VERSION ""

NS_ :

BS_:

BU_: Pbox IVIBOX ADU Tbox Cooling GW

BO_ 640 GPS_Longitude: 8 Pbox
 SG_ Longitude_Value : 7|32@0+ (1E-07,-180) [-180|180] "deg"  IVIBOX
 SG_ LongitudeSequenceNumber : 35|4@0+ (1,0) [0|15] ""  IVIBOX

BO_ 641 GPS_Latitude: 8 Pbox
 SG_ Latitude_Value : 7|32@0+ (1E-07,-90) [-90|90] "deg"  IVIBOX
 SG_ LatitudeSequenceNumber : 35|4@0+ (1,0) [0|15] ""  IVIBOX

BO_ 642 GPS_Speed: 8 Pbox
 SG_ Speed_Value : 7|16@0+ (0.1,0) [0|6425.5] "m/s"  IVIBOX
 SG_ SpeedSequenceNumber : 35|4@0+ (1,0) [0|15] ""  IVIBOX

BO_ 643 GPS_Heading: 8 Pbox
 SG_ Heading_Value : 7|12@0+ (0.1,0) [0|360] "deg"  IVIBOX
 SG_ BearingSequenceNumber : 35|4@0+ (1,0) [0|15] ""  IVIBOX

BO_ 646 GPS_Location_State: 8 Pbox
 SG_ Location_State_Valid : 1|2@0+ (1,0) [0|3] ""  IVIBOX
 SG_ ValidSequenceNumber : 5|4@0+ (1,0) [0|15] ""  IVIBOX

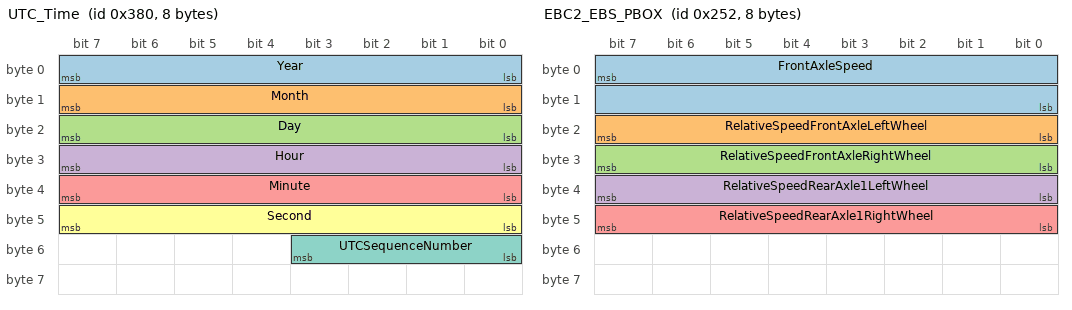
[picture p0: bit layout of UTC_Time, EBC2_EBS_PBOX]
BO_ 896 UTC_Time: 8 Pbox
 SG_ Year : 7|8@0+ (1,2000) [2000|2225] "Year"  IVIBOX,Tbox,Cooling,GW
 SG_ Month : 15|8@0+ (1,0) [1|12] "Month"  IVIBOX,Tbox,Cooling,GW
 SG_ Day : 23|8@0+ (1,0) [1|31] "Day"  IVIBOX,Tbox,Cooling,GW
 SG_ Hour : 31|8@0+ (1,0) [0|23] "Hour"  IVIBOX,Tbox,Cooling,GW
 SG_ Minute : 39|8@0+ (1,0) [0|59] "Minute"  IVIBOX,Tbox,Cooling,GW
 SG_ Second : 47|8@0+ (1,0) [0|59] "Second"  IVIBOX,Tbox,Cooling,GW
 SG_ UTCSequenceNumber : 51|4@0+ (1,0) [0|15] ""  IVIBOX,Tbox,Cooling,GW

BO_ 912 Vehicle_State_PBOX: 8 ADU
 SG_ TachographVehicleSpeed : 7|16@0+ (0.00390625,0) [0|250.996] "Km/h"  Pbox,IVIBOX,Tbox,Cooling

BO_ 592 ETC2_TCU_PBOX: 8 ADU
 SG_ ETC2_TrmCurrGr : 31|8@0+ (1,-125) [-125|125] "gear value"  Pbox,IVIBOX,Tbox

BO_ 593 VDC2_EBS_PBOX: 8 ADU
 SG_ SteeringWheelAngle : 7|16@0+ (0.0009765625,-31.374) [-31.374|31.374] "rad"  Pbox,IVIBOX
 SG_ YawRate : 23|16@0+ (0.0001220703125,-3.92) [-3.92|3.92] "rad/s"  Pbox,IVIBOX

BO_ 594 EBC2_EBS_PBOX: 8 ADU
 SG_ FrontAxleSpeed : 7|16@0+ (0.00390625,0) [0|250.996] "km/h"  Pbox,IVIBOX,Cooling
 SG_ RelativeSpeedFrontAxleLeftWheel : 23|8@0+ (0.0625,-7.8125) [-7.8125|7.8125] "km/h"  Pbox,IVIBOX
 SG_ RelativeSpeedFrontAxleRightWheel : 31|8@0+ (0.0625,-7.8125) [-7.8125|7.8125] "km/h"  Pbox,IVIBOX
 SG_ RelativeSpeedRearAxle1LeftWheel : 39|8@0+ (0.0625,-7.8125) [-7.8125|7.8125] "km/h"  Pbox,IVIBOX
 SG_ RelativeSpeedRearAxle1RightWheel : 47|8@0+ (0.0625,-7.8125) [-7.8125|7.8125] "km/h"  Pbox,IVIBOX

BO_ 913 VDHR_IC_PBOX: 8 ADU
 SG_ IC_HResolutionTotalVehiDist : 7|32@0+ (5,0) [0|21474836475] "m"  Pbox,IVIBOX,Tbox,Cooling

BO_ 981 SystemInfo: 8 Pbox
 SG_ MCUStartStatus : 2|3@0+ (1,0) [0|4] ""  ADU
 SG_ APStartStatus : 5|3@0+ (1,0) [0|4] ""  ADU
 SG_ PowerStatus : 7|2@0+ (1,0) [0|2] ""  ADU
 SG_ CANStatus : 8|1@0+ (1,0) [0|1] ""  ADU
 SG_ AntStatusM : 10|2@0+ (1,0) [0|2] ""  ADU
 SG_ AntPowerM : 11|1@0+ (1,0) [0|1] ""  ADU
 SG_ AntStatusS : 13|2@0+ (1,0) [0|2] ""  ADU
 SG_ AntPowerS : 14|1@0+ (1,0) [0|1] ""  ADU
 SG_ APStatus : 15|1@0+ (1,0) [0|1] ""  ADU
 SG_ EthLinkStatus : 17|2@0+ (1,0) [0|2] ""  ADU
 SG_ EthPhyStatus : 18|1@0+ (1,0) [0|1] ""  ADU
 SG_ ADUStatus : 19|1@0+ (1,0) [0|1] ""  ADU
 SG_ gPTPStatus : 20|1@0+ (1,0) [0|1] ""  ADU
 SG_ APTemperature : 31|8@0+ (1,-128) [-128|127] "℃"  ADU
 SG_ VolStatus : 39|12@0+ (1,0) [0|4095] ""  ADU
 SG_ RipleyMStatus : 52|5@0+ (1,0) [0|31] ""  ADU
 SG_ RipleySStatus : 41|5@0+ (1,0) [0|31] ""  ADU
 SG_ SystemInfo_RollingCounter : 63|4@0+ (1,0) [0|15] ""  ADU

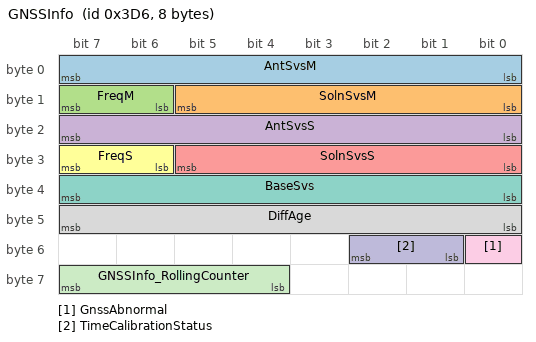
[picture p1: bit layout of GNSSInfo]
BO_ 982 GNSSInfo: 8 Pbox
 SG_ AntSvsM : 7|8@0+ (1,0) [0|255] ""  ADU
 SG_ SolnSvsM : 13|6@0+ (1,0) [0|63] ""  ADU
 SG_ FreqM : 15|2@0+ (1,0) [0|3] ""  ADU
 SG_ AntSvsS : 23|8@0+ (1,0) [0|255] ""  ADU
 SG_ SolnSvsS : 29|6@0+ (1,0) [0|63] ""  ADU
 SG_ FreqS : 31|2@0+ (1,0) [0|3] ""  ADU
 SG_ BaseSvs : 39|8@0+ (1,0) [0|255] ""  ADU
 SG_ DiffAge : 47|8@0+ (1,0) [0|255] "s"  ADU
 SG_ GnssAbnormal : 48|1@0+ (1,0) [0|1] ""  ADU
 SG_ TimeCalibrationStatus : 50|2@0+ (1,0) [0|2] ""  ADU
 SG_ GNSSInfo_RollingCounter : 63|4@0+ (1,0) [0|15] ""  ADU

BO_ 983 INSInfo: 8 Pbox
 SG_ InsResolve : 3|4@0+ (1,0) [0|11] ""  ADU
 SG_ InsAbnormal : 4|1@0+ (1,0) [0|1] ""  ADU
 SG_ ImuCali : 5|1@0+ (1,0) [0|1] ""  ADU
 SG_ ImuDataStatus_GYROX : 8|1@0+ (1,0) [0|1] ""  ADU
 SG_ ImuDataStatus_GYROY : 9|1@0+ (1,0) [0|1] ""  ADU
 SG_ ImuDataStatus_GYROZ : 10|1@0+ (1,0) [0|1] ""  ADU
 SG_ ImuDataStatus_ACCLX : 11|1@0+ (1,0) [0|1] ""  ADU
 SG_ ImuDataStatus_ACCLY : 12|1@0+ (1,0) [0|1] ""  ADU
 SG_ ImuDataStatus_ACCLZ : 13|1@0+ (1,0) [0|1] ""  ADU
 SG_ ImuDataStatus_TEMP : 14|1@0+ (1,0) [0|1] ""  ADU
 SG_ ImuDataStatus_TIME : 15|1@0+ (1,0) [0|1] ""  ADU
 SG_ ImuChipStatus : 23|8@0+ (1,0) [0|255] ""  ADU
 SG_ IMUTemperature : 31|8@0+ (1,-128) [-128|127] "℃"  ADU
 SG_ ImuFreq : 39|8@0+ (1,0) [0|255] ""  ADU
 SG_ ImuLostCnt : 47|8@0+ (1,0) [0|255] ""  ADU
 SG_ ImuErrCnt : 55|8@0+ (1,0) [0|255] ""  ADU
 SG_ INSInfo_RollingCounter : 63|4@0+ (1,0) [0|15] ""  ADU

CM_ "Version:V4.0.3,Date:2023.05.10,Author:xiuxiu.zhang,Review:,Approval:,Description:(Pbox)Pbox增加接收VDC2_EBS::YawRate；
增加接收EBC2_EBS::RelativeSpeedFrontAxleLeftWheel；
增加接收EBC2_EBS::RelativeSpeedFrontAxleRightWheel；
增加接收EBC2_EBS::RelativeSpeedRearAxle1LeftWheel；
增加接收EBC2_EBS::RelativeSpeedRearAxle1RightWheel；;
Version:V4.0.4,Date:2023.06.05,Author:xiuxiu.zhang,Review:,Approval:,Description:(Pbox)更新VDHR_IC的ID值为0x277，ADU发送，Cooling和Pbox接收;
Version:V4.0.4,Date:2023.06.05,Author:xiuxiu.zhang,Review:,Approval:,Description:(Pbox)Pbox增加接收Vehicle_State::TachographVehicleSpeed信号;
Version:V4.0.4,Date:2023.06.05,Author:xiuxiu.zhang,Review:,Approval:,Description:(Pbox)更新Pbox报文名称：GPS_Bearing更新为GPS_Heading，信号名称同步更改;
Version:V4.0.4,Date:2023.06.05,Author:xiuxiu.zhang,Review:,Approval:,Description:(Pbox)更新Pbox报文发送周期：GPS_Longitude、GPS_Latitude、GPS_Speed、GPS_Heading、GPS_Location_State由100ms更新为200ms;
Version:V4.0.4,Date:2023.06.05,Author:xiuxiu.zha";
CM_ SG_ 640 Longitude_Value "经度(东正西负)";
CM_ SG_ 640 LongitudeSequenceNumber "同步计数值";
CM_ SG_ 641 Latitude_Value "纬度（北正南负）";
CM_ SG_ 641 LatitudeSequenceNumber "同步计数值";
CM_ SG_ 642 Speed_Value "GPS车速";
CM_ SG_ 642 SpeedSequenceNumber "同步计数值";
CM_ SG_ 643 Heading_Value "前进方向（以真北为参考基准，顺时针为正）";
CM_ SG_ 643 BearingSequenceNumber "同步计数值";
CM_ SG_ 646 Location_State_Valid "定位有效性（含义取自GPRMC）";
CM_ SG_ 646 ValidSequenceNumber "同步计数值";
CM_ SG_ 896 UTCSequenceNumber "同步计数值";
CM_ SG_ 592 ETC2_TrmCurrGr "变速箱当前档位";
CM_ SG_ 594 RelativeSpeedFrontAxleLeftWheel "前轴左轮相对速度";
CM_ SG_ 594 RelativeSpeedFrontAxleRightWheel "前轴右轮相对速度";
CM_ SG_ 594 RelativeSpeedRearAxle1LeftWheel "后轴1左轮相对速度";
CM_ SG_ 594 RelativeSpeedRearAxle1RightWheel "后轴1右轮相对速度";
CM_ SG_ 913 IC_HResolutionTotalVehiDist "High Resolution Total Vehicle Distance1
高分辨率的总计里程1";
CM_ SG_ 981 MCUStartStatus "MCU启动状态";
CM_ SG_ 981 APStartStatus "AP启动状态";
CM_ SG_ 981 PowerStatus "供电状态";
CM_ SG_ 981 CANStatus "CAN通信状态";
CM_ SG_ 981 AntStatusM "主天线状态";
CM_ SG_ 981 AntPowerM "主天线供电状态";
CM_ SG_ 981 AntStatusS "从天线状态";
CM_ SG_ 981 AntPowerS "从天线供电状态";
CM_ SG_ 981 APStatus "AP工作状态";
CM_ SG_ 981 EthLinkStatus "以太网连接状态";
CM_ SG_ 981 EthPhyStatus "以太网PHY芯片状态";
CM_ SG_ 981 ADUStatus "ADU节点状态";
CM_ SG_ 981 gPTPStatus "gPTP时间同步状态";
CM_ SG_ 981 APTemperature "AP温度";
CM_ SG_ 981 VolStatus "内部电压检测状态";
CM_ SG_ 981 RipleyMStatus "主射频芯片状态";
CM_ SG_ 981 RipleySStatus "从射频芯片状态";
CM_ SG_ 981 SystemInfo_RollingCounter "报文计数";
CM_ SG_ 982 AntSvsM "主天线收星数";
CM_ SG_ 982 SolnSvsM "主天线参与解算卫星数";
CM_ SG_ 982 FreqM "主天线接收频点数";
CM_ SG_ 982 AntSvsS "从天线收星数";
CM_ SG_ 982 SolnSvsS "从天线参与解算卫星数";
CM_ SG_ 982 FreqS "从天线接收频点数";
CM_ SG_ 982 BaseSvs "基站卫星数";
CM_ SG_ 982 DiffAge "差分龄期";
CM_ SG_ 982 GnssAbnormal "Gnss状态";
CM_ SG_ 982 TimeCalibrationStatus "校时状态";
CM_ SG_ 982 GNSSInfo_RollingCounter "报文计数";
CM_ SG_ 983 InsResolve "Ins解算状态";
CM_ SG_ 983 InsAbnormal "Ins故障状态";
CM_ SG_ 983 ImuCali "IMU标定状态";
CM_ SG_ 983 ImuDataStatus_GYROX "IMU数据状态_陀螺仪X轴";
CM_ SG_ 983 ImuDataStatus_GYROY "IMU数据状态_陀螺仪Y轴";
CM_ SG_ 983 ImuDataStatus_GYROZ "IMU数据状态_陀螺仪Z轴";
CM_ SG_ 983 ImuDataStatus_ACCLX "IMU数据状态_加速度计X轴";
CM_ SG_ 983 ImuDataStatus_ACCLY "IMU数据状态_加速度计Y轴";
CM_ SG_ 983 ImuDataStatus_ACCLZ "IMU数据状态_加速度计Z轴";
CM_ SG_ 983 ImuDataStatus_TEMP "IMU数据状态_温度";
CM_ SG_ 983 ImuDataStatus_TIME "IMU数据状态_时间";
CM_ SG_ 983 ImuChipStatus "IMU芯片状态";
CM_ SG_ 983 IMUTemperature "IMU温度";
CM_ SG_ 983 ImuFreq "IMU数据频率";
CM_ SG_ 983 ImuLostCnt "IMU数据丢失计数";
CM_ SG_ 983 ImuErrCnt "IMU数据错误计数";
CM_ SG_ 983 INSInfo_RollingCounter "报文计数";
BA_DEF_ BO_  "GenMsgSendType" ENUM  "Cyclic","Event","IfActive","CE","CA","NoMsgSendType";
BA_DEF_ BO_  "GenMsgCycleTime" INT 0 0;
BA_DEF_ SG_  "GenSigSendType" ENUM  "Cyclic","OnChange","OnWrite","IfActive","OnChangeWithRepetition","OnWriteWithRepetition","IfActiveWithRepetition","NoSigSendType","OnChangeAndIfActive","OnChangeAndIfActiveWithRepetition","CA","CE","Event";
BA_DEF_ SG_  "GenSigStartValue" INT 0 0;
BA_DEF_  "DBName" STRING ;
BA_DEF_ BU_  "NodeLayerModules" STRING ;
BA_DEF_ BU_  "NmNode" ENUM  "Not","Yes";
BA_DEF_  "NmBaseAddress" HEX 0 2047;
BA_DEF_  "NmMessageCount" INT 0 255;
BA_DEF_  "BusType" STRING ;
BA_DEF_DEF_  "GenMsgSendType" "Cyclic";
BA_DEF_DEF_  "GenMsgCycleTime" 0;
BA_DEF_DEF_  "GenSigSendType" "Cyclic";
BA_DEF_DEF_  "GenSigStartValue" 0;
BA_DEF_DEF_  "DBName" "";
BA_DEF_DEF_  "NodeLayerModules" "CANoeILNLVector.dll";
BA_DEF_DEF_  "NmNode" "Not";
BA_DEF_DEF_  "NmBaseAddress" 1024;
BA_DEF_DEF_  "NmMessageCount" 128;
BA_DEF_DEF_  "BusType" "CAN";
BA_ "DBName" "CAN_Pbox";
BA_ "GenMsgCycleTime" BO_ 640 200;
BA_ "GenMsgCycleTime" BO_ 641 200;
BA_ "GenMsgCycleTime" BO_ 642 200;
BA_ "GenMsgCycleTime" BO_ 643 200;
BA_ "GenMsgCycleTime" BO_ 646 200;
BA_ "GenMsgCycleTime" BO_ 896 1000;
BA_ "GenMsgCycleTime" BO_ 912 200;
BA_ "GenMsgCycleTime" BO_ 592 100;
BA_ "GenMsgCycleTime" BO_ 593 20;
BA_ "GenMsgCycleTime" BO_ 594 100;
BA_ "GenMsgCycleTime" BO_ 913 200;
BA_ "GenMsgCycleTime" BO_ 981 1000;
BA_ "GenMsgCycleTime" BO_ 982 1000;
BA_ "GenMsgCycleTime" BO_ 983 1000;
BA_ "GenSigStartValue" SG_ 896 Month 1;
BA_ "GenSigStartValue" SG_ 896 Day 1;
BA_ "GenSigStartValue" SG_ 592 ETC2_TrmCurrGr 125;
BA_ "GenSigStartValue" SG_ 593 SteeringWheelAngle 32127;
BA_ "GenSigStartValue" SG_ 593 YawRate 32113;
BA_ "GenSigStartValue" SG_ 594 RelativeSpeedFrontAxleLeftWheel 125;
BA_ "GenSigStartValue" SG_ 594 RelativeSpeedFrontAxleRightWheel 125;
BA_ "GenSigStartValue" SG_ 594 RelativeSpeedRearAxle1LeftWheel 125;
BA_ "GenSigStartValue" SG_ 594 RelativeSpeedRearAxle1RightWheel 125;
VAL_ 640 Longitude_Value -1 "Invalid" ;
VAL_ 641 Latitude_Value -1 "Invalid" ;
VAL_ 642 Speed_Value 65535 "Invalid" ;
VAL_ 643 Heading_Value 4095 "Invalid" ;
VAL_ 646 Location_State_Valid 1 "Valid" 0 "Invalid" ;
VAL_ 981 MCUStartStatus 4 "MCU APP Init Finish, MCU APP is Working" 3 "MCU Power Up AP Finish" 2 "MCU APP Init Start" 1 "MCU BOOT Start Finish" 0 "Default" ;
VAL_ 981 APStartStatus 4 "AP is Working" 3 "AP App Start Finish" 2 "AP Image Start Finish" 1 "AP boot Start Finish" 0 "Default" ;
VAL_ 981 PowerStatus 2 "ECU Input Voltage too High" 1 "ECU Input Voltage too Low" 0 "Normal" ;
VAL_ 981 CANStatus 1 "DMI Data Lost" 0 "Normal" ;
VAL_ 981 AntStatusM 2 "Short" 1 "Open" 0 "Normal" ;
VAL_ 981 AntPowerM 1 "Abnormal" 0 "Normal" ;
VAL_ 981 AntStatusS 2 "Short" 1 "Open" 0 "Normal" ;
VAL_ 981 AntPowerS 1 "Abnormal" 0 "Normal" ;
VAL_ 981 APStatus 1 "AP Working Abnormally" 0 "Normal" ;
VAL_ 981 EthLinkStatus 2 "Short" 1 "Open" 0 "Normal" ;
VAL_ 981 EthPhyStatus 1 "Link Down" 0 "Normal" ;
VAL_ 981 ADUStatus 1 "ADU Node Lost" 0 "Normal" ;
VAL_ 981 gPTPStatus 1 "Abnormal" 0 "Normal" ;
VAL_ 981 VolStatus 4095 "Inside Voltage Abnormal" 4094 "Inside Voltage Abnormal" 4093 "Inside Voltage Abnormal" 4092 "Inside Voltage Abnormal" 4091 "Inside Voltage Abnormal" 4090 "Inside Voltage Abnormal" 4089 "Inside Voltage Abnormal" 4088 "Inside Voltage Abnormal" 4087 "Inside Voltage Abnormal" 4086 "Inside Voltage Abnormal" 4085 "Inside Voltage Abnormal" 4084 "Inside Voltage Abnormal" 4083 "Inside Voltage Abnormal" 4082 "Inside Voltage Abnormal" 4081 "Inside Voltage Abnormal" 4080 "Inside Voltage Abnormal" 4079 "Inside Voltage Abnormal" 4078 "Inside Voltage Abnormal" 4077 "Inside Voltage Abnormal" 4076 "Inside Voltage Abnormal" 4075 "Inside Voltage Abnormal" 4074 "Inside Voltage Abnormal" 4073 "Inside Voltage Abnormal" 4072 "Inside Voltage Abnormal" 4071 "Inside Voltage Abnormal" 4070 "Inside Voltage Abnormal" 4069 "Inside Voltage Abnormal" 4068 "Inside Voltage Abnormal" 4067 "Inside Voltage Abnormal" 4066 "Inside Voltage Abnormal" 4065 "Inside Voltage Abnormal" 4064 "Inside Voltage Abnormal" 4063 "Inside Voltage Abnormal" 4062 "Inside Voltage Abnormal" 4061 "Inside Voltage Abnormal" 4060 "Inside Voltage Abnormal" 4059 "Inside Voltage Abnormal" 4058 "Inside Voltage Abnormal" 4057 "Inside Voltage Abnormal" 4056 "Inside Voltage Abnormal" 4055 "Inside Voltage Abnormal" 4054 "Inside Voltage Abnormal" 4053 "Inside Voltage Abnormal" 4052 "Inside Voltage Abnormal" 4051 "Inside Voltage Abnormal" 4050 "Inside Voltage Abnormal" 4049 "Inside Voltage Abnormal" 4048 "Inside Voltage Abnormal" 4047 "Inside Voltage Abnormal" 4046 "Inside Voltage Abnormal" 4045 "Inside Voltage Abnormal" 4044 "Inside Voltage Abnormal" 4043 "Inside Voltage Abnormal" 4042 "Inside Voltage Abnormal" 4041 "Inside Voltage Abnormal" 4040 "Inside Voltage Abnormal" 4039 "Inside Voltage Abnormal" 4038 "Inside Voltage Abnormal" 4037 "Inside Voltage Abnormal" 4036 "Inside Voltage Abnormal" 4035 "Inside Voltage Abnormal" 4034 "Inside Voltage Abnormal" 4033 "Inside Voltage Abnormal" 4032 "Inside Voltage Abnormal" 4031 "Inside Voltage Abnormal" 4030 "Inside Voltage Abnormal" 4029 "Inside Voltage Abnormal" 4028 "Inside Voltage Abnormal" 4027 "Inside Voltage Abnormal" 4026 "Inside Voltage Abnormal" 4025 "Inside Voltage Abnormal" 4024 "Inside Voltage Abnormal" 4023 "Inside Voltage Abnormal" 4022 "Inside Voltage Abnormal" 4021 "Inside Voltage Abnormal" 4020 "Inside Voltage Abnormal" 4019 "Inside Voltage Abnormal" 4018 "Inside Voltage Abnormal" 4017 "Inside Voltage Abnormal" 4016 "Inside Voltage Abnormal" 4015 "Inside Voltage Abnormal" 4014 "Inside Voltage Abnormal" 4013 "Inside Voltage Abnormal" 4012 "Inside Voltage Abnormal" 4011 "Inside Voltage Abnormal" 4010 "Inside Voltage Abnormal" 4009 "Inside Voltage Abnormal" 4008 "Inside Voltage Abnormal" 4007 "Inside Voltage Abnormal" 4006 "Inside Voltage Abnormal" 4005 "Inside Voltage Abnormal" 4004 "Inside Voltage Abnormal" 4003 "Inside Voltage Abnormal" 4002 "Inside Voltage Abnormal" 4001 "Inside Voltage Abnormal" 4000 "Inside Voltage Abnormal" 3999 "Inside Voltage Abnormal" 3998 "Inside Voltage Abnormal" 3997 "Inside Voltage Abnormal" 3996 "Inside Voltage Abnormal" 3995 "Inside Voltage Abnormal" 3994 "Inside Voltage Abnormal" 3993 "Inside Voltage Abnormal" 3992 "Inside Voltage Abnormal" 3991 "Inside Voltage Abnormal" 3990 "Inside Voltage Abnormal" 3989 "Inside Voltage Abnormal" 3988 "Inside Voltage Abnormal" 3987 "Inside Voltage Abnormal" 3986 "Inside Voltage Abnormal" 3985 "Inside Voltage Abnormal" 3984 "Inside Voltage Abnormal" 3983 "Inside Voltage Abnormal" 3982 "Inside Voltage Abnormal" 3981 "Inside Voltage Abnormal" 3980 "Inside Voltage Abnormal" 3979 "Inside Voltage Abnormal" 3978 "Inside Voltage Abnormal" 3977 "Inside Voltage Abnormal" 3976 "Inside Voltage Abnormal" 3975 "Inside Voltage Abnormal" 3974 "Inside Voltage Abnormal" 3973 "Inside Voltage Abnormal" 3972 "Inside Voltage Abnormal" 3971 "Inside Voltage Abnormal" 3970 "Inside Voltage Abnormal" 3969 "Inside Voltage Abnormal" 3968 "Inside Voltage Abnormal" 3967 "Inside Voltage Abnormal" 3966 "Inside Voltage Abnormal" 3965 "Inside Voltage Abnormal" 3964 "Inside Voltage Abnormal" 3963 "Inside Voltage Abnormal" 3962 "Inside Voltage Abnormal" 3961 "Inside Voltage Abnormal" 3960 "Inside Voltage Abnormal" 3959 "Inside Voltage Abnormal" 3958 "Inside Voltage Abnormal" 3957 "Inside Voltage Abnormal" 3956 "Inside Voltage Abnormal" 3955 "Inside Voltage Abnormal" 3954 "Inside Voltage Abnormal" 3953 "Inside Voltage Abnormal" 3952 "Inside Voltage Abnormal" 3951 "Inside Voltage Abnormal" 3950 "Inside Voltage Abnormal" 3949 "Inside Voltage Abnormal" 3948 "Inside Voltage Abnormal" 3947 "Inside Voltage Abnormal" 3946 "Inside Voltage Abnormal" 3945 "Inside Voltage Abnormal" 3944 "Inside Voltage Abnormal" 3943 "Inside Voltage Abnormal" 3942 "Inside Voltage Abnormal" 3941 "Inside Voltage Abnormal" 3940 "Inside Voltage Abnormal" 3939 "Inside Voltage Abnormal" 3938 "Inside Voltage Abnormal" 3937 "Inside Voltage Abnormal" 3936 "Inside Voltage Abnormal" 3935 "Inside Voltage Abnormal" 3934 "Inside Voltage Abnormal" 3933 "Inside Voltage Abnormal" 3932 "Inside Voltage Abnormal" 3931 "Inside Voltage Abnormal" 3930 "Inside Voltage Abnormal" 3929 "Inside Voltage Abnormal" 3928 "Inside Voltage Abnormal" 3927 "Inside Voltage Abnormal" 3926 "Inside Voltage Abnormal" 3925 "Inside Voltage Abnormal" 3924 "Inside Voltage Abnormal" 3923 "Inside Voltage Abnormal" 3922 "Inside Voltage Abnormal" 3921 "Inside Voltage Abnormal" 3920 "Inside Voltage Abnormal" 3919 "Inside Voltage Abnormal" 3918 "Inside Voltage Abnormal" 3917 "Inside Voltage Abnormal" 3916 "Inside Voltage Abnormal" 3915 "Inside Voltage Abnormal" 3914 "Inside Voltage Abnormal" 3913 "Inside Voltage Abnormal" 3912 "Inside Voltage Abnormal" 3911 "Inside Voltage Abnormal" 3910 "Inside Voltage Abnormal" 3909 "Inside Voltage Abnormal" 3908 "Inside Voltage Abnormal" 3907 "Inside Voltage Abnormal" 3906 "Inside Voltage Abnormal" 3905 "Inside Voltage Abnormal" 3904 "Inside Voltage Abnormal" 3903 "Inside Voltage Abnormal" 3902 "Inside Voltage Abnormal" 3901 "Inside Voltage Abnormal" 3900 "Inside Voltage Abnormal" 3899 "Inside Voltage Abnormal" 3898 "Inside Voltage Abnormal" 3897 "Inside Voltage Abnormal" 3896 "Inside Voltage Abnormal" 3895 "Inside Voltage Abnormal" 3894 "Inside Voltage Abnormal" 3893 "Inside Voltage Abnormal" 3892 "Inside Voltage Abnormal" 3891 "Inside Voltage Abnormal" 3890 "Inside Voltage Abnormal" 3889 "Inside Voltage Abnormal" 3888 "Inside Voltage Abnormal" 3887 "Inside Voltage Abnormal" 3886 "Inside Voltage Abnormal" 3885 "Inside Voltage Abnormal" 3884 "Inside Voltage Abnormal" 3883 "Inside Voltage Abnormal" 3882 "Inside Voltage Abnormal" 3881 "Inside Voltage Abnormal" 3880 "Inside Voltage Abnormal" 3879 "Inside Voltage Abnormal" 3878 "Inside Voltage Abnormal" 3877 "Inside Voltage Abnormal" 3876 "Inside Voltage Abnormal" 3875 "Inside Voltage Abnormal" 3874 "Inside Voltage Abnormal" 3873 "Inside Voltage Abnormal" 3872 "Inside Voltage Abnormal" 3871 "Inside Voltage Abnormal" 3870 "Inside Voltage Abnormal" 3869 "Inside Voltage Abnormal" 3868 "Inside Voltage Abnormal" 3867 "Inside Voltage Abnormal" 3866 "Inside Voltage Abnormal" 3865 "Inside Voltage Abnormal" 3864 "Inside Voltage Abnormal" 3863 "Inside Voltage Abnormal" 3862 "Inside Voltage Abnormal" 3861 "Inside Voltage Abnormal" 3860 "Inside Voltage Abnormal" 3859 "Inside Voltage Abnormal" 3858 "Inside Voltage Abnormal" 3857 "Inside Voltage Abnormal" 3856 "Inside Voltage Abnormal" 3855 "Inside Voltage Abnormal" 3854 "Inside Voltage Abnormal" 3853 "Inside Voltage Abnormal" 3852 "Inside Voltage Abnormal" 3851 "Inside Voltage Abnormal" 3850 "Inside Voltage Abnormal" 3849 "Inside Voltage Abnormal" 3848 "Inside Voltage Abnormal" 3847 "Inside Voltage Abnormal" 3846 "Inside Voltage Abnormal" 3845 "Inside Voltage Abnormal" 3844 "Inside Voltage Abnormal" 3843 "Inside Voltage Abnormal" 3842 "Inside Voltage Abnormal" 3841 "Inside Voltage Abnormal" 3840 "Inside Voltage Abnormal" 3839 "Inside Voltage Abnormal" 3838 "Inside Voltage Abnormal" 3837 "Inside Voltage Abnormal" 3836 "Inside Voltage Abnormal" 3835 "Inside Voltage Abnormal" 3834 "Inside Voltage Abnormal" 3833 "Inside Voltage Abnormal" 3832 "Inside Voltage Abnormal" 3831 "Inside Voltage Abnormal" 3830 "Inside Voltage Abnormal" 3829 "Inside Voltage Abnormal" 3828 "Inside Voltage Abnormal" 3827 "Inside Voltage Abnormal" 3826 "Inside Voltage Abnormal" 3825 "Inside Voltage Abnormal" 3824 "Inside Voltage Abnormal" 3823 "Inside Voltage Abnormal" 3822 "Inside Voltage Abnormal" 3821 "Inside Voltage Abnormal" 3820 "Inside Voltage Abnormal" 3819 "Inside Voltage Abnormal" 3818 "Inside Voltage Abnormal" 3817 "Inside Voltage Abnormal" 3816 "Inside Voltage Abnormal" 3815 "Inside Voltage Abnormal" 3814 "Inside Voltage Abnormal" 3813 "Inside Voltage Abnormal" 3812 "Inside Voltage Abnormal" 3811 "Inside Voltage Abnormal" 3810 "Inside Voltage Abnormal" 3809 "Inside Voltage Abnormal" 3808 "Inside Voltage Abnormal" 3807 "Inside Voltage Abnormal" 3806 "Inside Voltage Abnormal" 3805 "Inside Voltage Abnormal" 3804 "Inside Voltage Abnormal" 3803 "Inside Voltage Abnormal" 3802 "Inside Voltage Abnormal" 3801 "Inside Voltage Abnormal" 3800 "Inside Voltage Abnormal" 3799 "Inside Voltage Abnormal" 3798 "Inside Voltage Abnormal" 3797 "Inside Voltage Abnormal" 3796 "Inside Voltage Abnormal" 3795 "Inside Voltage Abnormal" 3794 "Inside Voltage Abnormal" 3793 "Inside Voltage Abnormal" 3792 "Inside Voltage Abnormal" 3791 "Inside Voltage Abnormal" 3790 "Inside Voltage Abnormal" 3789 "Inside Voltage Abnormal" 3788 "Inside Voltage Abnormal" 3787 "Inside Voltage Abnormal" 3786 "Inside Voltage Abnormal" 3785 "Inside Voltage Abnormal" 3784 "Inside Voltage Abnormal" 3783 "Inside Voltage Abnormal" 3782 "Inside Voltage Abnormal" 3781 "Inside Voltage Abnormal" 3780 "Inside Voltage Abnormal" 3779 "Inside Voltage Abnormal" 3778 "Inside Voltage Abnormal" 3777 "Inside Voltage Abnormal" 3776 "Inside Voltage Abnormal" 3775 "Inside Voltage Abnormal" 3774 "Inside Voltage Abnormal" 3773 "Inside Voltage Abnormal" 3772 "Inside Voltage Abnormal" 3771 "Inside Voltage Abnormal" 3770 "Inside Voltage Abnormal" 3769 "Inside Voltage Abnormal" 3768 "Inside Voltage Abnormal" 3767 "Inside Voltage Abnormal" 3766 "Inside Voltage Abnormal" 3765 "Inside Voltage Abnormal" 3764 "Inside Voltage Abnormal" 3763 "Inside Voltage Abnormal" 3762 "Inside Voltage Abnormal" 3761 "Inside Voltage Abnormal" 3760 "Inside Voltage Abnormal" 3759 "Inside Voltage Abnormal" 3758 "Inside Voltage Abnormal" 3757 "Inside Voltage Abnormal" 3756 "Inside Voltage Abnormal" 3755 "Inside Voltage Abnormal" 3754 "Inside Voltage Abnormal" 3753 "Inside Voltage Abnormal" 3752 "Inside Voltage Abnormal" 3751 "Inside Voltage Abnormal" 3750 "Inside Voltage Abnormal" 3749 "Inside Voltage Abnormal" 3748 "Inside Voltage Abnormal" 3747 "Inside Voltage Abnormal" 3746 "Inside Voltage Abnormal" 3745 "Inside Voltage Abnormal" 3744 "Inside Voltage Abnormal" 3743 "Inside Voltage Abnormal" 3742 "Inside Voltage Abnormal" 3741 "Inside Voltage Abnormal" 3740 "Inside Voltage Abnormal" 3739 "Inside Voltage Abnormal" 3738 "Inside Voltage Abnormal" 3737 "Inside Voltage Abnormal" 3736 "Inside Voltage Abnormal" 3735 "Inside Voltage Abnormal" 3734 "Inside Voltage Abnormal" 3733 "Inside Voltage Abnormal" 3732 "Inside Voltage Abnormal" 3731 "Inside Voltage Abnormal" 3730 "Inside Voltage Abnormal" 3729 "Inside Voltage Abnormal" 3728 "Inside Voltage Abnormal" 3727 "Inside Voltage Abnormal" 3726 "Inside Voltage Abnormal" 3725 "Inside Voltage Abnormal" 3724 "Inside Voltage Abnormal" 3723 "Inside Voltage Abnormal" 3722 "Inside Voltage Abnormal" 3721 "Inside Voltage Abnormal" 3720 "Inside Voltage Abnormal" 3719 "Inside Voltage Abnormal" 3718 "Inside Voltage Abnormal" 3717 "Inside Voltage Abnormal" 3716 "Inside Voltage Abnormal" 3715 "Inside Voltage Abnormal" 3714 "Inside Voltage Abnormal" 3713 "Inside Voltage Abnormal" 3712 "Inside Voltage Abnormal" 3711 "Inside Voltage Abnormal" 3710 "Inside Voltage Abnormal" 3709 "Inside Voltage Abnormal" 3708 "Inside Voltage Abnormal" 3707 "Inside Voltage Abnormal" 3706 "Inside Voltage Abnormal" 3705 "Inside Voltage Abnormal" 3704 "Inside Voltage Abnormal" 3703 "Inside Voltage Abnormal" 3702 "Inside Voltage Abnormal" 3701 "Inside Voltage Abnormal" 3700 "Inside Voltage Abnormal" 3699 "Inside Voltage Abnormal" 3698 "Inside Voltage Abnormal" 3697 "Inside Voltage Abnormal" 3696 "Inside Voltage Abnormal" 3695 "Inside Voltage Abnormal" 3694 "Inside Voltage Abnormal" 3693 "Inside Voltage Abnormal" 3692 "Inside Voltage Abnormal" 3691 "Inside Voltage Abnormal" 3690 "Inside Voltage Abnormal" 3689 "Inside Voltage Abnormal" 3688 "Inside Voltage Abnormal" 3687 "Inside Voltage Abnormal" 3686 "Inside Voltage Abnormal" 3685 "Inside Voltage Abnormal" 3684 "Inside Voltage Abnormal" 3683 "Inside Voltage Abnormal" 3682 "Inside Voltage Abnormal" 3681 "Inside Voltage Abnormal" 3680 "Inside Voltage Abnormal" 3679 "Inside Voltage Abnormal" 3678 "Inside Voltage Abnormal" 3677 "Inside Voltage Abnormal" 3676 "Inside Voltage Abnormal" 3675 "Inside Voltage Abnormal" 3674 "Inside Voltage Abnormal" 3673 "Inside Voltage Abnormal" 3672 "Inside Voltage Abnormal" 3671 "Inside Voltage Abnormal" 3670 "Inside Voltage Abnormal" 3669 "Inside Voltage Abnormal" 3668 "Inside Voltage Abnormal" 3667 "Inside Voltage Abnormal" 3666 "Inside Voltage Abnormal" 3665 "Inside Voltage Abnormal" 3664 "Inside Voltage Abnormal" 3663 "Inside Voltage Abnormal" 3662 "Inside Voltage Abnormal" 3661 "Inside Voltage Abnormal" 3660 "Inside Voltage Abnormal" 3659 "Inside Voltage Abnormal" 3658 "Inside Voltage Abnormal" 3657 "Inside Voltage Abnormal" 3656 "Inside Voltage Abnormal" 3655 "Inside Voltage Abnormal" 3654 "Inside Voltage Abnormal" 3653 "Inside Voltage Abnormal" 3652 "Inside Voltage Abnormal" 3651 "Inside Voltage Abnormal" 3650 "Inside Voltage Abnormal" 3649 "Inside Voltage Abnormal" 3648 "Inside Voltage Abnormal" 3647 "Inside Voltage Abnormal" 3646 "Inside Voltage Abnormal" 3645 "Inside Voltage Abnormal" 3644 "Inside Voltage Abnormal" 3643 "Inside Voltage Abnormal" 3642 "Inside Voltage Abnormal" 3641 "Inside Voltage Abnormal" 3640 "Inside Voltage Abnormal" 3639 "Inside Voltage Abnormal" 3638 "Inside Voltage Abnormal" 3637 "Inside Voltage Abnormal" 3636 "Inside Voltage Abnormal" 3635 "Inside Voltage Abnormal" 3634 "Inside Voltage Abnormal" 3633 "Inside Voltage Abnormal" 3632 "Inside Voltage Abnormal" 3631 "Inside Voltage Abnormal" 3630 "Inside Voltage Abnormal" 3629 "Inside Voltage Abnormal" 3628 "Inside Voltage Abnormal" 3627 "Inside Voltage Abnormal" 3626 "Inside Voltage Abnormal" 3625 "Inside Voltage Abnormal" 3624 "Inside Voltage Abnormal" 3623 "Inside Voltage Abnormal" 3622 "Inside Voltage Abnormal" 3621 "Inside Voltage Abnormal" 3620 "Inside Voltage Abnormal" 3619 "Inside Voltage Abnormal" 3618 "Inside Voltage Abnormal" 3617 "Inside Voltage Abnormal" 3616 "Inside Voltage Abnormal" 3615 "Inside Voltage Abnormal" 3614 "Inside Voltage Abnormal" 3613 "Inside Voltage Abnormal" 3612 "Inside Voltage Abnormal" 3611 "Inside Voltage Abnormal" 3610 "Inside Voltage Abnormal" 3609 "Inside Voltage Abnormal" 3608 "Inside Voltage Abnormal" 3607 "Inside Voltage Abnormal" 3606 "Inside Voltage Abnormal" 3605 "Inside Voltage Abnormal" 3604 "Inside Voltage Abnormal" 3603 "Inside Voltage Abnormal" 3602 "Inside Voltage Abnormal" 3601 "Inside Voltage Abnormal" 3600 "Inside Voltage Abnormal" 3599 "Inside Voltage Abnormal" 3598 "Inside Voltage Abnormal" 3597 "Inside Voltage Abnormal" 3596 "Inside Voltage Abnormal" 3595 "Inside Voltage Abnormal" 3594 "Inside Voltage Abnormal" 3593 "Inside Voltage Abnormal" 3592 "Inside Voltage Abnormal" 3591 "Inside Voltage Abnormal" 3590 "Inside Voltage Abnormal" 3589 "Inside Voltage Abnormal" 3588 "Inside Voltage Abnormal" 3587 "Inside Voltage Abnormal" 3586 "Inside Voltage Abnormal" 3585 "Inside Voltage Abnormal" 3584 "Inside Voltage Abnormal" 3583 "Inside Voltage Abnormal" 3582 "Inside Voltage Abnormal" 3581 "Inside Voltage Abnormal" 3580 "Inside Voltage Abnormal" 3579 "Inside Voltage Abnormal" 3578 "Inside Voltage Abnormal" 3577 "Inside Voltage Abnormal" 3576 "Inside Voltage Abnormal" 3575 "Inside Voltage Abnormal" 3574 "Inside Voltage Abnormal" 3573 "Inside Voltage Abnormal" 3572 "Inside Voltage Abnormal" 3571 "Inside Voltage Abnormal" 3570 "Inside Voltage Abnormal" 3569 "Inside Voltage Abnormal" 3568 "Inside Voltage Abnormal" 3567 "Inside Voltage Abnormal" 3566 "Inside Voltage Abnormal" 3565 "Inside Voltage Abnormal" 3564 "Inside Voltage Abnormal" 3563 "Inside Voltage Abnormal" 3562 "Inside Voltage Abnormal" 3561 "Inside Voltage Abnormal" 3560 "Inside Voltage Abnormal" 3559 "Inside Voltage Abnormal" 3558 "Inside Voltage Abnormal" 3557 "Inside Voltage Abnormal" 3556 "Inside Voltage Abnormal" 3555 "Inside Voltage Abnormal" 3554 "Inside Voltage Abnormal" 3553 "Inside Voltage Abnormal" 3552 "Inside Voltage Abnormal" 3551 "Inside Voltage Abnormal" 3550 "Inside Voltage Abnormal" 3549 "Inside Voltage Abnormal" 3548 "Inside Voltage Abnormal" 3547 "Inside Voltage Abnormal" 3546 "Inside Voltage Abnormal" 3545 "Inside Voltage Abnormal" 3544 "Inside Voltage Abnormal" 3543 "Inside Voltage Abnormal" 3542 "Inside Voltage Abnormal" 3541 "Inside Voltage Abnormal" 3540 "Inside Voltage Abnormal" 3539 "Inside Voltage Abnormal" 3538 "Inside Voltage Abnormal" 3537 "Inside Voltage Abnormal" 3536 "Inside Voltage Abnormal" 3535 "Inside Voltage Abnormal" 3534 "Inside Voltage Abnormal" 3533 "Inside Voltage Abnormal" 3532 "Inside Voltage Abnormal" 3531 "Inside Voltage Abnormal" 3530 "Inside Voltage Abnormal" 3529 "Inside Voltage Abnormal" 3528 "Inside Voltage Abnormal" 3527 "Inside Voltage Abnormal" 3526 "Inside Voltage Abnormal" 3525 "Inside Voltage Abnormal" 3524 "Inside Voltage Abnormal" 3523 "Inside Voltage Abnormal" 3522 "Inside Voltage Abnormal" 3521 "Inside Voltage Abnormal" 3520 "Inside Voltage Abnormal" 3519 "Inside Voltage Abnormal" 3518 "Inside Voltage Abnormal" 3517 "Inside Voltage Abnormal" 3516 "Inside Voltage Abnormal" 3515 "Inside Voltage Abnormal" 3514 "Inside Voltage Abnormal" 3513 "Inside Voltage Abnormal" 3512 "Inside Voltage Abnormal" 3511 "Inside Voltage Abnormal" 3510 "Inside Voltage Abnormal" 3509 "Inside Voltage Abnormal" 3508 "Inside Voltage Abnormal" 3507 "Inside Voltage Abnormal" 3506 "Inside Voltage Abnormal" 3505 "Inside Voltage Abnormal" 3504 "Inside Voltage Abnormal" 3503 "Inside Voltage Abnormal" 3502 "Inside Voltage Abnormal" 3501 "Inside Voltage Abnormal" 3500 "Inside Voltage Abnormal" 3499 "Inside Voltage Abnormal" 3498 "Inside Voltage Abnormal" 3497 "Inside Voltage Abnormal" 3496 "Inside Voltage Abnormal" 3495 "Inside Voltage Abnormal" 3494 "Inside Voltage Abnormal" 3493 "Inside Voltage Abnormal" 3492 "Inside Voltage Abnormal" 3491 "Inside Voltage Abnormal" 3490 "Inside Voltage Abnormal" 3489 "Inside Voltage Abnormal" 3488 "Inside Voltage Abnormal" 3487 "Inside Voltage Abnormal" 3486 "Inside Voltage Abnormal" 3485 "Inside Voltage Abnormal" 3484 "Inside Voltage Abnormal" 3483 "Inside Voltage Abnormal" 3482 "Inside Voltage Abnormal" 3481 "Inside Voltage Abnormal" 3480 "Inside Voltage Abnormal" 3479 "Inside Voltage Abnormal" 3478 "Inside Voltage Abnormal" 3477 "Inside Voltage Abnormal" 3476 "Inside Voltage Abnormal" 3475 "Inside Voltage Abnormal" 3474 "Inside Voltage Abnormal" 3473 "Inside Voltage Abnormal" 3472 "Inside Voltage Abnormal" 3471 "Inside Voltage Abnormal" 3470 "Inside Voltage Abnormal" 3469 "Inside Voltage Abnormal" 3468 "Inside Voltage Abnormal" 3467 "Inside Voltage Abnormal" 3466 "Inside Voltage Abnormal" 3465 "Inside Voltage Abnormal" 3464 "Inside Voltage Abnormal" 3463 "Inside Voltage Abnormal" 3462 "Inside Voltage Abnormal" 3461 "Inside Voltage Abnormal" 3460 "Inside Voltage Abnormal" 3459 "Inside Voltage Abnormal" 3458 "Inside Voltage Abnormal" 3457 "Inside Voltage Abnormal" 3456 "Inside Voltage Abnormal" 3455 "Inside Voltage Abnormal" 3454 "Inside Voltage Abnormal" 3453 "Inside Voltage Abnormal" 3452 "Inside Voltage Abnormal" 3451 "Inside Voltage Abnormal" 3450 "Inside Voltage Abnormal" 3449 "Inside Voltage Abnormal" 3448 "Inside Voltage Abnormal" 3447 "Inside Voltage Abnormal" 3446 "Inside Voltage Abnormal" 3445 "Inside Voltage Abnormal" 3444 "Inside Voltage Abnormal" 3443 "Inside Voltage Abnormal" 3442 "Inside Voltage Abnormal" 3441 "Inside Voltage Abnormal" 3440 "Inside Voltage Abnormal" 3439 "Inside Voltage Abnormal" 3438 "Inside Voltage Abnormal" 3437 "Inside Voltage Abnormal" 3436 "Inside Voltage Abnormal" 3435 "Inside Voltage Abnormal" 3434 "Inside Voltage Abnormal" 3433 "Inside Voltage Abnormal" 3432 "Inside Voltage Abnormal" 3431 "Inside Voltage Abnormal" 3430 "Inside Voltage Abnormal" 3429 "Inside Voltage Abnormal" 3428 "Inside Voltage Abnormal" 3427 "Inside Voltage Abnormal" 3426 "Inside Voltage Abnormal" 3425 "Inside Voltage Abnormal" 3424 "Inside Voltage Abnormal" 3423 "Inside Voltage Abnormal" 3422 "Inside Voltage Abnormal" 3421 "Inside Voltage Abnormal" 3420 "Inside Voltage Abnormal" 3419 "Inside Voltage Abnormal" 3418 "Inside Voltage Abnormal" 3417 "Inside Voltage Abnormal" 3416 "Inside Voltage Abnormal" 3415 "Inside Voltage Abnormal" 3414 "Inside Voltage Abnormal" 3413 "Inside Voltage Abnormal" 3412 "Inside Voltage Abnormal" 3411 "Inside Voltage Abnormal" 3410 "Inside Voltage Abnormal" 3409 "Inside Voltage Abnormal" 3408 "Inside Voltage Abnormal" 3407 "Inside Voltage Abnormal" 3406 "Inside Voltage Abnormal" 3405 "Inside Voltage Abnormal" 3404 "Inside Voltage Abnormal" 3403 "Inside Voltage Abnormal" 3402 "Inside Voltage Abnormal" 3401 "Inside Voltage Abnormal" 3400 "Inside Voltage Abnormal" 3399 "Inside Voltage Abnormal" 3398 "Inside Voltage Abnormal" 3397 "Inside Voltage Abnormal" 3396 "Inside Voltage Abnormal" 3395 "Inside Voltage Abnormal" 3394 "Inside Voltage Abnormal" 3393 "Inside Voltage Abnormal" 3392 "Inside Voltage Abnormal" 3391 "Inside Voltage Abnormal" 3390 "Inside Voltage Abnormal" 3389 "Inside Voltage Abnormal" 3388 "Inside Voltage Abnormal" 3387 "Inside Voltage Abnormal" 3386 "Inside Voltage Abnormal" 3385 "Inside Voltage Abnormal" 3384 "Inside Voltage Abnormal" 3383 "Inside Voltage Abnormal" 3382 "Inside Voltage Abnormal" 3381 "Inside Voltage Abnormal" 3380 "Inside Voltage Abnormal" 3379 "Inside Voltage Abnormal" 3378 "Inside Voltage Abnormal" 3377 "Inside Voltage Abnormal" 3376 "Inside Voltage Abnormal" 3375 "Inside Voltage Abnormal" 3374 "Inside Voltage Abnormal" 3373 "Inside Voltage Abnormal" 3372 "Inside Voltage Abnormal" 3371 "Inside Voltage Abnormal" 3370 "Inside Voltage Abnormal" 3369 "Inside Voltage Abnormal" 3368 "Inside Voltage Abnormal" 3367 "Inside Voltage Abnormal" 3366 "Inside Voltage Abnormal" 3365 "Inside Voltage Abnormal" 3364 "Inside Voltage Abnormal" 3363 "Inside Voltage Abnormal" 3362 "Inside Voltage Abnormal" 3361 "Inside Voltage Abnormal" 3360 "Inside Voltage Abnormal" 3359 "Inside Voltage Abnormal" 3358 "Inside Voltage Abnormal" 3357 "Inside Voltage Abnormal" 3356 "Inside Voltage Abnormal" 3355 "Inside Voltage Abnormal" 3354 "Inside Voltage Abnormal" 3353 "Inside Voltage Abnormal" 3352 "Inside Voltage Abnormal" 3351 "Inside Voltage Abnormal" 3350 "Inside Voltage Abnormal" 3349 "Inside Voltage Abnormal" 3348 "Inside Voltage Abnormal" 3347 "Inside Voltage Abnormal" 3346 "Inside Voltage Abnormal" 3345 "Inside Voltage Abnormal" 3344 "Inside Voltage Abnormal" 3343 "Inside Voltage Abnormal" 3342 "Inside Voltage Abnormal" 3341 "Inside Voltage Abnormal" 3340 "Inside Voltage Abnormal" 3339 "Inside Voltage Abnormal" 3338 "Inside Voltage Abnormal" 3337 "Inside Voltage Abnormal" 3336 "Inside Voltage Abnormal" 3335 "Inside Voltage Abnormal" 3334 "Inside Voltage Abnormal" 3333 "Inside Voltage Abnormal" 3332 "Inside Voltage Abnormal" 3331 "Inside Voltage Abnormal" 3330 "Inside Voltage Abnormal" 3329 "Inside Voltage Abnormal" 3328 "Inside Voltage Abnormal" 3327 "Inside Voltage Abnormal" 3326 "Inside Voltage Abnormal" 3325 "Inside Voltage Abnormal" 3324 "Inside Voltage Abnormal" 3323 "Inside Voltage Abnormal" 3322 "Inside Voltage Abnormal" 3321 "Inside Voltage Abnormal" 3320 "Inside Voltage Abnormal" 3319 "Inside Voltage Abnormal" 3318 "Inside Voltage Abnormal" 3317 "Inside Voltage Abnormal" 3316 "Inside Voltage Abnormal" 3315 "Inside Voltage Abnormal" 3314 "Inside Voltage Abnormal" 3313 "Inside Voltage Abnormal" 3312 "Inside Voltage Abnormal" 3311 "Inside Voltage Abnormal" 3310 "Inside Voltage Abnormal" 3309 "Inside Voltage Abnormal" 3308 "Inside Voltage Abnormal" 3307 "Inside Voltage Abnormal" 3306 "Inside Voltage Abnormal" 3305 "Inside Voltage Abnormal" 3304 "Inside Voltage Abnormal" 3303 "Inside Voltage Abnormal" 3302 "Inside Voltage Abnormal" 3301 "Inside Voltage Abnormal" 3300 "Inside Voltage Abnormal" 3299 "Inside Voltage Abnormal" 3298 "Inside Voltage Abnormal" 3297 "Inside Voltage Abnormal" 3296 "Inside Voltage Abnormal" 3295 "Inside Voltage Abnormal" 3294 "Inside Voltage Abnormal" 3293 "Inside Voltage Abnormal" 3292 "Inside Voltage Abnormal" 3291 "Inside Voltage Abnormal" 3290 "Inside Voltage Abnormal" 3289 "Inside Voltage Abnormal" 3288 "Inside Voltage Abnormal" 3287 "Inside Voltage Abnormal" 3286 "Inside Voltage Abnormal" 3285 "Inside Voltage Abnormal" 3284 "Inside Voltage Abnormal" 3283 "Inside Voltage Abnormal" 3282 "Inside Voltage Abnormal" 3281 "Inside Voltage Abnormal" 3280 "Inside Voltage Abnormal" 3279 "Inside Voltage Abnormal" 3278 "Inside Voltage Abnormal" 3277 "Inside Voltage Abnormal" 3276 "Inside Voltage Abnormal" 3275 "Inside Voltage Abnormal" 3274 "Inside Voltage Abnormal" 3273 "Inside Voltage Abnormal" 3272 "Inside Voltage Abnormal" 3271 "Inside Voltage Abnormal" 3270 "Inside Voltage Abnormal" 3269 "Inside Voltage Abnormal" 3268 "Inside Voltage Abnormal" 3267 "Inside Voltage Abnormal" 3266 "Inside Voltage Abnormal" 3265 "Inside Voltage Abnormal" 3264 "Inside Voltage Abnormal" 3263 "Inside Voltage Abnormal" 3262 "Inside Voltage Abnormal" 3261 "Inside Voltage Abnormal" 3260 "Inside Voltage Abnormal" 3259 "Inside Voltage Abnormal" 3258 "Inside Voltage Abnormal" 3257 "Inside Voltage Abnormal" 3256 "Inside Voltage Abnormal" 3255 "Inside Voltage Abnormal" 3254 "Inside Voltage Abnormal" 3253 "Inside Voltage Abnormal" 3252 "Inside Voltage Abnormal" 3251 "Inside Voltage Abnormal" 3250 "Inside Voltage Abnormal" 3249 "Inside Voltage Abnormal" 3248 "Inside Voltage Abnormal" 3247 "Inside Voltage Abnormal" 3246 "Inside Voltage Abnormal" 3245 "Inside Voltage Abnormal" 3244 "Inside Voltage Abnormal" 3243 "Inside Voltage Abnormal" 3242 "Inside Voltage Abnormal" 3241 "Inside Voltage Abnormal" 3240 "Inside Voltage Abnormal" 3239 "Inside Voltage Abnormal" 3238 "Inside Voltage Abnormal" 3237 "Inside Voltage Abnormal" 3236 "Inside Voltage Abnormal" 3235 "Inside Voltage Abnormal" 3234 "Inside Voltage Abnormal" 3233 "Inside Voltage Abnormal" 3232 "Inside Voltage Abnormal" 3231 "Inside Voltage Abnormal" 3230 "Inside Voltage Abnormal" 3229 "Inside Voltage Abnormal" 3228 "Inside Voltage Abnormal" 3227 "Inside Voltage Abnormal" 3226 "Inside Voltage Abnormal" 3225 "Inside Voltage Abnormal" 3224 "Inside Voltage Abnormal" 3223 "Inside Voltage Abnormal" 3222 "Inside Voltage Abnormal" 3221 "Inside Voltage Abnormal" 3220 "Inside Voltage Abnormal" 3219 "Inside Voltage Abnormal" 3218 "Inside Voltage Abnormal" 3217 "Inside Voltage Abnormal" 3216 "Inside Voltage Abnormal" 3215 "Inside Voltage Abnormal" 3214 "Inside Voltage Abnormal" 3213 "Inside Voltage Abnormal" 3212 "Inside Voltage Abnormal" 3211 "Inside Voltage Abnormal" 3210 "Inside Voltage Abnormal" 3209 "Inside Voltage Abnormal" 3208 "Inside Voltage Abnormal" 3207 "Inside Voltage Abnormal" 3206 "Inside Voltage Abnormal" 3205 "Inside Voltage Abnormal" 3204 "Inside Voltage Abnormal" 3203 "Inside Voltage Abnormal" 3202 "Inside Voltage Abnormal" 3201 "Inside Voltage Abnormal" 3200 "Inside Voltage Abnormal" 3199 "Inside Voltage Abnormal" 3198 "Inside Voltage Abnormal" 3197 "Inside Voltage Abnormal" 3196 "Inside Voltage Abnormal" 3195 "Inside Voltage Abnormal" 3194 "Inside Voltage Abnormal" 3193 "Inside Voltage Abnormal" 3192 "Inside Voltage Abnormal" 3191 "Inside Voltage Abnormal" 3190 "Inside Voltage Abnormal" 3189 "Inside Voltage Abnormal" 3188 "Inside Voltage Abnormal" 3187 "Inside Voltage Abnormal" 3186 "Inside Voltage Abnormal" 3185 "Inside Voltage Abnormal" 3184 "Inside Voltage Abnormal" 3183 "Inside Voltage Abnormal" 3182 "Inside Voltage Abnormal" 3181 "Inside Voltage Abnormal" 3180 "Inside Voltage Abnormal" 3179 "Inside Voltage Abnormal" 3178 "Inside Voltage Abnormal" 3177 "Inside Voltage Abnormal" 3176 "Inside Voltage Abnormal" 3175 "Inside Voltage Abnormal" 3174 "Inside Voltage Abnormal" 3173 "Inside Voltage Abnormal" 3172 "Inside Voltage Abnormal" 3171 "Inside Voltage Abnormal" 3170 "Inside Voltage Abnormal" 3169 "Inside Voltage Abnormal" 3168 "Inside Voltage Abnormal" 3167 "Inside Voltage Abnormal" 3166 "Inside Voltage Abnormal" 3165 "Inside Voltage Abnormal" 3164 "Inside Voltage Abnormal" 3163 "Inside Voltage Abnormal" 3162 "Inside Voltage Abnormal" 3161 "Inside Voltage Abnormal" 3160 "Inside Voltage Abnormal" 3159 "Inside Voltage Abnormal" 3158 "Inside Voltage Abnormal" 3157 "Inside Voltage Abnormal" 3156 "Inside Voltage Abnormal" 3155 "Inside Voltage Abnormal" 3154 "Inside Voltage Abnormal" 3153 "Inside Voltage Abnormal" 3152 "Inside Voltage Abnormal" 3151 "Inside Voltage Abnormal" 3150 "Inside Voltage Abnormal" 3149 "Inside Voltage Abnormal" 3148 "Inside Voltage Abnormal" 3147 "Inside Voltage Abnormal" 3146 "Inside Voltage Abnormal" 3145 "Inside Voltage Abnormal" 3144 "Inside Voltage Abnormal" 3143 "Inside Voltage Abnormal" 3142 "Inside Voltage Abnormal" 3141 "Inside Voltage Abnormal" 3140 "Inside Voltage Abnormal" 3139 "Inside Voltage Abnormal" 3138 "Inside Voltage Abnormal" 3137 "Inside Voltage Abnormal" 3136 "Inside Voltage Abnormal" 3135 "Inside Voltage Abnormal" 3134 "Inside Voltage Abnormal" 3133 "Inside Voltage Abnormal" 3132 "Inside Voltage Abnormal" 3131 "Inside Voltage Abnormal" 3130 "Inside Voltage Abnormal" 3129 "Inside Voltage Abnormal" 3128 "Inside Voltage Abnormal" 3127 "Inside Voltage Abnormal" 3126 "Inside Voltage Abnormal" 3125 "Inside Voltage Abnormal" 3124 "Inside Voltage Abnormal" 3123 "Inside Voltage Abnormal" 3122 "Inside Voltage Abnormal" 3121 "Inside Voltage Abnormal" 3120 "Inside Voltage Abnormal" 3119 "Inside Voltage Abnormal" 3118 "Inside Voltage Abnormal" 3117 "Inside Voltage Abnormal" 3116 "Inside Voltage Abnormal" 3115 "Inside Voltage Abnormal" 3114 "Inside Voltage Abnormal" 3113 "Inside Voltage Abnormal" 3112 "Inside Voltage Abnormal" 3111 "Inside Voltage Abnormal" 3110 "Inside Voltage Abnormal" 3109 "Inside Voltage Abnormal" 3108 "Inside Voltage Abnormal" 3107 "Inside Voltage Abnormal" 3106 "Inside Voltage Abnormal" 3105 "Inside Voltage Abnormal" 3104 "Inside Voltage Abnormal" 3103 "Inside Voltage Abnormal" 3102 "Inside Voltage Abnormal" 3101 "Inside Voltage Abnormal" 3100 "Inside Voltage Abnormal" 3099 "Inside Voltage Abnormal" 3098 "Inside Voltage Abnormal" 3097 "Inside Voltage Abnormal" 3096 "Inside Voltage Abnormal" 3095 "Inside Voltage Abnormal" 3094 "Inside Voltage Abnormal" 3093 "Inside Voltage Abnormal" 3092 "Inside Voltage Abnormal" 3091 "Inside Voltage Abnormal" 3090 "Inside Voltage Abnormal" 3089 "Inside Voltage Abnormal" 3088 "Inside Voltage Abnormal" 3087 "Inside Voltage Abnormal" 3086 "Inside Voltage Abnormal" 3085 "Inside Voltage Abnormal" 3084 "Inside Voltage Abnormal" 3083 "Inside Voltage Abnormal" 3082 "Inside Voltage Abnormal" 3081 "Inside Voltage Abnormal" 3080 "Inside Voltage Abnormal" 3079 "Inside Voltage Abnormal" 3078 "Inside Voltage Abnormal" 3077 "Inside Voltage Abnormal" 3076 "Inside Voltage Abnormal" 3075 "Inside Voltage Abnormal" 3074 "Inside Voltage Abnormal" 3073 "Inside Voltage Abnormal" 3072 "Inside Voltage Abnormal" 3071 "Inside Voltage Abnormal" 3070 "Inside Voltage Abnormal" 3069 "Inside Voltage Abnormal" 3068 "Inside Voltage Abnormal" 3067 "Inside Voltage Abnormal" 3066 "Inside Voltage Abnormal" 3065 "Inside Voltage Abnormal" 3064 "Inside Voltage Abnormal" 3063 "Inside Voltage Abnormal" 3062 "Inside Voltage Abnormal" 3061 "Inside Voltage Abnormal" 3060 "Inside Voltage Abnormal" 3059 "Inside Voltage Abnormal" 3058 "Inside Voltage Abnormal" 3057 "Inside Voltage Abnormal" 3056 "Inside Voltage Abnormal" 3055 "Inside Voltage Abnormal" 3054 "Inside Voltage Abnormal" 3053 "Inside Voltage Abnormal" 3052 "Inside Voltage Abnormal" 3051 "Inside Voltage Abnormal" 3050 "Inside Voltage Abnormal" 3049 "Inside Voltage Abnormal" 3048 "Inside Voltage Abnormal" 3047 "Inside Voltage Abnormal" 3046 "Inside Voltage Abnormal" 3045 "Inside Voltage Abnormal" 3044 "Inside Voltage Abnormal" 3043 "Inside Voltage Abnormal" 3042 "Inside Voltage Abnormal" 3041 "Inside Voltage Abnormal" 3040 "Inside Voltage Abnormal" 3039 "Inside Voltage Abnormal" 3038 "Inside Voltage Abnormal" 3037 "Inside Voltage Abnormal" 3036 "Inside Voltage Abnormal" 3035 "Inside Voltage Abnormal" 3034 "Inside Voltage Abnormal" 3033 "Inside Voltage Abnormal" 3032 "Inside Voltage Abnormal" 3031 "Inside Voltage Abnormal" 3030 "Inside Voltage Abnormal" 3029 "Inside Voltage Abnormal" 3028 "Inside Voltage Abnormal" 3027 "Inside Voltage Abnormal" 3026 "Inside Voltage Abnormal" 3025 "Inside Voltage Abnormal" 3024 "Inside Voltage Abnormal" 3023 "Inside Voltage Abnormal" 3022 "Inside Voltage Abnormal" 3021 "Inside Voltage Abnormal" 3020 "Inside Voltage Abnormal" 3019 "Inside Voltage Abnormal" 3018 "Inside Voltage Abnormal" 3017 "Inside Voltage Abnormal" 3016 "Inside Voltage Abnormal" 3015 "Inside Voltage Abnormal" 3014 "Inside Voltage Abnormal" 3013 "Inside Voltage Abnormal" 3012 "Inside Voltage Abnormal" 3011 "Inside Voltage Abnormal" 3010 "Inside Voltage Abnormal" 3009 "Inside Voltage Abnormal" 3008 "Inside Voltage Abnormal" 3007 "Inside Voltage Abnormal" 3006 "Inside Voltage Abnormal" 3005 "Inside Voltage Abnormal" 3004 "Inside Voltage Abnormal" 3003 "Inside Voltage Abnormal" 3002 "Inside Voltage Abnormal" 3001 "Inside Voltage Abnormal" 3000 "Inside Voltage Abnormal" 2999 "Inside Voltage Abnormal" 2998 "Inside Voltage Abnormal" 2997 "Inside Voltage Abnormal" 2996 "Inside Voltage Abnormal" 2995 "Inside Voltage Abnormal" 2994 "Inside Voltage Abnormal" 2993 "Inside Voltage Abnormal" 2992 "Inside Voltage Abnormal" 2991 "Inside Voltage Abnormal" 2990 "Inside Voltage Abnormal" 2989 "Inside Voltage Abnormal" 2988 "Inside Voltage Abnormal" 2987 "Inside Voltage Abnormal" 2986 "Inside Voltage Abnormal" 2985 "Inside Voltage Abnormal" 2984 "Inside Voltage Abnormal" 2983 "Inside Voltage Abnormal" 2982 "Inside Voltage Abnormal" 2981 "Inside Voltage Abnormal" 2980 "Inside Voltage Abnormal" 2979 "Inside Voltage Abnormal" 2978 "Inside Voltage Abnormal" 2977 "Inside Voltage Abnormal" 2976 "Inside Voltage Abnormal" 2975 "Inside Voltage Abnormal" 2974 "Inside Voltage Abnormal" 2973 "Inside Voltage Abnormal" 2972 "Inside Voltage Abnormal" 2971 "Inside Voltage Abnormal" 2970 "Inside Voltage Abnormal" 2969 "Inside Voltage Abnormal" 2968 "Inside Voltage Abnormal" 2967 "Inside Voltage Abnormal" 2966 "Inside Voltage Abnormal" 2965 "Inside Voltage Abnormal" 2964 "Inside Voltage Abnormal" 2963 "Inside Voltage Abnormal" 2962 "Inside Voltage Abnormal" 2961 "Inside Voltage Abnormal" 2960 "Inside Voltage Abnormal" 2959 "Inside Voltage Abnormal" 2958 "Inside Voltage Abnormal" 2957 "Inside Voltage Abnormal" 2956 "Inside Voltage Abnormal" 2955 "Inside Voltage Abnormal" 2954 "Inside Voltage Abnormal" 2953 "Inside Voltage Abnormal" 2952 "Inside Voltage Abnormal" 2951 "Inside Voltage Abnormal" 2950 "Inside Voltage Abnormal" 2949 "Inside Voltage Abnormal" 2948 "Inside Voltage Abnormal" 2947 "Inside Voltage Abnormal" 2946 "Inside Voltage Abnormal" 2945 "Inside Voltage Abnormal" 2944 "Inside Voltage Abnormal" 2943 "Inside Voltage Abnormal" 2942 "Inside Voltage Abnormal" 2941 "Inside Voltage Abnormal" 2940 "Inside Voltage Abnormal" 2939 "Inside Voltage Abnormal" 2938 "Inside Voltage Abnormal" 2937 "Inside Voltage Abnormal" 2936 "Inside Voltage Abnormal" 2935 "Inside Voltage Abnormal" 2934 "Inside Voltage Abnormal" 2933 "Inside Voltage Abnormal" 2932 "Inside Voltage Abnormal" 2931 "Inside Voltage Abnormal" 2930 "Inside Voltage Abnormal" 2929 "Inside Voltage Abnormal" 2928 "Inside Voltage Abnormal" 2927 "Inside Voltage Abnormal" 2926 "Inside Voltage Abnormal" 2925 "Inside Voltage Abnormal" 2924 "Inside Voltage Abnormal" 2923 "Inside Voltage Abnormal" 2922 "Inside Voltage Abnormal" 2921 "Inside Voltage Abnormal" 2920 "Inside Voltage Abnormal" 2919 "Inside Voltage Abnormal" 2918 "Inside Voltage Abnormal" 2917 "Inside Voltage Abnormal" 2916 "Inside Voltage Abnormal" 2915 "Inside Voltage Abnormal" 2914 "Inside Voltage Abnormal" 2913 "Inside Voltage Abnormal" 2912 "Inside Voltage Abnormal" 2911 "Inside Voltage Abnormal" 2910 "Inside Voltage Abnormal" 2909 "Inside Voltage Abnormal" 2908 "Inside Voltage Abnormal" 2907 "Inside Voltage Abnormal" 2906 "Inside Voltage Abnormal" 2905 "Inside Voltage Abnormal" 2904 "Inside Voltage Abnormal" 2903 "Inside Voltage Abnormal" 2902 "Inside Voltage Abnormal" 2901 "Inside Voltage Abnormal" 2900 "Inside Voltage Abnormal" 2899 "Inside Voltage Abnormal" 2898 "Inside Voltage Abnormal" 2897 "Inside Voltage Abnormal" 2896 "Inside Voltage Abnormal" 2895 "Inside Voltage Abnormal" 2894 "Inside Voltage Abnormal" 2893 "Inside Voltage Abnormal" 2892 "Inside Voltage Abnormal" 2891 "Inside Voltage Abnormal" 2890 "Inside Voltage Abnormal" 2889 "Inside Voltage Abnormal" 2888 "Inside Voltage Abnormal" 2887 "Inside Voltage Abnormal" 2886 "Inside Voltage Abnormal" 2885 "Inside Voltage Abnormal" 2884 "Inside Voltage Abnormal" 2883 "Inside Voltage Abnormal" 2882 "Inside Voltage Abnormal" 2881 "Inside Voltage Abnormal" 2880 "Inside Voltage Abnormal" 2879 "Inside Voltage Abnormal" 2878 "Inside Voltage Abnormal" 2877 "Inside Voltage Abnormal" 2876 "Inside Voltage Abnormal" 2875 "Inside Voltage Abnormal" 2874 "Inside Voltage Abnormal" 2873 "Inside Voltage Abnormal" 2872 "Inside Voltage Abnormal" 2871 "Inside Voltage Abnormal" 2870 "Inside Voltage Abnormal" 2869 "Inside Voltage Abnormal" 2868 "Inside Voltage Abnormal" 2867 "Inside Voltage Abnormal" 2866 "Inside Voltage Abnormal" 2865 "Inside Voltage Abnormal" 2864 "Inside Voltage Abnormal" 2863 "Inside Voltage Abnormal" 2862 "Inside Voltage Abnormal" 2861 "Inside Voltage Abnormal" 2860 "Inside Voltage Abnormal" 2859 "Inside Voltage Abnormal" 2858 "Inside Voltage Abnormal" 2857 "Inside Voltage Abnormal" 2856 "Inside Voltage Abnormal" 2855 "Inside Voltage Abnormal" 2854 "Inside Voltage Abnormal" 2853 "Inside Voltage Abnormal" 2852 "Inside Voltage Abnormal" 2851 "Inside Voltage Abnormal" 2850 "Inside Voltage Abnormal" 2849 "Inside Voltage Abnormal" 2848 "Inside Voltage Abnormal" 2847 "Inside Voltage Abnormal" 2846 "Inside Voltage Abnormal" 2845 "Inside Voltage Abnormal" 2844 "Inside Voltage Abnormal" 2843 "Inside Voltage Abnormal" 2842 "Inside Voltage Abnormal" 2841 "Inside Voltage Abnormal" 2840 "Inside Voltage Abnormal" 2839 "Inside Voltage Abnormal" 2838 "Inside Voltage Abnormal" 2837 "Inside Voltage Abnormal" 2836 "Inside Voltage Abnormal" 2835 "Inside Voltage Abnormal" 2834 "Inside Voltage Abnormal" 2833 "Inside Voltage Abnormal" 2832 "Inside Voltage Abnormal" 2831 "Inside Voltage Abnormal" 2830 "Inside Voltage Abnormal" 2829 "Inside Voltage Abnormal" 2828 "Inside Voltage Abnormal" 2827 "Inside Voltage Abnormal" 2826 "Inside Voltage Abnormal" 2825 "Inside Voltage Abnormal" 2824 "Inside Voltage Abnormal" 2823 "Inside Voltage Abnormal" 2822 "Inside Voltage Abnormal" 2821 "Inside Voltage Abnormal" 2820 "Inside Voltage Abnormal" 2819 "Inside Voltage Abnormal" 2818 "Inside Voltage Abnormal" 2817 "Inside Voltage Abnormal" 2816 "Inside Voltage Abnormal" 2815 "Inside Voltage Abnormal" 2814 "Inside Voltage Abnormal" 2813 "Inside Voltage Abnormal" 2812 "Inside Voltage Abnormal" 2811 "Inside Voltage Abnormal" 2810 "Inside Voltage Abnormal" 2809 "Inside Voltage Abnormal" 2808 "Inside Voltage Abnormal" 2807 "Inside Voltage Abnormal" 2806 "Inside Voltage Abnormal" 2805 "Inside Voltage Abnormal" 2804 "Inside Voltage Abnormal" 2803 "Inside Voltage Abnormal" 2802 "Inside Voltage Abnormal" 2801 "Inside Voltage Abnormal" 2800 "Inside Voltage Abnormal" 2799 "Inside Voltage Abnormal" 2798 "Inside Voltage Abnormal" 2797 "Inside Voltage Abnormal" 2796 "Inside Voltage Abnormal" 2795 "Inside Voltage Abnormal" 2794 "Inside Voltage Abnormal" 2793 "Inside Voltage Abnormal" 2792 "Inside Voltage Abnormal" 2791 "Inside Voltage Abnormal" 2790 "Inside Voltage Abnormal" 2789 "Inside Voltage Abnormal" 2788 "Inside Voltage Abnormal" 2787 "Inside Voltage Abnormal" 2786 "Inside Voltage Abnormal" 2785 "Inside Voltage Abnormal" 2784 "Inside Voltage Abnormal" 2783 "Inside Voltage Abnormal" 2782 "Inside Voltage Abnormal" 2781 "Inside Voltage Abnormal" 2780 "Inside Voltage Abnormal" 2779 "Inside Voltage Abnormal" 2778 "Inside Voltage Abnormal" 2777 "Inside Voltage Abnormal" 2776 "Inside Voltage Abnormal" 2775 "Inside Voltage Abnormal" 2774 "Inside Voltage Abnormal" 2773 "Inside Voltage Abnormal" 2772 "Inside Voltage Abnormal" 2771 "Inside Voltage Abnormal" 2770 "Inside Voltage Abnormal" 2769 "Inside Voltage Abnormal" 2768 "Inside Voltage Abnormal" 2767 "Inside Voltage Abnormal" 2766 "Inside Voltage Abnormal" 2765 "Inside Voltage Abnormal" 2764 "Inside Voltage Abnormal" 2763 "Inside Voltage Abnormal" 2762 "Inside Voltage Abnormal" 2761 "Inside Voltage Abnormal" 2760 "Inside Voltage Abnormal" 2759 "Inside Voltage Abnormal" 2758 "Inside Voltage Abnormal" 2757 "Inside Voltage Abnormal" 2756 "Inside Voltage Abnormal" 2755 "Inside Voltage Abnormal" 2754 "Inside Voltage Abnormal" 2753 "Inside Voltage Abnormal" 2752 "Inside Voltage Abnormal" 2751 "Inside Voltage Abnormal" 2750 "Inside Voltage Abnormal" 2749 "Inside Voltage Abnormal" 2748 "Inside Voltage Abnormal" 2747 "Inside Voltage Abnormal" 2746 "Inside Voltage Abnormal" 2745 "Inside Voltage Abnormal" 2744 "Inside Voltage Abnormal" 2743 "Inside Voltage Abnormal" 2742 "Inside Voltage Abnormal" 2741 "Inside Voltage Abnormal" 2740 "Inside Voltage Abnormal" 2739 "Inside Voltage Abnormal" 2738 "Inside Voltage Abnormal" 2737 "Inside Voltage Abnormal" 2736 "Inside Voltage Abnormal" 2735 "Inside Voltage Abnormal" 2734 "Inside Voltage Abnormal" 2733 "Inside Voltage Abnormal" 2732 "Inside Voltage Abnormal" 2731 "Inside Voltage Abnormal" 2730 "Inside Voltage Abnormal" 2729 "Inside Voltage Abnormal" 2728 "Inside Voltage Abnormal" 2727 "Inside Voltage Abnormal" 2726 "Inside Voltage Abnormal" 2725 "Inside Voltage Abnormal" 2724 "Inside Voltage Abnormal" 2723 "Inside Voltage Abnormal" 2722 "Inside Voltage Abnormal" 2721 "Inside Voltage Abnormal" 2720 "Inside Voltage Abnormal" 2719 "Inside Voltage Abnormal" 2718 "Inside Voltage Abnormal" 2717 "Inside Voltage Abnormal" 2716 "Inside Voltage Abnormal" 2715 "Inside Voltage Abnormal" 2714 "Inside Voltage Abnormal" 2713 "Inside Voltage Abnormal" 2712 "Inside Voltage Abnormal" 2711 "Inside Voltage Abnormal" 2710 "Inside Voltage Abnormal" 2709 "Inside Voltage Abnormal" 2708 "Inside Voltage Abnormal" 2707 "Inside Voltage Abnormal" 2706 "Inside Voltage Abnormal" 2705 "Inside Voltage Abnormal" 2704 "Inside Voltage Abnormal" 2703 "Inside Voltage Abnormal" 2702 "Inside Voltage Abnormal" 2701 "Inside Voltage Abnormal" 2700 "Inside Voltage Abnormal" 2699 "Inside Voltage Abnormal" 2698 "Inside Voltage Abnormal" 2697 "Inside Voltage Abnormal" 2696 "Inside Voltage Abnormal" 2695 "Inside Voltage Abnormal" 2694 "Inside Voltage Abnormal" 2693 "Inside Voltage Abnormal" 2692 "Inside Voltage Abnormal" 2691 "Inside Voltage Abnormal" 2690 "Inside Voltage Abnormal" 2689 "Inside Voltage Abnormal" 2688 "Inside Voltage Abnormal" 2687 "Inside Voltage Abnormal" 2686 "Inside Voltage Abnormal" 2685 "Inside Voltage Abnormal" 2684 "Inside Voltage Abnormal" 2683 "Inside Voltage Abnormal" 2682 "Inside Voltage Abnormal" 2681 "Inside Voltage Abnormal" 2680 "Inside Voltage Abnormal" 2679 "Inside Voltage Abnormal" 2678 "Inside Voltage Abnormal" 2677 "Inside Voltage Abnormal" 2676 "Inside Voltage Abnormal" 2675 "Inside Voltage Abnormal" 2674 "Inside Voltage Abnormal" 2673 "Inside Voltage Abnormal" 2672 "Inside Voltage Abnormal" 2671 "Inside Voltage Abnormal" 2670 "Inside Voltage Abnormal" 2669 "Inside Voltage Abnormal" 2668 "Inside Voltage Abnormal" 2667 "Inside Voltage Abnormal" 2666 "Inside Voltage Abnormal" 2665 "Inside Voltage Abnormal" 2664 "Inside Voltage Abnormal" 2663 "Inside Voltage Abnormal" 2662 "Inside Voltage Abnormal" 2661 "Inside Voltage Abnormal" 2660 "Inside Voltage Abnormal" 2659 "Inside Voltage Abnormal" 2658 "Inside Voltage Abnormal" 2657 "Inside Voltage Abnormal" 2656 "Inside Voltage Abnormal" 2655 "Inside Voltage Abnormal" 2654 "Inside Voltage Abnormal" 2653 "Inside Voltage Abnormal" 2652 "Inside Voltage Abnormal" 2651 "Inside Voltage Abnormal" 2650 "Inside Voltage Abnormal" 2649 "Inside Voltage Abnormal" 2648 "Inside Voltage Abnormal" 2647 "Inside Voltage Abnormal" 2646 "Inside Voltage Abnormal" 2645 "Inside Voltage Abnormal" 2644 "Inside Voltage Abnormal" 2643 "Inside Voltage Abnormal" 2642 "Inside Voltage Abnormal" 2641 "Inside Voltage Abnormal" 2640 "Inside Voltage Abnormal" 2639 "Inside Voltage Abnormal" 2638 "Inside Voltage Abnormal" 2637 "Inside Voltage Abnormal" 2636 "Inside Voltage Abnormal" 2635 "Inside Voltage Abnormal" 2634 "Inside Voltage Abnormal" 2633 "Inside Voltage Abnormal" 2632 "Inside Voltage Abnormal" 2631 "Inside Voltage Abnormal" 2630 "Inside Voltage Abnormal" 2629 "Inside Voltage Abnormal" 2628 "Inside Voltage Abnormal" 2627 "Inside Voltage Abnormal" 2626 "Inside Voltage Abnormal" 2625 "Inside Voltage Abnormal" 2624 "Inside Voltage Abnormal" 2623 "Inside Voltage Abnormal" 2622 "Inside Voltage Abnormal" 2621 "Inside Voltage Abnormal" 2620 "Inside Voltage Abnormal" 2619 "Inside Voltage Abnormal" 2618 "Inside Voltage Abnormal" 2617 "Inside Voltage Abnormal" 2616 "Inside Voltage Abnormal" 2615 "Inside Voltage Abnormal" 2614 "Inside Voltage Abnormal" 2613 "Inside Voltage Abnormal" 2612 "Inside Voltage Abnormal" 2611 "Inside Voltage Abnormal" 2610 "Inside Voltage Abnormal" 2609 "Inside Voltage Abnormal" 2608 "Inside Voltage Abnormal" 2607 "Inside Voltage Abnormal" 2606 "Inside Voltage Abnormal" 2605 "Inside Voltage Abnormal" 2604 "Inside Voltage Abnormal" 2603 "Inside Voltage Abnormal" 2602 "Inside Voltage Abnormal" 2601 "Inside Voltage Abnormal" 2600 "Inside Voltage Abnormal" 2599 "Inside Voltage Abnormal" 2598 "Inside Voltage Abnormal" 2597 "Inside Voltage Abnormal" 2596 "Inside Voltage Abnormal" 2595 "Inside Voltage Abnormal" 2594 "Inside Voltage Abnormal" 2593 "Inside Voltage Abnormal" 2592 "Inside Voltage Abnormal" 2591 "Inside Voltage Abnormal" 2590 "Inside Voltage Abnormal" 2589 "Inside Voltage Abnormal" 2588 "Inside Voltage Abnormal" 2587 "Inside Voltage Abnormal" 2586 "Inside Voltage Abnormal" 2585 "Inside Voltage Abnormal" 2584 "Inside Voltage Abnormal" 2583 "Inside Voltage Abnormal" 2582 "Inside Voltage Abnormal" 2581 "Inside Voltage Abnormal" 2580 "Inside Voltage Abnormal" 2579 "Inside Voltage Abnormal" 2578 "Inside Voltage Abnormal" 2577 "Inside Voltage Abnormal" 2576 "Inside Voltage Abnormal" 2575 "Inside Voltage Abnormal" 2574 "Inside Voltage Abnormal" 2573 "Inside Voltage Abnormal" 2572 "Inside Voltage Abnormal" 2571 "Inside Voltage Abnormal" 2570 "Inside Voltage Abnormal" 2569 "Inside Voltage Abnormal" 2568 "Inside Voltage Abnormal" 2567 "Inside Voltage Abnormal" 2566 "Inside Voltage Abnormal" 2565 "Inside Voltage Abnormal" 2564 "Inside Voltage Abnormal" 2563 "Inside Voltage Abnormal" 2562 "Inside Voltage Abnormal" 2561 "Inside Voltage Abnormal" 2560 "Inside Voltage Abnormal" 2559 "Inside Voltage Abnormal" 2558 "Inside Voltage Abnormal" 2557 "Inside Voltage Abnormal" 2556 "Inside Voltage Abnormal" 2555 "Inside Voltage Abnormal" 2554 "Inside Voltage Abnormal" 2553 "Inside Voltage Abnormal" 2552 "Inside Voltage Abnormal" 2551 "Inside Voltage Abnormal" 2550 "Inside Voltage Abnormal" 2549 "Inside Voltage Abnormal" 2548 "Inside Voltage Abnormal" 2547 "Inside Voltage Abnormal" 2546 "Inside Voltage Abnormal" 2545 "Inside Voltage Abnormal" 2544 "Inside Voltage Abnormal" 2543 "Inside Voltage Abnormal" 2542 "Inside Voltage Abnormal" 2541 "Inside Voltage Abnormal" 2540 "Inside Voltage Abnormal" 2539 "Inside Voltage Abnormal" 2538 "Inside Voltage Abnormal" 2537 "Inside Voltage Abnormal" 2536 "Inside Voltage Abnormal" 2535 "Inside Voltage Abnormal" 2534 "Inside Voltage Abnormal" 2533 "Inside Voltage Abnormal" 2532 "Inside Voltage Abnormal" 2531 "Inside Voltage Abnormal" 2530 "Inside Voltage Abnormal" 2529 "Inside Voltage Abnormal" 2528 "Inside Voltage Abnormal" 2527 "Inside Voltage Abnormal" 2526 "Inside Voltage Abnormal" 2525 "Inside Voltage Abnormal" 2524 "Inside Voltage Abnormal" 2523 "Inside Voltage Abnormal" 2522 "Inside Voltage Abnormal" 2521 "Inside Voltage Abnormal" 2520 "Inside Voltage Abnormal" 2519 "Inside Voltage Abnormal" 2518 "Inside Voltage Abnormal" 2517 "Inside Voltage Abnormal" 2516 "Inside Voltage Abnormal" 2515 "Inside Voltage Abnormal" 2514 "Inside Voltage Abnormal" 2513 "Inside Voltage Abnormal" 2512 "Inside Voltage Abnormal" 2511 "Inside Voltage Abnormal" 2510 "Inside Voltage Abnormal" 2509 "Inside Voltage Abnormal" 2508 "Inside Voltage Abnormal" 2507 "Inside Voltage Abnormal" 2506 "Inside Voltage Abnormal" 2505 "Inside Voltage Abnormal" 2504 "Inside Voltage Abnormal" 2503 "Inside Voltage Abnormal" 2502 "Inside Voltage Abnormal" 2501 "Inside Voltage Abnormal" 2500 "Inside Voltage Abnormal" 2499 "Inside Voltage Abnormal" 2498 "Inside Voltage Abnormal" 2497 "Inside Voltage Abnormal" 2496 "Inside Voltage Abnormal" 2495 "Inside Voltage Abnormal" 2494 "Inside Voltage Abnormal" 2493 "Inside Voltage Abnormal" 2492 "Inside Voltage Abnormal" 2491 "Inside Voltage Abnormal" 2490 "Inside Voltage Abnormal" 2489 "Inside Voltage Abnormal" 2488 "Inside Voltage Abnormal" 2487 "Inside Voltage Abnormal" 2486 "Inside Voltage Abnormal" 2485 "Inside Voltage Abnormal" 2484 "Inside Voltage Abnormal" 2483 "Inside Voltage Abnormal" 2482 "Inside Voltage Abnormal" 2481 "Inside Voltage Abnormal" 2480 "Inside Voltage Abnormal" 2479 "Inside Voltage Abnormal" 2478 "Inside Voltage Abnormal" 2477 "Inside Voltage Abnormal" 2476 "Inside Voltage Abnormal" 2475 "Inside Voltage Abnormal" 2474 "Inside Voltage Abnormal" 2473 "Inside Voltage Abnormal" 2472 "Inside Voltage Abnormal" 2471 "Inside Voltage Abnormal" 2470 "Inside Voltage Abnormal" 2469 "Inside Voltage Abnormal" 2468 "Inside Voltage Abnormal" 2467 "Inside Voltage Abnormal" 2466 "Inside Voltage Abnormal" 2465 "Inside Voltage Abnormal" 2464 "Inside Voltage Abnormal" 2463 "Inside Voltage Abnormal" 2462 "Inside Voltage Abnormal" 2461 "Inside Voltage Abnormal" 2460 "Inside Voltage Abnormal" 2459 "Inside Voltage Abnormal" 2458 "Inside Voltage Abnormal" 2457 "Inside Voltage Abnormal" 2456 "Inside Voltage Abnormal" 2455 "Inside Voltage Abnormal" 2454 "Inside Voltage Abnormal" 2453 "Inside Voltage Abnormal" 2452 "Inside Voltage Abnormal" 2451 "Inside Voltage Abnormal" 2450 "Inside Voltage Abnormal" 2449 "Inside Voltage Abnormal" 2448 "Inside Voltage Abnormal" 2447 "Inside Voltage Abnormal" 2446 "Inside Voltage Abnormal" 2445 "Inside Voltage Abnormal" 2444 "Inside Voltage Abnormal" 2443 "Inside Voltage Abnormal" 2442 "Inside Voltage Abnormal" 2441 "Inside Voltage Abnormal" 2440 "Inside Voltage Abnormal" 2439 "Inside Voltage Abnormal" 2438 "Inside Voltage Abnormal" 2437 "Inside Voltage Abnormal" 2436 "Inside Voltage Abnormal" 2435 "Inside Voltage Abnormal" 2434 "Inside Voltage Abnormal" 2433 "Inside Voltage Abnormal" 2432 "Inside Voltage Abnormal" 2431 "Inside Voltage Abnormal" 2430 "Inside Voltage Abnormal" 2429 "Inside Voltage Abnormal" 2428 "Inside Voltage Abnormal" 2427 "Inside Voltage Abnormal" 2426 "Inside Voltage Abnormal" 2425 "Inside Voltage Abnormal" 2424 "Inside Voltage Abnormal" 2423 "Inside Voltage Abnormal" 2422 "Inside Voltage Abnormal" 2421 "Inside Voltage Abnormal" 2420 "Inside Voltage Abnormal" 2419 "Inside Voltage Abnormal" 2418 "Inside Voltage Abnormal" 2417 "Inside Voltage Abnormal" 2416 "Inside Voltage Abnormal" 2415 "Inside Voltage Abnormal" 2414 "Inside Voltage Abnormal" 2413 "Inside Voltage Abnormal" 2412 "Inside Voltage Abnormal" 2411 "Inside Voltage Abnormal" 2410 "Inside Voltage Abnormal" 2409 "Inside Voltage Abnormal" 2408 "Inside Voltage Abnormal" 2407 "Inside Voltage Abnormal" 2406 "Inside Voltage Abnormal" 2405 "Inside Voltage Abnormal" 2404 "Inside Voltage Abnormal" 2403 "Inside Voltage Abnormal" 2402 "Inside Voltage Abnormal" 2401 "Inside Voltage Abnormal" 2400 "Inside Voltage Abnormal" 2399 "Inside Voltage Abnormal" 2398 "Inside Voltage Abnormal" 2397 "Inside Voltage Abnormal" 2396 "Inside Voltage Abnormal" 2395 "Inside Voltage Abnormal" 2394 "Inside Voltage Abnormal" 2393 "Inside Voltage Abnormal" 2392 "Inside Voltage Abnormal" 2391 "Inside Voltage Abnormal" 2390 "Inside Voltage Abnormal" 2389 "Inside Voltage Abnormal" 2388 "Inside Voltage Abnormal" 2387 "Inside Voltage Abnormal" 2386 "Inside Voltage Abnormal" 2385 "Inside Voltage Abnormal" 2384 "Inside Voltage Abnormal" 2383 "Inside Voltage Abnormal" 2382 "Inside Voltage Abnormal" 2381 "Inside Voltage Abnormal" 2380 "Inside Voltage Abnormal" 2379 "Inside Voltage Abnormal" 2378 "Inside Voltage Abnormal" 2377 "Inside Voltage Abnormal" 2376 "Inside Voltage Abnormal" 2375 "Inside Voltage Abnormal" 2374 "Inside Voltage Abnormal" 2373 "Inside Voltage Abnormal" 2372 "Inside Voltage Abnormal" 2371 "Inside Voltage Abnormal" 2370 "Inside Voltage Abnormal" 2369 "Inside Voltage Abnormal" 2368 "Inside Voltage Abnormal" 2367 "Inside Voltage Abnormal" 2366 "Inside Voltage Abnormal" 2365 "Inside Voltage Abnormal" 2364 "Inside Voltage Abnormal" 2363 "Inside Voltage Abnormal" 2362 "Inside Voltage Abnormal" 2361 "Inside Voltage Abnormal" 2360 "Inside Voltage Abnormal" 2359 "Inside Voltage Abnormal" 2358 "Inside Voltage Abnormal" 2357 "Inside Voltage Abnormal" 2356 "Inside Voltage Abnormal" 2355 "Inside Voltage Abnormal" 2354 "Inside Voltage Abnormal" 2353 "Inside Voltage Abnormal" 2352 "Inside Voltage Abnormal" 2351 "Inside Voltage Abnormal" 2350 "Inside Voltage Abnormal" 2349 "Inside Voltage Abnormal" 2348 "Inside Voltage Abnormal" 2347 "Inside Voltage Abnormal" 2346 "Inside Voltage Abnormal" 2345 "Inside Voltage Abnormal" 2344 "Inside Voltage Abnormal" 2343 "Inside Voltage Abnormal" 2342 "Inside Voltage Abnormal" 2341 "Inside Voltage Abnormal" 2340 "Inside Voltage Abnormal" 2339 "Inside Voltage Abnormal" 2338 "Inside Voltage Abnormal" 2337 "Inside Voltage Abnormal" 2336 "Inside Voltage Abnormal" 2335 "Inside Voltage Abnormal" 2334 "Inside Voltage Abnormal" 2333 "Inside Voltage Abnormal" 2332 "Inside Voltage Abnormal" 2331 "Inside Voltage Abnormal" 2330 "Inside Voltage Abnormal" 2329 "Inside Voltage Abnormal" 2328 "Inside Voltage Abnormal" 2327 "Inside Voltage Abnormal" 2326 "Inside Voltage Abnormal" 2325 "Inside Voltage Abnormal" 2324 "Inside Voltage Abnormal" 2323 "Inside Voltage Abnormal" 2322 "Inside Voltage Abnormal" 2321 "Inside Voltage Abnormal" 2320 "Inside Voltage Abnormal" 2319 "Inside Voltage Abnormal" 2318 "Inside Voltage Abnormal" 2317 "Inside Voltage Abnormal" 2316 "Inside Voltage Abnormal" 2315 "Inside Voltage Abnormal" 2314 "Inside Voltage Abnormal" 2313 "Inside Voltage Abnormal" 2312 "Inside Voltage Abnormal" 2311 "Inside Voltage Abnormal" 2310 "Inside Voltage Abnormal" 2309 "Inside Voltage Abnormal" 2308 "Inside Voltage Abnormal" 2307 "Inside Voltage Abnormal" 2306 "Inside Voltage Abnormal" 2305 "Inside Voltage Abnormal" 2304 "Inside Voltage Abnormal" 2303 "Inside Voltage Abnormal" 2302 "Inside Voltage Abnormal" 2301 "Inside Voltage Abnormal" 2300 "Inside Voltage Abnormal" 2299 "Inside Voltage Abnormal" 2298 "Inside Voltage Abnormal" 2297 "Inside Voltage Abnormal" 2296 "Inside Voltage Abnormal" 2295 "Inside Voltage Abnormal" 2294 "Inside Voltage Abnormal" 2293 "Inside Voltage Abnormal" 2292 "Inside Voltage Abnormal" 2291 "Inside Voltage Abnormal" 2290 "Inside Voltage Abnormal" 2289 "Inside Voltage Abnormal" 2288 "Inside Voltage Abnormal" 2287 "Inside Voltage Abnormal" 2286 "Inside Voltage Abnormal" 2285 "Inside Voltage Abnormal" 2284 "Inside Voltage Abnormal" 2283 "Inside Voltage Abnormal" 2282 "Inside Voltage Abnormal" 2281 "Inside Voltage Abnormal" 2280 "Inside Voltage Abnormal" 2279 "Inside Voltage Abnormal" 2278 "Inside Voltage Abnormal" 2277 "Inside Voltage Abnormal" 2276 "Inside Voltage Abnormal" 2275 "Inside Voltage Abnormal" 2274 "Inside Voltage Abnormal" 2273 "Inside Voltage Abnormal" 2272 "Inside Voltage Abnormal" 2271 "Inside Voltage Abnormal" 2270 "Inside Voltage Abnormal" 2269 "Inside Voltage Abnormal" 2268 "Inside Voltage Abnormal" 2267 "Inside Voltage Abnormal" 2266 "Inside Voltage Abnormal" 2265 "Inside Voltage Abnormal" 2264 "Inside Voltage Abnormal" 2263 "Inside Voltage Abnormal" 2262 "Inside Voltage Abnormal" 2261 "Inside Voltage Abnormal" 2260 "Inside Voltage Abnormal" 2259 "Inside Voltage Abnormal" 2258 "Inside Voltage Abnormal" 2257 "Inside Voltage Abnormal" 2256 "Inside Voltage Abnormal" 2255 "Inside Voltage Abnormal" 2254 "Inside Voltage Abnormal" 2253 "Inside Voltage Abnormal" 2252 "Inside Voltage Abnormal" 2251 "Inside Voltage Abnormal" 2250 "Inside Voltage Abnormal" 2249 "Inside Voltage Abnormal" 2248 "Inside Voltage Abnormal" 2247 "Inside Voltage Abnormal" 2246 "Inside Voltage Abnormal" 2245 "Inside Voltage Abnormal" 2244 "Inside Voltage Abnormal" 2243 "Inside Voltage Abnormal" 2242 "Inside Voltage Abnormal" 2241 "Inside Voltage Abnormal" 2240 "Inside Voltage Abnormal" 2239 "Inside Voltage Abnormal" 2238 "Inside Voltage Abnormal" 2237 "Inside Voltage Abnormal" 2236 "Inside Voltage Abnormal" 2235 "Inside Voltage Abnormal" 2234 "Inside Voltage Abnormal" 2233 "Inside Voltage Abnormal" 2232 "Inside Voltage Abnormal" 2231 "Inside Voltage Abnormal" 2230 "Inside Voltage Abnormal" 2229 "Inside Voltage Abnormal" 2228 "Inside Voltage Abnormal" 2227 "Inside Voltage Abnormal" 2226 "Inside Voltage Abnormal" 2225 "Inside Voltage Abnormal" 2224 "Inside Voltage Abnormal" 2223 "Inside Voltage Abnormal" 2222 "Inside Voltage Abnormal" 2221 "Inside Voltage Abnormal" 2220 "Inside Voltage Abnormal" 2219 "Inside Voltage Abnormal" 2218 "Inside Voltage Abnormal" 2217 "Inside Voltage Abnormal" 2216 "Inside Voltage Abnormal" 2215 "Inside Voltage Abnormal" 2214 "Inside Voltage Abnormal" 2213 "Inside Voltage Abnormal" 2212 "Inside Voltage Abnormal" 2211 "Inside Voltage Abnormal" 2210 "Inside Voltage Abnormal" 2209 "Inside Voltage Abnormal" 2208 "Inside Voltage Abnormal" 2207 "Inside Voltage Abnormal" 2206 "Inside Voltage Abnormal" 2205 "Inside Voltage Abnormal" 2204 "Inside Voltage Abnormal" 2203 "Inside Voltage Abnormal" 2202 "Inside Voltage Abnormal" 2201 "Inside Voltage Abnormal" 2200 "Inside Voltage Abnormal" 2199 "Inside Voltage Abnormal" 2198 "Inside Voltage Abnormal" 2197 "Inside Voltage Abnormal" 2196 "Inside Voltage Abnormal" 2195 "Inside Voltage Abnormal" 2194 "Inside Voltage Abnormal" 2193 "Inside Voltage Abnormal" 2192 "Inside Voltage Abnormal" 2191 "Inside Voltage Abnormal" 2190 "Inside Voltage Abnormal" 2189 "Inside Voltage Abnormal" 2188 "Inside Voltage Abnormal" 2187 "Inside Voltage Abnormal" 2186 "Inside Voltage Abnormal" 2185 "Inside Voltage Abnormal" 2184 "Inside Voltage Abnormal" 2183 "Inside Voltage Abnormal" 2182 "Inside Voltage Abnormal" 2181 "Inside Voltage Abnormal" 2180 "Inside Voltage Abnormal" 2179 "Inside Voltage Abnormal" 2178 "Inside Voltage Abnormal" 2177 "Inside Voltage Abnormal" 2176 "Inside Voltage Abnormal" 2175 "Inside Voltage Abnormal" 2174 "Inside Voltage Abnormal" 2173 "Inside Voltage Abnormal" 2172 "Inside Voltage Abnormal" 2171 "Inside Voltage Abnormal" 2170 "Inside Voltage Abnormal" 2169 "Inside Voltage Abnormal" 2168 "Inside Voltage Abnormal" 2167 "Inside Voltage Abnormal" 2166 "Inside Voltage Abnormal" 2165 "Inside Voltage Abnormal" 2164 "Inside Voltage Abnormal" 2163 "Inside Voltage Abnormal" 2162 "Inside Voltage Abnormal" 2161 "Inside Voltage Abnormal" 2160 "Inside Voltage Abnormal" 2159 "Inside Voltage Abnormal" 2158 "Inside Voltage Abnormal" 2157 "Inside Voltage Abnormal" 2156 "Inside Voltage Abnormal" 2155 "Inside Voltage Abnormal" 2154 "Inside Voltage Abnormal" 2153 "Inside Voltage Abnormal" 2152 "Inside Voltage Abnormal" 2151 "Inside Voltage Abnormal" 2150 "Inside Voltage Abnormal" 2149 "Inside Voltage Abnormal" 2148 "Inside Voltage Abnormal" 2147 "Inside Voltage Abnormal" 2146 "Inside Voltage Abnormal" 2145 "Inside Voltage Abnormal" 2144 "Inside Voltage Abnormal" 2143 "Inside Voltage Abnormal" 2142 "Inside Voltage Abnormal" 2141 "Inside Voltage Abnormal" 2140 "Inside Voltage Abnormal" 2139 "Inside Voltage Abnormal" 2138 "Inside Voltage Abnormal" 2137 "Inside Voltage Abnormal" 2136 "Inside Voltage Abnormal" 2135 "Inside Voltage Abnormal" 2134 "Inside Voltage Abnormal" 2133 "Inside Voltage Abnormal" 2132 "Inside Voltage Abnormal" 2131 "Inside Voltage Abnormal" 2130 "Inside Voltage Abnormal" 2129 "Inside Voltage Abnormal" 2128 "Inside Voltage Abnormal" 2127 "Inside Voltage Abnormal" 2126 "Inside Voltage Abnormal" 2125 "Inside Voltage Abnormal" 2124 "Inside Voltage Abnormal" 2123 "Inside Voltage Abnormal" 2122 "Inside Voltage Abnormal" 2121 "Inside Voltage Abnormal" 2120 "Inside Voltage Abnormal" 2119 "Inside Voltage Abnormal" 2118 "Inside Voltage Abnormal" 2117 "Inside Voltage Abnormal" 2116 "Inside Voltage Abnormal" 2115 "Inside Voltage Abnormal" 2114 "Inside Voltage Abnormal" 2113 "Inside Voltage Abnormal" 2112 "Inside Voltage Abnormal" 2111 "Inside Voltage Abnormal" 2110 "Inside Voltage Abnormal" 2109 "Inside Voltage Abnormal" 2108 "Inside Voltage Abnormal" 2107 "Inside Voltage Abnormal" 2106 "Inside Voltage Abnormal" 2105 "Inside Voltage Abnormal" 2104 "Inside Voltage Abnormal" 2103 "Inside Voltage Abnormal" 2102 "Inside Voltage Abnormal" 2101 "Inside Voltage Abnormal" 2100 "Inside Voltage Abnormal" 2099 "Inside Voltage Abnormal" 2098 "Inside Voltage Abnormal" 2097 "Inside Voltage Abnormal" 2096 "Inside Voltage Abnormal" 2095 "Inside Voltage Abnormal" 2094 "Inside Voltage Abnormal" 2093 "Inside Voltage Abnormal" 2092 "Inside Voltage Abnormal" 2091 "Inside Voltage Abnormal" 2090 "Inside Voltage Abnormal" 2089 "Inside Voltage Abnormal" 2088 "Inside Voltage Abnormal" 2087 "Inside Voltage Abnormal" 2086 "Inside Voltage Abnormal" 2085 "Inside Voltage Abnormal" 2084 "Inside Voltage Abnormal" 2083 "Inside Voltage Abnormal" 2082 "Inside Voltage Abnormal" 2081 "Inside Voltage Abnormal" 2080 "Inside Voltage Abnormal" 2079 "Inside Voltage Abnormal" 2078 "Inside Voltage Abnormal" 2077 "Inside Voltage Abnormal" 2076 "Inside Voltage Abnormal" 2075 "Inside Voltage Abnormal" 2074 "Inside Voltage Abnormal" 2073 "Inside Voltage Abnormal" 2072 "Inside Voltage Abnormal" 2071 "Inside Voltage Abnormal" 2070 "Inside Voltage Abnormal" 2069 "Inside Voltage Abnormal" 2068 "Inside Voltage Abnormal" 2067 "Inside Voltage Abnormal" 2066 "Inside Voltage Abnormal" 2065 "Inside Voltage Abnormal" 2064 "Inside Voltage Abnormal" 2063 "Inside Voltage Abnormal" 2062 "Inside Voltage Abnormal" 2061 "Inside Voltage Abnormal" 2060 "Inside Voltage Abnormal" 2059 "Inside Voltage Abnormal" 2058 "Inside Voltage Abnormal" 2057 "Inside Voltage Abnormal" 2056 "Inside Voltage Abnormal" 2055 "Inside Voltage Abnormal" 2054 "Inside Voltage Abnormal" 2053 "Inside Voltage Abnormal" 2052 "Inside Voltage Abnormal" 2051 "Inside Voltage Abnormal" 2050 "Inside Voltage Abnormal" 2049 "Inside Voltage Abnormal" 2048 "Inside Voltage Abnormal" 2047 "Inside Voltage Abnormal" 2046 "Inside Voltage Abnormal" 2045 "Inside Voltage Abnormal" 2044 "Inside Voltage Abnormal" 2043 "Inside Voltage Abnormal" 2042 "Inside Voltage Abnormal" 2041 "Inside Voltage Abnormal" 2040 "Inside Voltage Abnormal" 2039 "Inside Voltage Abnormal" 2038 "Inside Voltage Abnormal" 2037 "Inside Voltage Abnormal" 2036 "Inside Voltage Abnormal" 2035 "Inside Voltage Abnormal" 2034 "Inside Voltage Abnormal" 2033 "Inside Voltage Abnormal" 2032 "Inside Voltage Abnormal" 2031 "Inside Voltage Abnormal" 2030 "Inside Voltage Abnormal" 2029 "Inside Voltage Abnormal" 2028 "Inside Voltage Abnormal" 2027 "Inside Voltage Abnormal" 2026 "Inside Voltage Abnormal" 2025 "Inside Voltage Abnormal" 2024 "Inside Voltage Abnormal" 2023 "Inside Voltage Abnormal" 2022 "Inside Voltage Abnormal" 2021 "Inside Voltage Abnormal" 2020 "Inside Voltage Abnormal" 2019 "Inside Voltage Abnormal" 2018 "Inside Voltage Abnormal" 2017 "Inside Voltage Abnormal" 2016 "Inside Voltage Abnormal" 2015 "Inside Voltage Abnormal" 2014 "Inside Voltage Abnormal" 2013 "Inside Voltage Abnormal" 2012 "Inside Voltage Abnormal" 2011 "Inside Voltage Abnormal" 2010 "Inside Voltage Abnormal" 2009 "Inside Voltage Abnormal" 2008 "Inside Voltage Abnormal" 2007 "Inside Voltage Abnormal" 2006 "Inside Voltage Abnormal" 2005 "Inside Voltage Abnormal" 2004 "Inside Voltage Abnormal" 2003 "Inside Voltage Abnormal" 2002 "Inside Voltage Abnormal" 2001 "Inside Voltage Abnormal" 2000 "Inside Voltage Abnormal" 1999 "Inside Voltage Abnormal" 1998 "Inside Voltage Abnormal" 1997 "Inside Voltage Abnormal" 1996 "Inside Voltage Abnormal" 1995 "Inside Voltage Abnormal" 1994 "Inside Voltage Abnormal" 1993 "Inside Voltage Abnormal" 1992 "Inside Voltage Abnormal" 1991 "Inside Voltage Abnormal" 1990 "Inside Voltage Abnormal" 1989 "Inside Voltage Abnormal" 1988 "Inside Voltage Abnormal" 1987 "Inside Voltage Abnormal" 1986 "Inside Voltage Abnormal" 1985 "Inside Voltage Abnormal" 1984 "Inside Voltage Abnormal" 1983 "Inside Voltage Abnormal" 1982 "Inside Voltage Abnormal" 1981 "Inside Voltage Abnormal" 1980 "Inside Voltage Abnormal" 1979 "Inside Voltage Abnormal" 1978 "Inside Voltage Abnormal" 1977 "Inside Voltage Abnormal" 1976 "Inside Voltage Abnormal" 1975 "Inside Voltage Abnormal" 1974 "Inside Voltage Abnormal" 1973 "Inside Voltage Abnormal" 1972 "Inside Voltage Abnormal" 1971 "Inside Voltage Abnormal" 1970 "Inside Voltage Abnormal" 1969 "Inside Voltage Abnormal" 1968 "Inside Voltage Abnormal" 1967 "Inside Voltage Abnormal" 1966 "Inside Voltage Abnormal" 1965 "Inside Voltage Abnormal" 1964 "Inside Voltage Abnormal" 1963 "Inside Voltage Abnormal" 1962 "Inside Voltage Abnormal" 1961 "Inside Voltage Abnormal" 1960 "Inside Voltage Abnormal" 1959 "Inside Voltage Abnormal" 1958 "Inside Voltage Abnormal" 1957 "Inside Voltage Abnormal" 1956 "Inside Voltage Abnormal" 1955 "Inside Voltage Abnormal" 1954 "Inside Voltage Abnormal" 1953 "Inside Voltage Abnormal" 1952 "Inside Voltage Abnormal" 1951 "Inside Voltage Abnormal" 1950 "Inside Voltage Abnormal" 1949 "Inside Voltage Abnormal" 1948 "Inside Voltage Abnormal" 1947 "Inside Voltage Abnormal" 1946 "Inside Voltage Abnormal" 1945 "Inside Voltage Abnormal" 1944 "Inside Voltage Abnormal" 1943 "Inside Voltage Abnormal" 1942 "Inside Voltage Abnormal" 1941 "Inside Voltage Abnormal" 1940 "Inside Voltage Abnormal" 1939 "Inside Voltage Abnormal" 1938 "Inside Voltage Abnormal" 1937 "Inside Voltage Abnormal" 1936 "Inside Voltage Abnormal" 1935 "Inside Voltage Abnormal" 1934 "Inside Voltage Abnormal" 1933 "Inside Voltage Abnormal" 1932 "Inside Voltage Abnormal" 1931 "Inside Voltage Abnormal" 1930 "Inside Voltage Abnormal" 1929 "Inside Voltage Abnormal" 1928 "Inside Voltage Abnormal" 1927 "Inside Voltage Abnormal" 1926 "Inside Voltage Abnormal" 1925 "Inside Voltage Abnormal" 1924 "Inside Voltage Abnormal" 1923 "Inside Voltage Abnormal" 1922 "Inside Voltage Abnormal" 1921 "Inside Voltage Abnormal" 1920 "Inside Voltage Abnormal" 1919 "Inside Voltage Abnormal" 1918 "Inside Voltage Abnormal" 1917 "Inside Voltage Abnormal" 1916 "Inside Voltage Abnormal" 1915 "Inside Voltage Abnormal" 1914 "Inside Voltage Abnormal" 1913 "Inside Voltage Abnormal" 1912 "Inside Voltage Abnormal" 1911 "Inside Voltage Abnormal" 1910 "Inside Voltage Abnormal" 1909 "Inside Voltage Abnormal" 1908 "Inside Voltage Abnormal" 1907 "Inside Voltage Abnormal" 1906 "Inside Voltage Abnormal" 1905 "Inside Voltage Abnormal" 1904 "Inside Voltage Abnormal" 1903 "Inside Voltage Abnormal" 1902 "Inside Voltage Abnormal" 1901 "Inside Voltage Abnormal" 1900 "Inside Voltage Abnormal" 1899 "Inside Voltage Abnormal" 1898 "Inside Voltage Abnormal" 1897 "Inside Voltage Abnormal" 1896 "Inside Voltage Abnormal" 1895 "Inside Voltage Abnormal" 1894 "Inside Voltage Abnormal" 1893 "Inside Voltage Abnormal" 1892 "Inside Voltage Abnormal" 1891 "Inside Voltage Abnormal" 1890 "Inside Voltage Abnormal" 1889 "Inside Voltage Abnormal" 1888 "Inside Voltage Abnormal" 1887 "Inside Voltage Abnormal" 1886 "Inside Voltage Abnormal" 1885 "Inside Voltage Abnormal" 1884 "Inside Voltage Abnormal" 1883 "Inside Voltage Abnormal" 1882 "Inside Voltage Abnormal" 1881 "Inside Voltage Abnormal" 1880 "Inside Voltage Abnormal" 1879 "Inside Voltage Abnormal" 1878 "Inside Voltage Abnormal" 1877 "Inside Voltage Abnormal" 1876 "Inside Voltage Abnormal" 1875 "Inside Voltage Abnormal" 1874 "Inside Voltage Abnormal" 1873 "Inside Voltage Abnormal" 1872 "Inside Voltage Abnormal" 1871 "Inside Voltage Abnormal" 1870 "Inside Voltage Abnormal" 1869 "Inside Voltage Abnormal" 1868 "Inside Voltage Abnormal" 1867 "Inside Voltage Abnormal" 1866 "Inside Voltage Abnormal" 1865 "Inside Voltage Abnormal" 1864 "Inside Voltage Abnormal" 1863 "Inside Voltage Abnormal" 1862 "Inside Voltage Abnormal" 1861 "Inside Voltage Abnormal" 1860 "Inside Voltage Abnormal" 1859 "Inside Voltage Abnormal" 1858 "Inside Voltage Abnormal" 1857 "Inside Voltage Abnormal" 1856 "Inside Voltage Abnormal" 1855 "Inside Voltage Abnormal" 1854 "Inside Voltage Abnormal" 1853 "Inside Voltage Abnormal" 1852 "Inside Voltage Abnormal" 1851 "Inside Voltage Abnormal" 1850 "Inside Voltage Abnormal" 1849 "Inside Voltage Abnormal" 1848 "Inside Voltage Abnormal" 1847 "Inside Voltage Abnormal" 1846 "Inside Voltage Abnormal" 1845 "Inside Voltage Abnormal" 1844 "Inside Voltage Abnormal" 1843 "Inside Voltage Abnormal" 1842 "Inside Voltage Abnormal" 1841 "Inside Voltage Abnormal" 1840 "Inside Voltage Abnormal" 1839 "Inside Voltage Abnormal" 1838 "Inside Voltage Abnormal" 1837 "Inside Voltage Abnormal" 1836 "Inside Voltage Abnormal" 1835 "Inside Voltage Abnormal" 1834 "Inside Voltage Abnormal" 1833 "Inside Voltage Abnormal" 1832 "Inside Voltage Abnormal" 1831 "Inside Voltage Abnormal" 1830 "Inside Voltage Abnormal" 1829 "Inside Voltage Abnormal" 1828 "Inside Voltage Abnormal" 1827 "Inside Voltage Abnormal" 1826 "Inside Voltage Abnormal" 1825 "Inside Voltage Abnormal" 1824 "Inside Voltage Abnormal" 1823 "Inside Voltage Abnormal" 1822 "Inside Voltage Abnormal" 1821 "Inside Voltage Abnormal" 1820 "Inside Voltage Abnormal" 1819 "Inside Voltage Abnormal" 1818 "Inside Voltage Abnormal" 1817 "Inside Voltage Abnormal" 1816 "Inside Voltage Abnormal" 1815 "Inside Voltage Abnormal" 1814 "Inside Voltage Abnormal" 1813 "Inside Voltage Abnormal" 1812 "Inside Voltage Abnormal" 1811 "Inside Voltage Abnormal" 1810 "Inside Voltage Abnormal" 1809 "Inside Voltage Abnormal" 1808 "Inside Voltage Abnormal" 1807 "Inside Voltage Abnormal" 1806 "Inside Voltage Abnormal" 1805 "Inside Voltage Abnormal" 1804 "Inside Voltage Abnormal" 1803 "Inside Voltage Abnormal" 1802 "Inside Voltage Abnormal" 1801 "Inside Voltage Abnormal" 1800 "Inside Voltage Abnormal" 1799 "Inside Voltage Abnormal" 1798 "Inside Voltage Abnormal" 1797 "Inside Voltage Abnormal" 1796 "Inside Voltage Abnormal" 1795 "Inside Voltage Abnormal" 1794 "Inside Voltage Abnormal" 1793 "Inside Voltage Abnormal" 1792 "Inside Voltage Abnormal" 1791 "Inside Voltage Abnormal" 1790 "Inside Voltage Abnormal" 1789 "Inside Voltage Abnormal" 1788 "Inside Voltage Abnormal" 1787 "Inside Voltage Abnormal" 1786 "Inside Voltage Abnormal" 1785 "Inside Voltage Abnormal" 1784 "Inside Voltage Abnormal" 1783 "Inside Voltage Abnormal" 1782 "Inside Voltage Abnormal" 1781 "Inside Voltage Abnormal" 1780 "Inside Voltage Abnormal" 1779 "Inside Voltage Abnormal" 1778 "Inside Voltage Abnormal" 1777 "Inside Voltage Abnormal" 1776 "Inside Voltage Abnormal" 1775 "Inside Voltage Abnormal" 1774 "Inside Voltage Abnormal" 1773 "Inside Voltage Abnormal" 1772 "Inside Voltage Abnormal" 1771 "Inside Voltage Abnormal" 1770 "Inside Voltage Abnormal" 1769 "Inside Voltage Abnormal" 1768 "Inside Voltage Abnormal" 1767 "Inside Voltage Abnormal" 1766 "Inside Voltage Abnormal" 1765 "Inside Voltage Abnormal" 1764 "Inside Voltage Abnormal" 1763 "Inside Voltage Abnormal" 1762 "Inside Voltage Abnormal" 1761 "Inside Voltage Abnormal" 1760 "Inside Voltage Abnormal" 1759 "Inside Voltage Abnormal" 1758 "Inside Voltage Abnormal" 1757 "Inside Voltage Abnormal" 1756 "Inside Voltage Abnormal" 1755 "Inside Voltage Abnormal" 1754 "Inside Voltage Abnormal" 1753 "Inside Voltage Abnormal" 1752 "Inside Voltage Abnormal" 1751 "Inside Voltage Abnormal" 1750 "Inside Voltage Abnormal" 1749 "Inside Voltage Abnormal" 1748 "Inside Voltage Abnormal" 1747 "Inside Voltage Abnormal" 1746 "Inside Voltage Abnormal" 1745 "Inside Voltage Abnormal" 1744 "Inside Voltage Abnormal" 1743 "Inside Voltage Abnormal" 1742 "Inside Voltage Abnormal" 1741 "Inside Voltage Abnormal" 1740 "Inside Voltage Abnormal" 1739 "Inside Voltage Abnormal" 1738 "Inside Voltage Abnormal" 1737 "Inside Voltage Abnormal" 1736 "Inside Voltage Abnormal" 1735 "Inside Voltage Abnormal" 1734 "Inside Voltage Abnormal" 1733 "Inside Voltage Abnormal" 1732 "Inside Voltage Abnormal" 1731 "Inside Voltage Abnormal" 1730 "Inside Voltage Abnormal" 1729 "Inside Voltage Abnormal" 1728 "Inside Voltage Abnormal" 1727 "Inside Voltage Abnormal" 1726 "Inside Voltage Abnormal" 1725 "Inside Voltage Abnormal" 1724 "Inside Voltage Abnormal" 1723 "Inside Voltage Abnormal" 1722 "Inside Voltage Abnormal" 1721 "Inside Voltage Abnormal" 1720 "Inside Voltage Abnormal" 1719 "Inside Voltage Abnormal" 1718 "Inside Voltage Abnormal" 1717 "Inside Voltage Abnormal" 1716 "Inside Voltage Abnormal" 1715 "Inside Voltage Abnormal" 1714 "Inside Voltage Abnormal" 1713 "Inside Voltage Abnormal" 1712 "Inside Voltage Abnormal" 1711 "Inside Voltage Abnormal" 1710 "Inside Voltage Abnormal" 1709 "Inside Voltage Abnormal" 1708 "Inside Voltage Abnormal" 1707 "Inside Voltage Abnormal" 1706 "Inside Voltage Abnormal" 1705 "Inside Voltage Abnormal" 1704 "Inside Voltage Abnormal" 1703 "Inside Voltage Abnormal" 1702 "Inside Voltage Abnormal" 1701 "Inside Voltage Abnormal" 1700 "Inside Voltage Abnormal" 1699 "Inside Voltage Abnormal" 1698 "Inside Voltage Abnormal" 1697 "Inside Voltage Abnormal" 1696 "Inside Voltage Abnormal" 1695 "Inside Voltage Abnormal" 1694 "Inside Voltage Abnormal" 1693 "Inside Voltage Abnormal" 1692 "Inside Voltage Abnormal" 1691 "Inside Voltage Abnormal" 1690 "Inside Voltage Abnormal" 1689 "Inside Voltage Abnormal" 1688 "Inside Voltage Abnormal" 1687 "Inside Voltage Abnormal" 1686 "Inside Voltage Abnormal" 1685 "Inside Voltage Abnormal" 1684 "Inside Voltage Abnormal" 1683 "Inside Voltage Abnormal" 1682 "Inside Voltage Abnormal" 1681 "Inside Voltage Abnormal" 1680 "Inside Voltage Abnormal" 1679 "Inside Voltage Abnormal" 1678 "Inside Voltage Abnormal" 1677 "Inside Voltage Abnormal" 1676 "Inside Voltage Abnormal" 1675 "Inside Voltage Abnormal" 1674 "Inside Voltage Abnormal" 1673 "Inside Voltage Abnormal" 1672 "Inside Voltage Abnormal" 1671 "Inside Voltage Abnormal" 1670 "Inside Voltage Abnormal" 1669 "Inside Voltage Abnormal" 1668 "Inside Voltage Abnormal" 1667 "Inside Voltage Abnormal" 1666 "Inside Voltage Abnormal" 1665 "Inside Voltage Abnormal" 1664 "Inside Voltage Abnormal" 1663 "Inside Voltage Abnormal" 1662 "Inside Voltage Abnormal" 1661 "Inside Voltage Abnormal" 1660 "Inside Voltage Abnormal" 1659 "Inside Voltage Abnormal" 1658 "Inside Voltage Abnormal" 1657 "Inside Voltage Abnormal" 1656 "Inside Voltage Abnormal" 1655 "Inside Voltage Abnormal" 1654 "Inside Voltage Abnormal" 1653 "Inside Voltage Abnormal" 1652 "Inside Voltage Abnormal" 1651 "Inside Voltage Abnormal" 1650 "Inside Voltage Abnormal" 1649 "Inside Voltage Abnormal" 1648 "Inside Voltage Abnormal" 1647 "Inside Voltage Abnormal" 1646 "Inside Voltage Abnormal" 1645 "Inside Voltage Abnormal" 1644 "Inside Voltage Abnormal" 1643 "Inside Voltage Abnormal" 1642 "Inside Voltage Abnormal" 1641 "Inside Voltage Abnormal" 1640 "Inside Voltage Abnormal" 1639 "Inside Voltage Abnormal" 1638 "Inside Voltage Abnormal" 1637 "Inside Voltage Abnormal" 1636 "Inside Voltage Abnormal" 1635 "Inside Voltage Abnormal" 1634 "Inside Voltage Abnormal" 1633 "Inside Voltage Abnormal" 1632 "Inside Voltage Abnormal" 1631 "Inside Voltage Abnormal" 1630 "Inside Voltage Abnormal" 1629 "Inside Voltage Abnormal" 1628 "Inside Voltage Abnormal" 1627 "Inside Voltage Abnormal" 1626 "Inside Voltage Abnormal" 1625 "Inside Voltage Abnormal" 1624 "Inside Voltage Abnormal" 1623 "Inside Voltage Abnormal" 1622 "Inside Voltage Abnormal" 1621 "Inside Voltage Abnormal" 1620 "Inside Voltage Abnormal" 1619 "Inside Voltage Abnormal" 1618 "Inside Voltage Abnormal" 1617 "Inside Voltage Abnormal" 1616 "Inside Voltage Abnormal" 1615 "Inside Voltage Abnormal" 1614 "Inside Voltage Abnormal" 1613 "Inside Voltage Abnormal" 1612 "Inside Voltage Abnormal" 1611 "Inside Voltage Abnormal" 1610 "Inside Voltage Abnormal" 1609 "Inside Voltage Abnormal" 1608 "Inside Voltage Abnormal" 1607 "Inside Voltage Abnormal" 1606 "Inside Voltage Abnormal" 1605 "Inside Voltage Abnormal" 1604 "Inside Voltage Abnormal" 1603 "Inside Voltage Abnormal" 1602 "Inside Voltage Abnormal" 1601 "Inside Voltage Abnormal" 1600 "Inside Voltage Abnormal" 1599 "Inside Voltage Abnormal" 1598 "Inside Voltage Abnormal" 1597 "Inside Voltage Abnormal" 1596 "Inside Voltage Abnormal" 1595 "Inside Voltage Abnormal" 1594 "Inside Voltage Abnormal" 1593 "Inside Voltage Abnormal" 1592 "Inside Voltage Abnormal" 1591 "Inside Voltage Abnormal" 1590 "Inside Voltage Abnormal" 1589 "Inside Voltage Abnormal" 1588 "Inside Voltage Abnormal" 1587 "Inside Voltage Abnormal" 1586 "Inside Voltage Abnormal" 1585 "Inside Voltage Abnormal" 1584 "Inside Voltage Abnormal" 1583 "Inside Voltage Abnormal" 1582 "Inside Voltage Abnormal" 1581 "Inside Voltage Abnormal" 1580 "Inside Voltage Abnormal" 1579 "Inside Voltage Abnormal" 1578 "Inside Voltage Abnormal" 1577 "Inside Voltage Abnormal" 1576 "Inside Voltage Abnormal" 1575 "Inside Voltage Abnormal" 1574 "Inside Voltage Abnormal" 1573 "Inside Voltage Abnormal" 1572 "Inside Voltage Abnormal" 1571 "Inside Voltage Abnormal" 1570 "Inside Voltage Abnormal" 1569 "Inside Voltage Abnormal" 1568 "Inside Voltage Abnormal" 1567 "Inside Voltage Abnormal" 1566 "Inside Voltage Abnormal" 1565 "Inside Voltage Abnormal" 1564 "Inside Voltage Abnormal" 1563 "Inside Voltage Abnormal" 1562 "Inside Voltage Abnormal" 1561 "Inside Voltage Abnormal" 1560 "Inside Voltage Abnormal" 1559 "Inside Voltage Abnormal" 1558 "Inside Voltage Abnormal" 1557 "Inside Voltage Abnormal" 1556 "Inside Voltage Abnormal" 1555 "Inside Voltage Abnormal" 1554 "Inside Voltage Abnormal" 1553 "Inside Voltage Abnormal" 1552 "Inside Voltage Abnormal" 1551 "Inside Voltage Abnormal" 1550 "Inside Voltage Abnormal" 1549 "Inside Voltage Abnormal" 1548 "Inside Voltage Abnormal" 1547 "Inside Voltage Abnormal" 1546 "Inside Voltage Abnormal" 1545 "Inside Voltage Abnormal" 1544 "Inside Voltage Abnormal" 1543 "Inside Voltage Abnormal" 1542 "Inside Voltage Abnormal" 1541 "Inside Voltage Abnormal" 1540 "Inside Voltage Abnormal" 1539 "Inside Voltage Abnormal" 1538 "Inside Voltage Abnormal" 1537 "Inside Voltage Abnormal" 1536 "Inside Voltage Abnormal" 1535 "Inside Voltage Abnormal" 1534 "Inside Voltage Abnormal" 1533 "Inside Voltage Abnormal" 1532 "Inside Voltage Abnormal" 1531 "Inside Voltage Abnormal" 1530 "Inside Voltage Abnormal" 1529 "Inside Voltage Abnormal" 1528 "Inside Voltage Abnormal" 1527 "Inside Voltage Abnormal" 1526 "Inside Voltage Abnormal" 1525 "Inside Voltage Abnormal" 1524 "Inside Voltage Abnormal" 1523 "Inside Voltage Abnormal" 1522 "Inside Voltage Abnormal" 1521 "Inside Voltage Abnormal" 1520 "Inside Voltage Abnormal" 1519 "Inside Voltage Abnormal" 1518 "Inside Voltage Abnormal" 1517 "Inside Voltage Abnormal" 1516 "Inside Voltage Abnormal" 1515 "Inside Voltage Abnormal" 1514 "Inside Voltage Abnormal" 1513 "Inside Voltage Abnormal" 1512 "Inside Voltage Abnormal" 1511 "Inside Voltage Abnormal" 1510 "Inside Voltage Abnormal" 1509 "Inside Voltage Abnormal" 1508 "Inside Voltage Abnormal" 1507 "Inside Voltage Abnormal" 1506 "Inside Voltage Abnormal" 1505 "Inside Voltage Abnormal" 1504 "Inside Voltage Abnormal" 1503 "Inside Voltage Abnormal" 1502 "Inside Voltage Abnormal" 1501 "Inside Voltage Abnormal" 1500 "Inside Voltage Abnormal" 1499 "Inside Voltage Abnormal" 1498 "Inside Voltage Abnormal" 1497 "Inside Voltage Abnormal" 1496 "Inside Voltage Abnormal" 1495 "Inside Voltage Abnormal" 1494 "Inside Voltage Abnormal" 1493 "Inside Voltage Abnormal" 1492 "Inside Voltage Abnormal" 1491 "Inside Voltage Abnormal" 1490 "Inside Voltage Abnormal" 1489 "Inside Voltage Abnormal" 1488 "Inside Voltage Abnormal" 1487 "Inside Voltage Abnormal" 1486 "Inside Voltage Abnormal" 1485 "Inside Voltage Abnormal" 1484 "Inside Voltage Abnormal" 1483 "Inside Voltage Abnormal" 1482 "Inside Voltage Abnormal" 1481 "Inside Voltage Abnormal" 1480 "Inside Voltage Abnormal" 1479 "Inside Voltage Abnormal" 1478 "Inside Voltage Abnormal" 1477 "Inside Voltage Abnormal" 1476 "Inside Voltage Abnormal" 1475 "Inside Voltage Abnormal" 1474 "Inside Voltage Abnormal" 1473 "Inside Voltage Abnormal" 1472 "Inside Voltage Abnormal" 1471 "Inside Voltage Abnormal" 1470 "Inside Voltage Abnormal" 1469 "Inside Voltage Abnormal" 1468 "Inside Voltage Abnormal" 1467 "Inside Voltage Abnormal" 1466 "Inside Voltage Abnormal" 1465 "Inside Voltage Abnormal" 1464 "Inside Voltage Abnormal" 1463 "Inside Voltage Abnormal" 1462 "Inside Voltage Abnormal" 1461 "Inside Voltage Abnormal" 1460 "Inside Voltage Abnormal" 1459 "Inside Voltage Abnormal" 1458 "Inside Voltage Abnormal" 1457 "Inside Voltage Abnormal" 1456 "Inside Voltage Abnormal" 1455 "Inside Voltage Abnormal" 1454 "Inside Voltage Abnormal" 1453 "Inside Voltage Abnormal" 1452 "Inside Voltage Abnormal" 1451 "Inside Voltage Abnormal" 1450 "Inside Voltage Abnormal" 1449 "Inside Voltage Abnormal" 1448 "Inside Voltage Abnormal" 1447 "Inside Voltage Abnormal" 1446 "Inside Voltage Abnormal" 1445 "Inside Voltage Abnormal" 1444 "Inside Voltage Abnormal" 1443 "Inside Voltage Abnormal" 1442 "Inside Voltage Abnormal" 1441 "Inside Voltage Abnormal" 1440 "Inside Voltage Abnormal" 1439 "Inside Voltage Abnormal" 1438 "Inside Voltage Abnormal" 1437 "Inside Voltage Abnormal" 1436 "Inside Voltage Abnormal" 1435 "Inside Voltage Abnormal" 1434 "Inside Voltage Abnormal" 1433 "Inside Voltage Abnormal" 1432 "Inside Voltage Abnormal" 1431 "Inside Voltage Abnormal" 1430 "Inside Voltage Abnormal" 1429 "Inside Voltage Abnormal" 1428 "Inside Voltage Abnormal" 1427 "Inside Voltage Abnormal" 1426 "Inside Voltage Abnormal" 1425 "Inside Voltage Abnormal" 1424 "Inside Voltage Abnormal" 1423 "Inside Voltage Abnormal" 1422 "Inside Voltage Abnormal" 1421 "Inside Voltage Abnormal" 1420 "Inside Voltage Abnormal" 1419 "Inside Voltage Abnormal" 1418 "Inside Voltage Abnormal" 1417 "Inside Voltage Abnormal" 1416 "Inside Voltage Abnormal" 1415 "Inside Voltage Abnormal" 1414 "Inside Voltage Abnormal" 1413 "Inside Voltage Abnormal" 1412 "Inside Voltage Abnormal" 1411 "Inside Voltage Abnormal" 1410 "Inside Voltage Abnormal" 1409 "Inside Voltage Abnormal" 1408 "Inside Voltage Abnormal" 1407 "Inside Voltage Abnormal" 1406 "Inside Voltage Abnormal" 1405 "Inside Voltage Abnormal" 1404 "Inside Voltage Abnormal" 1403 "Inside Voltage Abnormal" 1402 "Inside Voltage Abnormal" 1401 "Inside Voltage Abnormal" 1400 "Inside Voltage Abnormal" 1399 "Inside Voltage Abnormal" 1398 "Inside Voltage Abnormal" 1397 "Inside Voltage Abnormal" 1396 "Inside Voltage Abnormal" 1395 "Inside Voltage Abnormal" 1394 "Inside Voltage Abnormal" 1393 "Inside Voltage Abnormal" 1392 "Inside Voltage Abnormal" 1391 "Inside Voltage Abnormal" 1390 "Inside Voltage Abnormal" 1389 "Inside Voltage Abnormal" 1388 "Inside Voltage Abnormal" 1387 "Inside Voltage Abnormal" 1386 "Inside Voltage Abnormal" 1385 "Inside Voltage Abnormal" 1384 "Inside Voltage Abnormal" 1383 "Inside Voltage Abnormal" 1382 "Inside Voltage Abnormal" 1381 "Inside Voltage Abnormal" 1380 "Inside Voltage Abnormal" 1379 "Inside Voltage Abnormal" 1378 "Inside Voltage Abnormal" 1377 "Inside Voltage Abnormal" 1376 "Inside Voltage Abnormal" 1375 "Inside Voltage Abnormal" 1374 "Inside Voltage Abnormal" 1373 "Inside Voltage Abnormal" 1372 "Inside Voltage Abnormal" 1371 "Inside Voltage Abnormal" 1370 "Inside Voltage Abnormal" 1369 "Inside Voltage Abnormal" 1368 "Inside Voltage Abnormal" 1367 "Inside Voltage Abnormal" 1366 "Inside Voltage Abnormal" 1365 "Inside Voltage Abnormal" 1364 "Inside Voltage Abnormal" 1363 "Inside Voltage Abnormal" 1362 "Inside Voltage Abnormal" 1361 "Inside Voltage Abnormal" 1360 "Inside Voltage Abnormal" 1359 "Inside Voltage Abnormal" 1358 "Inside Voltage Abnormal" 1357 "Inside Voltage Abnormal" 1356 "Inside Voltage Abnormal" 1355 "Inside Voltage Abnormal" 1354 "Inside Voltage Abnormal" 1353 "Inside Voltage Abnormal" 1352 "Inside Voltage Abnormal" 1351 "Inside Voltage Abnormal" 1350 "Inside Voltage Abnormal" 1349 "Inside Voltage Abnormal" 1348 "Inside Voltage Abnormal" 1347 "Inside Voltage Abnormal" 1346 "Inside Voltage Abnormal" 1345 "Inside Voltage Abnormal" 1344 "Inside Voltage Abnormal" 1343 "Inside Voltage Abnormal" 1342 "Inside Voltage Abnormal" 1341 "Inside Voltage Abnormal" 1340 "Inside Voltage Abnormal" 1339 "Inside Voltage Abnormal" 1338 "Inside Voltage Abnormal" 1337 "Inside Voltage Abnormal" 1336 "Inside Voltage Abnormal" 1335 "Inside Voltage Abnormal" 1334 "Inside Voltage Abnormal" 1333 "Inside Voltage Abnormal" 1332 "Inside Voltage Abnormal" 1331 "Inside Voltage Abnormal" 1330 "Inside Voltage Abnormal" 1329 "Inside Voltage Abnormal" 1328 "Inside Voltage Abnormal" 1327 "Inside Voltage Abnormal" 1326 "Inside Voltage Abnormal" 1325 "Inside Voltage Abnormal" 1324 "Inside Voltage Abnormal" 1323 "Inside Voltage Abnormal" 1322 "Inside Voltage Abnormal" 1321 "Inside Voltage Abnormal" 1320 "Inside Voltage Abnormal" 1319 "Inside Voltage Abnormal" 1318 "Inside Voltage Abnormal" 1317 "Inside Voltage Abnormal" 1316 "Inside Voltage Abnormal" 1315 "Inside Voltage Abnormal" 1314 "Inside Voltage Abnormal" 1313 "Inside Voltage Abnormal" 1312 "Inside Voltage Abnormal" 1311 "Inside Voltage Abnormal" 1310 "Inside Voltage Abnormal" 1309 "Inside Voltage Abnormal" 1308 "Inside Voltage Abnormal" 1307 "Inside Voltage Abnormal" 1306 "Inside Voltage Abnormal" 1305 "Inside Voltage Abnormal" 1304 "Inside Voltage Abnormal" 1303 "Inside Voltage Abnormal" 1302 "Inside Voltage Abnormal" 1301 "Inside Voltage Abnormal" 1300 "Inside Voltage Abnormal" 1299 "Inside Voltage Abnormal" 1298 "Inside Voltage Abnormal" 1297 "Inside Voltage Abnormal" 1296 "Inside Voltage Abnormal" 1295 "Inside Voltage Abnormal" 1294 "Inside Voltage Abnormal" 1293 "Inside Voltage Abnormal" 1292 "Inside Voltage Abnormal" 1291 "Inside Voltage Abnormal" 1290 "Inside Voltage Abnormal" 1289 "Inside Voltage Abnormal" 1288 "Inside Voltage Abnormal" 1287 "Inside Voltage Abnormal" 1286 "Inside Voltage Abnormal" 1285 "Inside Voltage Abnormal" 1284 "Inside Voltage Abnormal" 1283 "Inside Voltage Abnormal" 1282 "Inside Voltage Abnormal" 1281 "Inside Voltage Abnormal" 1280 "Inside Voltage Abnormal" 1279 "Inside Voltage Abnormal" 1278 "Inside Voltage Abnormal" 1277 "Inside Voltage Abnormal" 1276 "Inside Voltage Abnormal" 1275 "Inside Voltage Abnormal" 1274 "Inside Voltage Abnormal" 1273 "Inside Voltage Abnormal" 1272 "Inside Voltage Abnormal" 1271 "Inside Voltage Abnormal" 1270 "Inside Voltage Abnormal" 1269 "Inside Voltage Abnormal" 1268 "Inside Voltage Abnormal" 1267 "Inside Voltage Abnormal" 1266 "Inside Voltage Abnormal" 1265 "Inside Voltage Abnormal" 1264 "Inside Voltage Abnormal" 1263 "Inside Voltage Abnormal" 1262 "Inside Voltage Abnormal" 1261 "Inside Voltage Abnormal" 1260 "Inside Voltage Abnormal" 1259 "Inside Voltage Abnormal" 1258 "Inside Voltage Abnormal" 1257 "Inside Voltage Abnormal" 1256 "Inside Voltage Abnormal" 1255 "Inside Voltage Abnormal" 1254 "Inside Voltage Abnormal" 1253 "Inside Voltage Abnormal" 1252 "Inside Voltage Abnormal" 1251 "Inside Voltage Abnormal" 1250 "Inside Voltage Abnormal" 1249 "Inside Voltage Abnormal" 1248 "Inside Voltage Abnormal" 1247 "Inside Voltage Abnormal" 1246 "Inside Voltage Abnormal" 1245 "Inside Voltage Abnormal" 1244 "Inside Voltage Abnormal" 1243 "Inside Voltage Abnormal" 1242 "Inside Voltage Abnormal" 1241 "Inside Voltage Abnormal" 1240 "Inside Voltage Abnormal" 1239 "Inside Voltage Abnormal" 1238 "Inside Voltage Abnormal" 1237 "Inside Voltage Abnormal" 1236 "Inside Voltage Abnormal" 1235 "Inside Voltage Abnormal" 1234 "Inside Voltage Abnormal" 1233 "Inside Voltage Abnormal" 1232 "Inside Voltage Abnormal" 1231 "Inside Voltage Abnormal" 1230 "Inside Voltage Abnormal" 1229 "Inside Voltage Abnormal" 1228 "Inside Voltage Abnormal" 1227 "Inside Voltage Abnormal" 1226 "Inside Voltage Abnormal" 1225 "Inside Voltage Abnormal" 1224 "Inside Voltage Abnormal" 1223 "Inside Voltage Abnormal" 1222 "Inside Voltage Abnormal" 1221 "Inside Voltage Abnormal" 1220 "Inside Voltage Abnormal" 1219 "Inside Voltage Abnormal" 1218 "Inside Voltage Abnormal" 1217 "Inside Voltage Abnormal" 1216 "Inside Voltage Abnormal" 1215 "Inside Voltage Abnormal" 1214 "Inside Voltage Abnormal" 1213 "Inside Voltage Abnormal" 1212 "Inside Voltage Abnormal" 1211 "Inside Voltage Abnormal" 1210 "Inside Voltage Abnormal" 1209 "Inside Voltage Abnormal" 1208 "Inside Voltage Abnormal" 1207 "Inside Voltage Abnormal" 1206 "Inside Voltage Abnormal" 1205 "Inside Voltage Abnormal" 1204 "Inside Voltage Abnormal" 1203 "Inside Voltage Abnormal" 1202 "Inside Voltage Abnormal" 1201 "Inside Voltage Abnormal" 1200 "Inside Voltage Abnormal" 1199 "Inside Voltage Abnormal" 1198 "Inside Voltage Abnormal" 1197 "Inside Voltage Abnormal" 1196 "Inside Voltage Abnormal" 1195 "Inside Voltage Abnormal" 1194 "Inside Voltage Abnormal" 1193 "Inside Voltage Abnormal" 1192 "Inside Voltage Abnormal" 1191 "Inside Voltage Abnormal" 1190 "Inside Voltage Abnormal" 1189 "Inside Voltage Abnormal" 1188 "Inside Voltage Abnormal" 1187 "Inside Voltage Abnormal" 1186 "Inside Voltage Abnormal" 1185 "Inside Voltage Abnormal" 1184 "Inside Voltage Abnormal" 1183 "Inside Voltage Abnormal" 1182 "Inside Voltage Abnormal" 1181 "Inside Voltage Abnormal" 1180 "Inside Voltage Abnormal" 1179 "Inside Voltage Abnormal" 1178 "Inside Voltage Abnormal" 1177 "Inside Voltage Abnormal" 1176 "Inside Voltage Abnormal" 1175 "Inside Voltage Abnormal" 1174 "Inside Voltage Abnormal" 1173 "Inside Voltage Abnormal" 1172 "Inside Voltage Abnormal" 1171 "Inside Voltage Abnormal" 1170 "Inside Voltage Abnormal" 1169 "Inside Voltage Abnormal" 1168 "Inside Voltage Abnormal" 1167 "Inside Voltage Abnormal" 1166 "Inside Voltage Abnormal" 1165 "Inside Voltage Abnormal" 1164 "Inside Voltage Abnormal" 1163 "Inside Voltage Abnormal" 1162 "Inside Voltage Abnormal" 1161 "Inside Voltage Abnormal" 1160 "Inside Voltage Abnormal" 1159 "Inside Voltage Abnormal" 1158 "Inside Voltage Abnormal" 1157 "Inside Voltage Abnormal" 1156 "Inside Voltage Abnormal" 1155 "Inside Voltage Abnormal" 1154 "Inside Voltage Abnormal" 1153 "Inside Voltage Abnormal" 1152 "Inside Voltage Abnormal" 1151 "Inside Voltage Abnormal" 1150 "Inside Voltage Abnormal" 1149 "Inside Voltage Abnormal" 1148 "Inside Voltage Abnormal" 1147 "Inside Voltage Abnormal" 1146 "Inside Voltage Abnormal" 1145 "Inside Voltage Abnormal" 1144 "Inside Voltage Abnormal" 1143 "Inside Voltage Abnormal" 1142 "Inside Voltage Abnormal" 1141 "Inside Voltage Abnormal" 1140 "Inside Voltage Abnormal" 1139 "Inside Voltage Abnormal" 1138 "Inside Voltage Abnormal" 1137 "Inside Voltage Abnormal" 1136 "Inside Voltage Abnormal" 1135 "Inside Voltage Abnormal" 1134 "Inside Voltage Abnormal" 1133 "Inside Voltage Abnormal" 1132 "Inside Voltage Abnormal" 1131 "Inside Voltage Abnormal" 1130 "Inside Voltage Abnormal" 1129 "Inside Voltage Abnormal" 1128 "Inside Voltage Abnormal" 1127 "Inside Voltage Abnormal" 1126 "Inside Voltage Abnormal" 1125 "Inside Voltage Abnormal" 1124 "Inside Voltage Abnormal" 1123 "Inside Voltage Abnormal" 1122 "Inside Voltage Abnormal" 1121 "Inside Voltage Abnormal" 1120 "Inside Voltage Abnormal" 1119 "Inside Voltage Abnormal" 1118 "Inside Voltage Abnormal" 1117 "Inside Voltage Abnormal" 1116 "Inside Voltage Abnormal" 1115 "Inside Voltage Abnormal" 1114 "Inside Voltage Abnormal" 1113 "Inside Voltage Abnormal" 1112 "Inside Voltage Abnormal" 1111 "Inside Voltage Abnormal" 1110 "Inside Voltage Abnormal" 1109 "Inside Voltage Abnormal" 1108 "Inside Voltage Abnormal" 1107 "Inside Voltage Abnormal" 1106 "Inside Voltage Abnormal" 1105 "Inside Voltage Abnormal" 1104 "Inside Voltage Abnormal" 1103 "Inside Voltage Abnormal" 1102 "Inside Voltage Abnormal" 1101 "Inside Voltage Abnormal" 1100 "Inside Voltage Abnormal" 1099 "Inside Voltage Abnormal" 1098 "Inside Voltage Abnormal" 1097 "Inside Voltage Abnormal" 1096 "Inside Voltage Abnormal" 1095 "Inside Voltage Abnormal" 1094 "Inside Voltage Abnormal" 1093 "Inside Voltage Abnormal" 1092 "Inside Voltage Abnormal" 1091 "Inside Voltage Abnormal" 1090 "Inside Voltage Abnormal" 1089 "Inside Voltage Abnormal" 1088 "Inside Voltage Abnormal" 1087 "Inside Voltage Abnormal" 1086 "Inside Voltage Abnormal" 1085 "Inside Voltage Abnormal" 1084 "Inside Voltage Abnormal" 1083 "Inside Voltage Abnormal" 1082 "Inside Voltage Abnormal" 1081 "Inside Voltage Abnormal" 1080 "Inside Voltage Abnormal" 1079 "Inside Voltage Abnormal" 1078 "Inside Voltage Abnormal" 1077 "Inside Voltage Abnormal" 1076 "Inside Voltage Abnormal" 1075 "Inside Voltage Abnormal" 1074 "Inside Voltage Abnormal" 1073 "Inside Voltage Abnormal" 1072 "Inside Voltage Abnormal" 1071 "Inside Voltage Abnormal" 1070 "Inside Voltage Abnormal" 1069 "Inside Voltage Abnormal" 1068 "Inside Voltage Abnormal" 1067 "Inside Voltage Abnormal" 1066 "Inside Voltage Abnormal" 1065 "Inside Voltage Abnormal" 1064 "Inside Voltage Abnormal" 1063 "Inside Voltage Abnormal" 1062 "Inside Voltage Abnormal" 1061 "Inside Voltage Abnormal" 1060 "Inside Voltage Abnormal" 1059 "Inside Voltage Abnormal" 1058 "Inside Voltage Abnormal" 1057 "Inside Voltage Abnormal" 1056 "Inside Voltage Abnormal" 1055 "Inside Voltage Abnormal" 1054 "Inside Voltage Abnormal" 1053 "Inside Voltage Abnormal" 1052 "Inside Voltage Abnormal" 1051 "Inside Voltage Abnormal" 1050 "Inside Voltage Abnormal" 1049 "Inside Voltage Abnormal" 1048 "Inside Voltage Abnormal" 1047 "Inside Voltage Abnormal" 1046 "Inside Voltage Abnormal" 1045 "Inside Voltage Abnormal" 1044 "Inside Voltage Abnormal" 1043 "Inside Voltage Abnormal" 1042 "Inside Voltage Abnormal" 1041 "Inside Voltage Abnormal" 1040 "Inside Voltage Abnormal" 1039 "Inside Voltage Abnormal" 1038 "Inside Voltage Abnormal" 1037 "Inside Voltage Abnormal" 1036 "Inside Voltage Abnormal" 1035 "Inside Voltage Abnormal" 1034 "Inside Voltage Abnormal" 1033 "Inside Voltage Abnormal" 1032 "Inside Voltage Abnormal" 1031 "Inside Voltage Abnormal" 1030 "Inside Voltage Abnormal" 1029 "Inside Voltage Abnormal" 1028 "Inside Voltage Abnormal" 1027 "Inside Voltage Abnormal" 1026 "Inside Voltage Abnormal" 1025 "Inside Voltage Abnormal" 1024 "Inside Voltage Abnormal" 1023 "Inside Voltage Abnormal" 1022 "Inside Voltage Abnormal" 1021 "Inside Voltage Abnormal" 1020 "Inside Voltage Abnormal" 1019 "Inside Voltage Abnormal" 1018 "Inside Voltage Abnormal" 1017 "Inside Voltage Abnormal" 1016 "Inside Voltage Abnormal" 1015 "Inside Voltage Abnormal" 1014 "Inside Voltage Abnormal" 1013 "Inside Voltage Abnormal" 1012 "Inside Voltage Abnormal" 1011 "Inside Voltage Abnormal" 1010 "Inside Voltage Abnormal" 1009 "Inside Voltage Abnormal" 1008 "Inside Voltage Abnormal" 1007 "Inside Voltage Abnormal" 1006 "Inside Voltage Abnormal" 1005 "Inside Voltage Abnormal" 1004 "Inside Voltage Abnormal" 1003 "Inside Voltage Abnormal" 1002 "Inside Voltage Abnormal" 1001 "Inside Voltage Abnormal" 1000 "Inside Voltage Abnormal" 999 "Inside Voltage Abnormal" 998 "Inside Voltage Abnormal" 997 "Inside Voltage Abnormal" 996 "Inside Voltage Abnormal" 995 "Inside Voltage Abnormal" 994 "Inside Voltage Abnormal" 993 "Inside Voltage Abnormal" 992 "Inside Voltage Abnormal" 991 "Inside Voltage Abnormal" 990 "Inside Voltage Abnormal" 989 "Inside Voltage Abnormal" 988 "Inside Voltage Abnormal" 987 "Inside Voltage Abnormal" 986 "Inside Voltage Abnormal" 985 "Inside Voltage Abnormal" 984 "Inside Voltage Abnormal" 983 "Inside Voltage Abnormal" 982 "Inside Voltage Abnormal" 981 "Inside Voltage Abnormal" 980 "Inside Voltage Abnormal" 979 "Inside Voltage Abnormal" 978 "Inside Voltage Abnormal" 977 "Inside Voltage Abnormal" 976 "Inside Voltage Abnormal" 975 "Inside Voltage Abnormal" 974 "Inside Voltage Abnormal" 973 "Inside Voltage Abnormal" 972 "Inside Voltage Abnormal" 971 "Inside Voltage Abnormal" 970 "Inside Voltage Abnormal" 969 "Inside Voltage Abnormal" 968 "Inside Voltage Abnormal" 967 "Inside Voltage Abnormal" 966 "Inside Voltage Abnormal" 965 "Inside Voltage Abnormal" 964 "Inside Voltage Abnormal" 963 "Inside Voltage Abnormal" 962 "Inside Voltage Abnormal" 961 "Inside Voltage Abnormal" 960 "Inside Voltage Abnormal" 959 "Inside Voltage Abnormal" 958 "Inside Voltage Abnormal" 957 "Inside Voltage Abnormal" 956 "Inside Voltage Abnormal" 955 "Inside Voltage Abnormal" 954 "Inside Voltage Abnormal" 953 "Inside Voltage Abnormal" 952 "Inside Voltage Abnormal" 951 "Inside Voltage Abnormal" 950 "Inside Voltage Abnormal" 949 "Inside Voltage Abnormal" 948 "Inside Voltage Abnormal" 947 "Inside Voltage Abnormal" 946 "Inside Voltage Abnormal" 945 "Inside Voltage Abnormal" 944 "Inside Voltage Abnormal" 943 "Inside Voltage Abnormal" 942 "Inside Voltage Abnormal" 941 "Inside Voltage Abnormal" 940 "Inside Voltage Abnormal" 939 "Inside Voltage Abnormal" 938 "Inside Voltage Abnormal" 937 "Inside Voltage Abnormal" 936 "Inside Voltage Abnormal" 935 "Inside Voltage Abnormal" 934 "Inside Voltage Abnormal" 933 "Inside Voltage Abnormal" 932 "Inside Voltage Abnormal" 931 "Inside Voltage Abnormal" 930 "Inside Voltage Abnormal" 929 "Inside Voltage Abnormal" 928 "Inside Voltage Abnormal" 927 "Inside Voltage Abnormal" 926 "Inside Voltage Abnormal" 925 "Inside Voltage Abnormal" 924 "Inside Voltage Abnormal" 923 "Inside Voltage Abnormal" 922 "Inside Voltage Abnormal" 921 "Inside Voltage Abnormal" 920 "Inside Voltage Abnormal" 919 "Inside Voltage Abnormal" 918 "Inside Voltage Abnormal" 917 "Inside Voltage Abnormal" 916 "Inside Voltage Abnormal" 915 "Inside Voltage Abnormal" 914 "Inside Voltage Abnormal" 913 "Inside Voltage Abnormal" 912 "Inside Voltage Abnormal" 911 "Inside Voltage Abnormal" 910 "Inside Voltage Abnormal" 909 "Inside Voltage Abnormal" 908 "Inside Voltage Abnormal" 907 "Inside Voltage Abnormal" 906 "Inside Voltage Abnormal" 905 "Inside Voltage Abnormal" 904 "Inside Voltage Abnormal" 903 "Inside Voltage Abnormal" 902 "Inside Voltage Abnormal" 901 "Inside Voltage Abnormal" 900 "Inside Voltage Abnormal" 899 "Inside Voltage Abnormal" 898 "Inside Voltage Abnormal" 897 "Inside Voltage Abnormal" 896 "Inside Voltage Abnormal" 895 "Inside Voltage Abnormal" 894 "Inside Voltage Abnormal" 893 "Inside Voltage Abnormal" 892 "Inside Voltage Abnormal" 891 "Inside Voltage Abnormal" 890 "Inside Voltage Abnormal" 889 "Inside Voltage Abnormal" 888 "Inside Voltage Abnormal" 887 "Inside Voltage Abnormal" 886 "Inside Voltage Abnormal" 885 "Inside Voltage Abnormal" 884 "Inside Voltage Abnormal" 883 "Inside Voltage Abnormal" 882 "Inside Voltage Abnormal" 881 "Inside Voltage Abnormal" 880 "Inside Voltage Abnormal" 879 "Inside Voltage Abnormal" 878 "Inside Voltage Abnormal" 877 "Inside Voltage Abnormal" 876 "Inside Voltage Abnormal" 875 "Inside Voltage Abnormal" 874 "Inside Voltage Abnormal" 873 "Inside Voltage Abnormal" 872 "Inside Voltage Abnormal" 871 "Inside Voltage Abnormal" 870 "Inside Voltage Abnormal" 869 "Inside Voltage Abnormal" 868 "Inside Voltage Abnormal" 867 "Inside Voltage Abnormal" 866 "Inside Voltage Abnormal" 865 "Inside Voltage Abnormal" 864 "Inside Voltage Abnormal" 863 "Inside Voltage Abnormal" 862 "Inside Voltage Abnormal" 861 "Inside Voltage Abnormal" 860 "Inside Voltage Abnormal" 859 "Inside Voltage Abnormal" 858 "Inside Voltage Abnormal" 857 "Inside Voltage Abnormal" 856 "Inside Voltage Abnormal" 855 "Inside Voltage Abnormal" 854 "Inside Voltage Abnormal" 853 "Inside Voltage Abnormal" 852 "Inside Voltage Abnormal" 851 "Inside Voltage Abnormal" 850 "Inside Voltage Abnormal" 849 "Inside Voltage Abnormal" 848 "Inside Voltage Abnormal" 847 "Inside Voltage Abnormal" 846 "Inside Voltage Abnormal" 845 "Inside Voltage Abnormal" 844 "Inside Voltage Abnormal" 843 "Inside Voltage Abnormal" 842 "Inside Voltage Abnormal" 841 "Inside Voltage Abnormal" 840 "Inside Voltage Abnormal" 839 "Inside Voltage Abnormal" 838 "Inside Voltage Abnormal" 837 "Inside Voltage Abnormal" 836 "Inside Voltage Abnormal" 835 "Inside Voltage Abnormal" 834 "Inside Voltage Abnormal" 833 "Inside Voltage Abnormal" 832 "Inside Voltage Abnormal" 831 "Inside Voltage Abnormal" 830 "Inside Voltage Abnormal" 829 "Inside Voltage Abnormal" 828 "Inside Voltage Abnormal" 827 "Inside Voltage Abnormal" 826 "Inside Voltage Abnormal" 825 "Inside Voltage Abnormal" 824 "Inside Voltage Abnormal" 823 "Inside Voltage Abnormal" 822 "Inside Voltage Abnormal" 821 "Inside Voltage Abnormal" 820 "Inside Voltage Abnormal" 819 "Inside Voltage Abnormal" 818 "Inside Voltage Abnormal" 817 "Inside Voltage Abnormal" 816 "Inside Voltage Abnormal" 815 "Inside Voltage Abnormal" 814 "Inside Voltage Abnormal" 813 "Inside Voltage Abnormal" 812 "Inside Voltage Abnormal" 811 "Inside Voltage Abnormal" 810 "Inside Voltage Abnormal" 809 "Inside Voltage Abnormal" 808 "Inside Voltage Abnormal" 807 "Inside Voltage Abnormal" 806 "Inside Voltage Abnormal" 805 "Inside Voltage Abnormal" 804 "Inside Voltage Abnormal" 803 "Inside Voltage Abnormal" 802 "Inside Voltage Abnormal" 801 "Inside Voltage Abnormal" 800 "Inside Voltage Abnormal" 799 "Inside Voltage Abnormal" 798 "Inside Voltage Abnormal" 797 "Inside Voltage Abnormal" 796 "Inside Voltage Abnormal" 795 "Inside Voltage Abnormal" 794 "Inside Voltage Abnormal" 793 "Inside Voltage Abnormal" 792 "Inside Voltage Abnormal" 791 "Inside Voltage Abnormal" 790 "Inside Voltage Abnormal" 789 "Inside Voltage Abnormal" 788 "Inside Voltage Abnormal" 787 "Inside Voltage Abnormal" 786 "Inside Voltage Abnormal" 785 "Inside Voltage Abnormal" 784 "Inside Voltage Abnormal" 783 "Inside Voltage Abnormal" 782 "Inside Voltage Abnormal" 781 "Inside Voltage Abnormal" 780 "Inside Voltage Abnormal" 779 "Inside Voltage Abnormal" 778 "Inside Voltage Abnormal" 777 "Inside Voltage Abnormal" 776 "Inside Voltage Abnormal" 775 "Inside Voltage Abnormal" 774 "Inside Voltage Abnormal" 773 "Inside Voltage Abnormal" 772 "Inside Voltage Abnormal" 771 "Inside Voltage Abnormal" 770 "Inside Voltage Abnormal" 769 "Inside Voltage Abnormal" 768 "Inside Voltage Abnormal" 767 "Inside Voltage Abnormal" 766 "Inside Voltage Abnormal" 765 "Inside Voltage Abnormal" 764 "Inside Voltage Abnormal" 763 "Inside Voltage Abnormal" 762 "Inside Voltage Abnormal" 761 "Inside Voltage Abnormal" 760 "Inside Voltage Abnormal" 759 "Inside Voltage Abnormal" 758 "Inside Voltage Abnormal" 757 "Inside Voltage Abnormal" 756 "Inside Voltage Abnormal" 755 "Inside Voltage Abnormal" 754 "Inside Voltage Abnormal" 753 "Inside Voltage Abnormal" 752 "Inside Voltage Abnormal" 751 "Inside Voltage Abnormal" 750 "Inside Voltage Abnormal" 749 "Inside Voltage Abnormal" 748 "Inside Voltage Abnormal" 747 "Inside Voltage Abnormal" 746 "Inside Voltage Abnormal" 745 "Inside Voltage Abnormal" 744 "Inside Voltage Abnormal" 743 "Inside Voltage Abnormal" 742 "Inside Voltage Abnormal" 741 "Inside Voltage Abnormal" 740 "Inside Voltage Abnormal" 739 "Inside Voltage Abnormal" 738 "Inside Voltage Abnormal" 737 "Inside Voltage Abnormal" 736 "Inside Voltage Abnormal" 735 "Inside Voltage Abnormal" 734 "Inside Voltage Abnormal" 733 "Inside Voltage Abnormal" 732 "Inside Voltage Abnormal" 731 "Inside Voltage Abnormal" 730 "Inside Voltage Abnormal" 729 "Inside Voltage Abnormal" 728 "Inside Voltage Abnormal" 727 "Inside Voltage Abnormal" 726 "Inside Voltage Abnormal" 725 "Inside Voltage Abnormal" 724 "Inside Voltage Abnormal" 723 "Inside Voltage Abnormal" 722 "Inside Voltage Abnormal" 721 "Inside Voltage Abnormal" 720 "Inside Voltage Abnormal" 719 "Inside Voltage Abnormal" 718 "Inside Voltage Abnormal" 717 "Inside Voltage Abnormal" 716 "Inside Voltage Abnormal" 715 "Inside Voltage Abnormal" 714 "Inside Voltage Abnormal" 713 "Inside Voltage Abnormal" 712 "Inside Voltage Abnormal" 711 "Inside Voltage Abnormal" 710 "Inside Voltage Abnormal" 709 "Inside Voltage Abnormal" 708 "Inside Voltage Abnormal" 707 "Inside Voltage Abnormal" 706 "Inside Voltage Abnormal" 705 "Inside Voltage Abnormal" 704 "Inside Voltage Abnormal" 703 "Inside Voltage Abnormal" 702 "Inside Voltage Abnormal" 701 "Inside Voltage Abnormal" 700 "Inside Voltage Abnormal" 699 "Inside Voltage Abnormal" 698 "Inside Voltage Abnormal" 697 "Inside Voltage Abnormal" 696 "Inside Voltage Abnormal" 695 "Inside Voltage Abnormal" 694 "Inside Voltage Abnormal" 693 "Inside Voltage Abnormal" 692 "Inside Voltage Abnormal" 691 "Inside Voltage Abnormal" 690 "Inside Voltage Abnormal" 689 "Inside Voltage Abnormal" 688 "Inside Voltage Abnormal" 687 "Inside Voltage Abnormal" 686 "Inside Voltage Abnormal" 685 "Inside Voltage Abnormal" 684 "Inside Voltage Abnormal" 683 "Inside Voltage Abnormal" 682 "Inside Voltage Abnormal" 681 "Inside Voltage Abnormal" 680 "Inside Voltage Abnormal" 679 "Inside Voltage Abnormal" 678 "Inside Voltage Abnormal" 677 "Inside Voltage Abnormal" 676 "Inside Voltage Abnormal" 675 "Inside Voltage Abnormal" 674 "Inside Voltage Abnormal" 673 "Inside Voltage Abnormal" 672 "Inside Voltage Abnormal" 671 "Inside Voltage Abnormal" 670 "Inside Voltage Abnormal" 669 "Inside Voltage Abnormal" 668 "Inside Voltage Abnormal" 667 "Inside Voltage Abnormal" 666 "Inside Voltage Abnormal" 665 "Inside Voltage Abnormal" 664 "Inside Voltage Abnormal" 663 "Inside Voltage Abnormal" 662 "Inside Voltage Abnormal" 661 "Inside Voltage Abnormal" 660 "Inside Voltage Abnormal" 659 "Inside Voltage Abnormal" 658 "Inside Voltage Abnormal" 657 "Inside Voltage Abnormal" 656 "Inside Voltage Abnormal" 655 "Inside Voltage Abnormal" 654 "Inside Voltage Abnormal" 653 "Inside Voltage Abnormal" 652 "Inside Voltage Abnormal" 651 "Inside Voltage Abnormal" 650 "Inside Voltage Abnormal" 649 "Inside Voltage Abnormal" 648 "Inside Voltage Abnormal" 647 "Inside Voltage Abnormal" 646 "Inside Voltage Abnormal" 645 "Inside Voltage Abnormal" 644 "Inside Voltage Abnormal" 643 "Inside Voltage Abnormal" 642 "Inside Voltage Abnormal" 641 "Inside Voltage Abnormal" 640 "Inside Voltage Abnormal" 639 "Inside Voltage Abnormal" 638 "Inside Voltage Abnormal" 637 "Inside Voltage Abnormal" 636 "Inside Voltage Abnormal" 635 "Inside Voltage Abnormal" 634 "Inside Voltage Abnormal" 633 "Inside Voltage Abnormal" 632 "Inside Voltage Abnormal" 631 "Inside Voltage Abnormal" 630 "Inside Voltage Abnormal" 629 "Inside Voltage Abnormal" 628 "Inside Voltage Abnormal" 627 "Inside Voltage Abnormal" 626 "Inside Voltage Abnormal" 625 "Inside Voltage Abnormal" 624 "Inside Voltage Abnormal" 623 "Inside Voltage Abnormal" 622 "Inside Voltage Abnormal" 621 "Inside Voltage Abnormal" 620 "Inside Voltage Abnormal" 619 "Inside Voltage Abnormal" 618 "Inside Voltage Abnormal" 617 "Inside Voltage Abnormal" 616 "Inside Voltage Abnormal" 615 "Inside Voltage Abnormal" 614 "Inside Voltage Abnormal" 613 "Inside Voltage Abnormal" 612 "Inside Voltage Abnormal" 611 "Inside Voltage Abnormal" 610 "Inside Voltage Abnormal" 609 "Inside Voltage Abnormal" 608 "Inside Voltage Abnormal" 607 "Inside Voltage Abnormal" 606 "Inside Voltage Abnormal" 605 "Inside Voltage Abnormal" 604 "Inside Voltage Abnormal" 603 "Inside Voltage Abnormal" 602 "Inside Voltage Abnormal" 601 "Inside Voltage Abnormal" 600 "Inside Voltage Abnormal" 599 "Inside Voltage Abnormal" 598 "Inside Voltage Abnormal" 597 "Inside Voltage Abnormal" 596 "Inside Voltage Abnormal" 595 "Inside Voltage Abnormal" 594 "Inside Voltage Abnormal" 593 "Inside Voltage Abnormal" 592 "Inside Voltage Abnormal" 591 "Inside Voltage Abnormal" 590 "Inside Voltage Abnormal" 589 "Inside Voltage Abnormal" 588 "Inside Voltage Abnormal" 587 "Inside Voltage Abnormal" 586 "Inside Voltage Abnormal" 585 "Inside Voltage Abnormal" 584 "Inside Voltage Abnormal" 583 "Inside Voltage Abnormal" 582 "Inside Voltage Abnormal" 581 "Inside Voltage Abnormal" 580 "Inside Voltage Abnormal" 579 "Inside Voltage Abnormal" 578 "Inside Voltage Abnormal" 577 "Inside Voltage Abnormal" 576 "Inside Voltage Abnormal" 575 "Inside Voltage Abnormal" 574 "Inside Voltage Abnormal" 573 "Inside Voltage Abnormal" 572 "Inside Voltage Abnormal" 571 "Inside Voltage Abnormal" 570 "Inside Voltage Abnormal" 569 "Inside Voltage Abnormal" 568 "Inside Voltage Abnormal" 567 "Inside Voltage Abnormal" 566 "Inside Voltage Abnormal" 565 "Inside Voltage Abnormal" 564 "Inside Voltage Abnormal" 563 "Inside Voltage Abnormal" 562 "Inside Voltage Abnormal" 561 "Inside Voltage Abnormal" 560 "Inside Voltage Abnormal" 559 "Inside Voltage Abnormal" 558 "Inside Voltage Abnormal" 557 "Inside Voltage Abnormal" 556 "Inside Voltage Abnormal" 555 "Inside Voltage Abnormal" 554 "Inside Voltage Abnormal" 553 "Inside Voltage Abnormal" 552 "Inside Voltage Abnormal" 551 "Inside Voltage Abnormal" 550 "Inside Voltage Abnormal" 549 "Inside Voltage Abnormal" 548 "Inside Voltage Abnormal" 547 "Inside Voltage Abnormal" 546 "Inside Voltage Abnormal" 545 "Inside Voltage Abnormal" 544 "Inside Voltage Abnormal" 543 "Inside Voltage Abnormal" 542 "Inside Voltage Abnormal" 541 "Inside Voltage Abnormal" 540 "Inside Voltage Abnormal" 539 "Inside Voltage Abnormal" 538 "Inside Voltage Abnormal" 537 "Inside Voltage Abnormal" 536 "Inside Voltage Abnormal" 535 "Inside Voltage Abnormal" 534 "Inside Voltage Abnormal" 533 "Inside Voltage Abnormal" 532 "Inside Voltage Abnormal" 531 "Inside Voltage Abnormal" 530 "Inside Voltage Abnormal" 529 "Inside Voltage Abnormal" 528 "Inside Voltage Abnormal" 527 "Inside Voltage Abnormal" 526 "Inside Voltage Abnormal" 525 "Inside Voltage Abnormal" 524 "Inside Voltage Abnormal" 523 "Inside Voltage Abnormal" 522 "Inside Voltage Abnormal" 521 "Inside Voltage Abnormal" 520 "Inside Voltage Abnormal" 519 "Inside Voltage Abnormal" 518 "Inside Voltage Abnormal" 517 "Inside Voltage Abnormal" 516 "Inside Voltage Abnormal" 515 "Inside Voltage Abnormal" 514 "Inside Voltage Abnormal" 513 "Inside Voltage Abnormal" 512 "Inside Voltage Abnormal" 511 "Inside Voltage Abnormal" 510 "Inside Voltage Abnormal" 509 "Inside Voltage Abnormal" 508 "Inside Voltage Abnormal" 507 "Inside Voltage Abnormal" 506 "Inside Voltage Abnormal" 505 "Inside Voltage Abnormal" 504 "Inside Voltage Abnormal" 503 "Inside Voltage Abnormal" 502 "Inside Voltage Abnormal" 501 "Inside Voltage Abnormal" 500 "Inside Voltage Abnormal" 499 "Inside Voltage Abnormal" 498 "Inside Voltage Abnormal" 497 "Inside Voltage Abnormal" 496 "Inside Voltage Abnormal" 495 "Inside Voltage Abnormal" 494 "Inside Voltage Abnormal" 493 "Inside Voltage Abnormal" 492 "Inside Voltage Abnormal" 491 "Inside Voltage Abnormal" 490 "Inside Voltage Abnormal" 489 "Inside Voltage Abnormal" 488 "Inside Voltage Abnormal" 487 "Inside Voltage Abnormal" 486 "Inside Voltage Abnormal" 485 "Inside Voltage Abnormal" 484 "Inside Voltage Abnormal" 483 "Inside Voltage Abnormal" 482 "Inside Voltage Abnormal" 481 "Inside Voltage Abnormal" 480 "Inside Voltage Abnormal" 479 "Inside Voltage Abnormal" 478 "Inside Voltage Abnormal" 477 "Inside Voltage Abnormal" 476 "Inside Voltage Abnormal" 475 "Inside Voltage Abnormal" 474 "Inside Voltage Abnormal" 473 "Inside Voltage Abnormal" 472 "Inside Voltage Abnormal" 471 "Inside Voltage Abnormal" 470 "Inside Voltage Abnormal" 469 "Inside Voltage Abnormal" 468 "Inside Voltage Abnormal" 467 "Inside Voltage Abnormal" 466 "Inside Voltage Abnormal" 465 "Inside Voltage Abnormal" 464 "Inside Voltage Abnormal" 463 "Inside Voltage Abnormal" 462 "Inside Voltage Abnormal" 461 "Inside Voltage Abnormal" 460 "Inside Voltage Abnormal" 459 "Inside Voltage Abnormal" 458 "Inside Voltage Abnormal" 457 "Inside Voltage Abnormal" 456 "Inside Voltage Abnormal" 455 "Inside Voltage Abnormal" 454 "Inside Voltage Abnormal" 453 "Inside Voltage Abnormal" 452 "Inside Voltage Abnormal" 451 "Inside Voltage Abnormal" 450 "Inside Voltage Abnormal" 449 "Inside Voltage Abnormal" 448 "Inside Voltage Abnormal" 447 "Inside Voltage Abnormal" 446 "Inside Voltage Abnormal" 445 "Inside Voltage Abnormal" 444 "Inside Voltage Abnormal" 443 "Inside Voltage Abnormal" 442 "Inside Voltage Abnormal" 441 "Inside Voltage Abnormal" 440 "Inside Voltage Abnormal" 439 "Inside Voltage Abnormal" 438 "Inside Voltage Abnormal" 437 "Inside Voltage Abnormal" 436 "Inside Voltage Abnormal" 435 "Inside Voltage Abnormal" 434 "Inside Voltage Abnormal" 433 "Inside Voltage Abnormal" 432 "Inside Voltage Abnormal" 431 "Inside Voltage Abnormal" 430 "Inside Voltage Abnormal" 429 "Inside Voltage Abnormal" 428 "Inside Voltage Abnormal" 427 "Inside Voltage Abnormal" 426 "Inside Voltage Abnormal" 425 "Inside Voltage Abnormal" 424 "Inside Voltage Abnormal" 423 "Inside Voltage Abnormal" 422 "Inside Voltage Abnormal" 421 "Inside Voltage Abnormal" 420 "Inside Voltage Abnormal" 419 "Inside Voltage Abnormal" 418 "Inside Voltage Abnormal" 417 "Inside Voltage Abnormal" 416 "Inside Voltage Abnormal" 415 "Inside Voltage Abnormal" 414 "Inside Voltage Abnormal" 413 "Inside Voltage Abnormal" 412 "Inside Voltage Abnormal" 411 "Inside Voltage Abnormal" 410 "Inside Voltage Abnormal" 409 "Inside Voltage Abnormal" 408 "Inside Voltage Abnormal" 407 "Inside Voltage Abnormal" 406 "Inside Voltage Abnormal" 405 "Inside Voltage Abnormal" 404 "Inside Voltage Abnormal" 403 "Inside Voltage Abnormal" 402 "Inside Voltage Abnormal" 401 "Inside Voltage Abnormal" 400 "Inside Voltage Abnormal" 399 "Inside Voltage Abnormal" 398 "Inside Voltage Abnormal" 397 "Inside Voltage Abnormal" 396 "Inside Voltage Abnormal" 395 "Inside Voltage Abnormal" 394 "Inside Voltage Abnormal" 393 "Inside Voltage Abnormal" 392 "Inside Voltage Abnormal" 391 "Inside Voltage Abnormal" 390 "Inside Voltage Abnormal" 389 "Inside Voltage Abnormal" 388 "Inside Voltage Abnormal" 387 "Inside Voltage Abnormal" 386 "Inside Voltage Abnormal" 385 "Inside Voltage Abnormal" 384 "Inside Voltage Abnormal" 383 "Inside Voltage Abnormal" 382 "Inside Voltage Abnormal" 381 "Inside Voltage Abnormal" 380 "Inside Voltage Abnormal" 379 "Inside Voltage Abnormal" 378 "Inside Voltage Abnormal" 377 "Inside Voltage Abnormal" 376 "Inside Voltage Abnormal" 375 "Inside Voltage Abnormal" 374 "Inside Voltage Abnormal" 373 "Inside Voltage Abnormal" 372 "Inside Voltage Abnormal" 371 "Inside Voltage Abnormal" 370 "Inside Voltage Abnormal" 369 "Inside Voltage Abnormal" 368 "Inside Voltage Abnormal" 367 "Inside Voltage Abnormal" 366 "Inside Voltage Abnormal" 365 "Inside Voltage Abnormal" 364 "Inside Voltage Abnormal" 363 "Inside Voltage Abnormal" 362 "Inside Voltage Abnormal" 361 "Inside Voltage Abnormal" 360 "Inside Voltage Abnormal" 359 "Inside Voltage Abnormal" 358 "Inside Voltage Abnormal" 357 "Inside Voltage Abnormal" 356 "Inside Voltage Abnormal" 355 "Inside Voltage Abnormal" 354 "Inside Voltage Abnormal" 353 "Inside Voltage Abnormal" 352 "Inside Voltage Abnormal" 351 "Inside Voltage Abnormal" 350 "Inside Voltage Abnormal" 349 "Inside Voltage Abnormal" 348 "Inside Voltage Abnormal" 347 "Inside Voltage Abnormal" 346 "Inside Voltage Abnormal" 345 "Inside Voltage Abnormal" 344 "Inside Voltage Abnormal" 343 "Inside Voltage Abnormal" 342 "Inside Voltage Abnormal" 341 "Inside Voltage Abnormal" 340 "Inside Voltage Abnormal" 339 "Inside Voltage Abnormal" 338 "Inside Voltage Abnormal" 337 "Inside Voltage Abnormal" 336 "Inside Voltage Abnormal" 335 "Inside Voltage Abnormal" 334 "Inside Voltage Abnormal" 333 "Inside Voltage Abnormal" 332 "Inside Voltage Abnormal" 331 "Inside Voltage Abnormal" 330 "Inside Voltage Abnormal" 329 "Inside Voltage Abnormal" 328 "Inside Voltage Abnormal" 327 "Inside Voltage Abnormal" 326 "Inside Voltage Abnormal" 325 "Inside Voltage Abnormal" 324 "Inside Voltage Abnormal" 323 "Inside Voltage Abnormal" 322 "Inside Voltage Abnormal" 321 "Inside Voltage Abnormal" 320 "Inside Voltage Abnormal" 319 "Inside Voltage Abnormal" 318 "Inside Voltage Abnormal" 317 "Inside Voltage Abnormal" 316 "Inside Voltage Abnormal" 315 "Inside Voltage Abnormal" 314 "Inside Voltage Abnormal" 313 "Inside Voltage Abnormal" 312 "Inside Voltage Abnormal" 311 "Inside Voltage Abnormal" 310 "Inside Voltage Abnormal" 309 "Inside Voltage Abnormal" 308 "Inside Voltage Abnormal" 307 "Inside Voltage Abnormal" 306 "Inside Voltage Abnormal" 305 "Inside Voltage Abnormal" 304 "Inside Voltage Abnormal" 303 "Inside Voltage Abnormal" 302 "Inside Voltage Abnormal" 301 "Inside Voltage Abnormal" 300 "Inside Voltage Abnormal" 299 "Inside Voltage Abnormal" 298 "Inside Voltage Abnormal" 297 "Inside Voltage Abnormal" 296 "Inside Voltage Abnormal" 295 "Inside Voltage Abnormal" 294 "Inside Voltage Abnormal" 293 "Inside Voltage Abnormal" 292 "Inside Voltage Abnormal" 291 "Inside Voltage Abnormal" 290 "Inside Voltage Abnormal" 289 "Inside Voltage Abnormal" 288 "Inside Voltage Abnormal" 287 "Inside Voltage Abnormal" 286 "Inside Voltage Abnormal" 285 "Inside Voltage Abnormal" 284 "Inside Voltage Abnormal" 283 "Inside Voltage Abnormal" 282 "Inside Voltage Abnormal" 281 "Inside Voltage Abnormal" 280 "Inside Voltage Abnormal" 279 "Inside Voltage Abnormal" 278 "Inside Voltage Abnormal" 277 "Inside Voltage Abnormal" 276 "Inside Voltage Abnormal" 275 "Inside Voltage Abnormal" 274 "Inside Voltage Abnormal" 273 "Inside Voltage Abnormal" 272 "Inside Voltage Abnormal" 271 "Inside Voltage Abnormal" 270 "Inside Voltage Abnormal" 269 "Inside Voltage Abnormal" 268 "Inside Voltage Abnormal" 267 "Inside Voltage Abnormal" 266 "Inside Voltage Abnormal" 265 "Inside Voltage Abnormal" 264 "Inside Voltage Abnormal" 263 "Inside Voltage Abnormal" 262 "Inside Voltage Abnormal" 261 "Inside Voltage Abnormal" 260 "Inside Voltage Abnormal" 259 "Inside Voltage Abnormal" 258 "Inside Voltage Abnormal" 257 "Inside Voltage Abnormal" 256 "Inside Voltage Abnormal" 255 "Inside Voltage Abnormal" 254 "Inside Voltage Abnormal" 253 "Inside Voltage Abnormal" 252 "Inside Voltage Abnormal" 251 "Inside Voltage Abnormal" 250 "Inside Voltage Abnormal" 249 "Inside Voltage Abnormal" 248 "Inside Voltage Abnormal" 247 "Inside Voltage Abnormal" 246 "Inside Voltage Abnormal" 245 "Inside Voltage Abnormal" 244 "Inside Voltage Abnormal" 243 "Inside Voltage Abnormal" 242 "Inside Voltage Abnormal" 241 "Inside Voltage Abnormal" 240 "Inside Voltage Abnormal" 239 "Inside Voltage Abnormal" 238 "Inside Voltage Abnormal" 237 "Inside Voltage Abnormal" 236 "Inside Voltage Abnormal" 235 "Inside Voltage Abnormal" 234 "Inside Voltage Abnormal" 233 "Inside Voltage Abnormal" 232 "Inside Voltage Abnormal" 231 "Inside Voltage Abnormal" 230 "Inside Voltage Abnormal" 229 "Inside Voltage Abnormal" 228 "Inside Voltage Abnormal" 227 "Inside Voltage Abnormal" 226 "Inside Voltage Abnormal" 225 "Inside Voltage Abnormal" 224 "Inside Voltage Abnormal" 223 "Inside Voltage Abnormal" 222 "Inside Voltage Abnormal" 221 "Inside Voltage Abnormal" 220 "Inside Voltage Abnormal" 219 "Inside Voltage Abnormal" 218 "Inside Voltage Abnormal" 217 "Inside Voltage Abnormal" 216 "Inside Voltage Abnormal" 215 "Inside Voltage Abnormal" 214 "Inside Voltage Abnormal" 213 "Inside Voltage Abnormal" 212 "Inside Voltage Abnormal" 211 "Inside Voltage Abnormal" 210 "Inside Voltage Abnormal" 209 "Inside Voltage Abnormal" 208 "Inside Voltage Abnormal" 207 "Inside Voltage Abnormal" 206 "Inside Voltage Abnormal" 205 "Inside Voltage Abnormal" 204 "Inside Voltage Abnormal" 203 "Inside Voltage Abnormal" 202 "Inside Voltage Abnormal" 201 "Inside Voltage Abnormal" 200 "Inside Voltage Abnormal" 199 "Inside Voltage Abnormal" 198 "Inside Voltage Abnormal" 197 "Inside Voltage Abnormal" 196 "Inside Voltage Abnormal" 195 "Inside Voltage Abnormal" 194 "Inside Voltage Abnormal" 193 "Inside Voltage Abnormal" 192 "Inside Voltage Abnormal" 191 "Inside Voltage Abnormal" 190 "Inside Voltage Abnormal" 189 "Inside Voltage Abnormal" 188 "Inside Voltage Abnormal" 187 "Inside Voltage Abnormal" 186 "Inside Voltage Abnormal" 185 "Inside Voltage Abnormal" 184 "Inside Voltage Abnormal" 183 "Inside Voltage Abnormal" 182 "Inside Voltage Abnormal" 181 "Inside Voltage Abnormal" 180 "Inside Voltage Abnormal" 179 "Inside Voltage Abnormal" 178 "Inside Voltage Abnormal" 177 "Inside Voltage Abnormal" 176 "Inside Voltage Abnormal" 175 "Inside Voltage Abnormal" 174 "Inside Voltage Abnormal" 173 "Inside Voltage Abnormal" 172 "Inside Voltage Abnormal" 171 "Inside Voltage Abnormal" 170 "Inside Voltage Abnormal" 169 "Inside Voltage Abnormal" 168 "Inside Voltage Abnormal" 167 "Inside Voltage Abnormal" 166 "Inside Voltage Abnormal" 165 "Inside Voltage Abnormal" 164 "Inside Voltage Abnormal" 163 "Inside Voltage Abnormal" 162 "Inside Voltage Abnormal" 161 "Inside Voltage Abnormal" 160 "Inside Voltage Abnormal" 159 "Inside Voltage Abnormal" 158 "Inside Voltage Abnormal" 157 "Inside Voltage Abnormal" 156 "Inside Voltage Abnormal" 155 "Inside Voltage Abnormal" 154 "Inside Voltage Abnormal" 153 "Inside Voltage Abnormal" 152 "Inside Voltage Abnormal" 151 "Inside Voltage Abnormal" 150 "Inside Voltage Abnormal" 149 "Inside Voltage Abnormal" 148 "Inside Voltage Abnormal" 147 "Inside Voltage Abnormal" 146 "Inside Voltage Abnormal" 145 "Inside Voltage Abnormal" 144 "Inside Voltage Abnormal" 143 "Inside Voltage Abnormal" 142 "Inside Voltage Abnormal" 141 "Inside Voltage Abnormal" 140 "Inside Voltage Abnormal" 139 "Inside Voltage Abnormal" 138 "Inside Voltage Abnormal" 137 "Inside Voltage Abnormal" 136 "Inside Voltage Abnormal" 135 "Inside Voltage Abnormal" 134 "Inside Voltage Abnormal" 133 "Inside Voltage Abnormal" 132 "Inside Voltage Abnormal" 131 "Inside Voltage Abnormal" 130 "Inside Voltage Abnormal" 129 "Inside Voltage Abnormal" 128 "Inside Voltage Abnormal" 127 "Inside Voltage Abnormal" 126 "Inside Voltage Abnormal" 125 "Inside Voltage Abnormal" 124 "Inside Voltage Abnormal" 123 "Inside Voltage Abnormal" 122 "Inside Voltage Abnormal" 121 "Inside Voltage Abnormal" 120 "Inside Voltage Abnormal" 119 "Inside Voltage Abnormal" 118 "Inside Voltage Abnormal" 117 "Inside Voltage Abnormal" 116 "Inside Voltage Abnormal" 115 "Inside Voltage Abnormal" 114 "Inside Voltage Abnormal" 113 "Inside Voltage Abnormal" 112 "Inside Voltage Abnormal" 111 "Inside Voltage Abnormal" 110 "Inside Voltage Abnormal" 109 "Inside Voltage Abnormal" 108 "Inside Voltage Abnormal" 107 "Inside Voltage Abnormal" 106 "Inside Voltage Abnormal" 105 "Inside Voltage Abnormal" 104 "Inside Voltage Abnormal" 103 "Inside Voltage Abnormal" 102 "Inside Voltage Abnormal" 101 "Inside Voltage Abnormal" 100 "Inside Voltage Abnormal" 99 "Inside Voltage Abnormal" 98 "Inside Voltage Abnormal" 97 "Inside Voltage Abnormal" 96 "Inside Voltage Abnormal" 95 "Inside Voltage Abnormal" 94 "Inside Voltage Abnormal" 93 "Inside Voltage Abnormal" 92 "Inside Voltage Abnormal" 91 "Inside Voltage Abnormal" 90 "Inside Voltage Abnormal" 89 "Inside Voltage Abnormal" 88 "Inside Voltage Abnormal" 87 "Inside Voltage Abnormal" 86 "Inside Voltage Abnormal" 85 "Inside Voltage Abnormal" 84 "Inside Voltage Abnormal" 83 "Inside Voltage Abnormal" 82 "Inside Voltage Abnormal" 81 "Inside Voltage Abnormal" 80 "Inside Voltage Abnormal" 79 "Inside Voltage Abnormal" 78 "Inside Voltage Abnormal" 77 "Inside Voltage Abnormal" 76 "Inside Voltage Abnormal" 75 "Inside Voltage Abnormal" 74 "Inside Voltage Abnormal" 73 "Inside Voltage Abnormal" 72 "Inside Voltage Abnormal" 71 "Inside Voltage Abnormal" 70 "Inside Voltage Abnormal" 69 "Inside Voltage Abnormal" 68 "Inside Voltage Abnormal" 67 "Inside Voltage Abnormal" 66 "Inside Voltage Abnormal" 65 "Inside Voltage Abnormal" 64 "Inside Voltage Abnormal" 63 "Inside Voltage Abnormal" 62 "Inside Voltage Abnormal" 61 "Inside Voltage Abnormal" 60 "Inside Voltage Abnormal" 59 "Inside Voltage Abnormal" 58 "Inside Voltage Abnormal" 57 "Inside Voltage Abnormal" 56 "Inside Voltage Abnormal" 55 "Inside Voltage Abnormal" 54 "Inside Voltage Abnormal" 53 "Inside Voltage Abnormal" 52 "Inside Voltage Abnormal" 51 "Inside Voltage Abnormal" 50 "Inside Voltage Abnormal" 49 "Inside Voltage Abnormal" 48 "Inside Voltage Abnormal" 47 "Inside Voltage Abnormal" 46 "Inside Voltage Abnormal" 45 "Inside Voltage Abnormal" 44 "Inside Voltage Abnormal" 43 "Inside Voltage Abnormal" 42 "Inside Voltage Abnormal" 41 "Inside Voltage Abnormal" 40 "Inside Voltage Abnormal" 39 "Inside Voltage Abnormal" 38 "Inside Voltage Abnormal" 37 "Inside Voltage Abnormal" 36 "Inside Voltage Abnormal" 35 "Inside Voltage Abnormal" 34 "Inside Voltage Abnormal" 33 "Inside Voltage Abnormal" 32 "Inside Voltage Abnormal" 31 "Inside Voltage Abnormal" 30 "Inside Voltage Abnormal" 29 "Inside Voltage Abnormal" 28 "Inside Voltage Abnormal" 27 "Inside Voltage Abnormal" 26 "Inside Voltage Abnormal" 25 "Inside Voltage Abnormal" 24 "Inside Voltage Abnormal" 23 "Inside Voltage Abnormal" 22 "Inside Voltage Abnormal" 21 "Inside Voltage Abnormal" 20 "Inside Voltage Abnormal" 19 "Inside Voltage Abnormal" 18 "Inside Voltage Abnormal" 17 "Inside Voltage Abnormal" 16 "Inside Voltage Abnormal" 15 "Inside Voltage Abnormal" 14 "Inside Voltage Abnormal" 13 "Inside Voltage Abnormal" 12 "Inside Voltage Abnormal" 11 "Inside Voltage Abnormal" 10 "Inside Voltage Abnormal" 9 "Inside Voltage Abnormal" 8 "Inside Voltage Abnormal" 7 "Inside Voltage Abnormal" 6 "Inside Voltage Abnormal" 5 "Inside Voltage Abnormal" 4 "Inside Voltage Abnormal" 3 "Inside Voltage Abnormal" 2 "Inside Voltage Abnormal" 1 "Inside Voltage Abnormal" 0 "Normal" ;
VAL_ 981 RipleyMStatus 31 "Abnormal" 30 "Abnormal" 29 "Abnormal" 28 "Abnormal" 27 "Abnormal" 26 "Abnormal" 25 "Abnormal" 24 "Abnormal" 23 "Abnormal" 22 "Abnormal" 21 "Abnormal" 20 "Abnormal" 19 "Abnormal" 18 "Abnormal" 17 "Abnormal" 16 "Abnormal" 15 "Abnormal" 14 "Abnormal" 13 "Abnormal" 12 "Abnormal" 11 "Abnormal" 10 "Abnormal" 9 "Abnormal" 8 "Abnormal" 7 "Abnormal" 6 "Abnormal" 5 "Abnormal" 4 "Abnormal" 3 "Abnormal" 2 "Abnormal" 1 "Abnormal" 0 "Normal" ;
VAL_ 981 RipleySStatus 31 "Abnormal" 30 "Abnormal" 29 "Abnormal" 28 "Abnormal" 27 "Abnormal" 26 "Abnormal" 25 "Abnormal" 24 "Abnormal" 23 "Abnormal" 22 "Abnormal" 21 "Abnormal" 20 "Abnormal" 19 "Abnormal" 18 "Abnormal" 17 "Abnormal" 16 "Abnormal" 15 "Abnormal" 14 "Abnormal" 13 "Abnormal" 12 "Abnormal" 11 "Abnormal" 10 "Abnormal" 9 "Abnormal" 8 "Abnormal" 7 "Abnormal" 6 "Abnormal" 5 "Abnormal" 4 "Abnormal" 3 "Abnormal" 2 "Abnormal" 1 "Abnormal" 0 "Normal" ;
VAL_ 982 GnssAbnormal 1 "Abnormal" 0 "Normal" ;
VAL_ 982 TimeCalibrationStatus 2 "Fine Calibration, Small Clock Deviation" 1 "Rough Calibration, Large Clock Deviation" 0 "Not Calibrated" ;
VAL_ 983 InsResolve 11 "Inertial Navigation Mode (IMU)" 10 "INS Mode 9 (IMU+SPD)" 9 "INS Mode 8 (IMU+RTKFLOAT)" 8 "INS Mode 7 (IMU+RTKFIX)" 7 "INS Mode 6 (IMU+DGPS)" 6 "INS Mode 5 (IMU+SINGLE)" 5 "INS Mode 4 (IMU+RTKFLOAT+SPD)" 4 "INS Mode 3 (IMU+RTKFIX+SPD)" 3 "INS Mode 2 (IMU+DGPS+SPD)" 2 "INS Mode 1 (IMU+SINGLE+SPD)" 1 "Initiating" 0 "INACTIVE" ;
VAL_ 983 InsAbnormal 1 "Abnormal" 0 "Normal" ;
VAL_ 983 ImuCali 1 "Not Calibrated" 0 "Calibrated" ;
VAL_ 983 ImuDataStatus_GYROX 1 "Abnormal" 0 "Normal" ;
VAL_ 983 ImuDataStatus_GYROY 1 "Abnormal" 0 "Normal" ;
VAL_ 983 ImuDataStatus_GYROZ 1 "Abnormal" 0 "Normal" ;
VAL_ 983 ImuDataStatus_ACCLX 1 "Abnormal" 0 "Normal" ;
VAL_ 983 ImuDataStatus_ACCLY 1 "Abnormal" 0 "Normal" ;
VAL_ 983 ImuDataStatus_ACCLZ 1 "Abnormal" 0 "Normal" ;
VAL_ 983 ImuDataStatus_TEMP 1 "Abnormal" 0 "Normal" ;
VAL_ 983 ImuDataStatus_TIME 1 "Abnormal" 0 "Normal" ;
VAL_ 983 ImuChipStatus 255 "Abnormal" 254 "Abnormal" 253 "Abnormal" 252 "Abnormal" 251 "Abnormal" 250 "Abnormal" 249 "Abnormal" 248 "Abnormal" 247 "Abnormal" 246 "Abnormal" 245 "Abnormal" 244 "Abnormal" 243 "Abnormal" 242 "Abnormal" 241 "Abnormal" 240 "Abnormal" 239 "Abnormal" 238 "Abnormal" 237 "Abnormal" 236 "Abnormal" 235 "Abnormal" 234 "Abnormal" 233 "Abnormal" 232 "Abnormal" 231 "Abnormal" 230 "Abnormal" 229 "Abnormal" 228 "Abnormal" 227 "Abnormal" 226 "Abnormal" 225 "Abnormal" 224 "Abnormal" 223 "Abnormal" 222 "Abnormal" 221 "Abnormal" 220 "Abnormal" 219 "Abnormal" 218 "Abnormal" 217 "Abnormal" 216 "Abnormal" 215 "Abnormal" 214 "Abnormal" 213 "Abnormal" 212 "Abnormal" 211 "Abnormal" 210 "Abnormal" 209 "Abnormal" 208 "Abnormal" 207 "Abnormal" 206 "Abnormal" 205 "Abnormal" 204 "Abnormal" 203 "Abnormal" 202 "Abnormal" 201 "Abnormal" 200 "Abnormal" 199 "Abnormal" 198 "Abnormal" 197 "Abnormal" 196 "Abnormal" 195 "Abnormal" 194 "Abnormal" 193 "Abnormal" 192 "Abnormal" 191 "Abnormal" 190 "Abnormal" 189 "Abnormal" 188 "Abnormal" 187 "Abnormal" 186 "Abnormal" 185 "Abnormal" 184 "Abnormal" 183 "Abnormal" 182 "Abnormal" 181 "Abnormal" 180 "Abnormal" 179 "Abnormal" 178 "Abnormal" 177 "Abnormal" 176 "Abnormal" 175 "Abnormal" 174 "Abnormal" 173 "Abnormal" 172 "Abnormal" 171 "Abnormal" 170 "Abnormal" 169 "Abnormal" 168 "Abnormal" 167 "Abnormal" 166 "Abnormal" 165 "Abnormal" 164 "Abnormal" 163 "Abnormal" 162 "Abnormal" 161 "Abnormal" 160 "Abnormal" 159 "Abnormal" 158 "Abnormal" 157 "Abnormal" 156 "Abnormal" 155 "Abnormal" 154 "Abnormal" 153 "Abnormal" 152 "Abnormal" 151 "Abnormal" 150 "Abnormal" 149 "Abnormal" 148 "Abnormal" 147 "Abnormal" 146 "Abnormal" 145 "Abnormal" 144 "Abnormal" 143 "Abnormal" 142 "Abnormal" 141 "Abnormal" 140 "Abnormal" 139 "Abnormal" 138 "Abnormal" 137 "Abnormal" 136 "Abnormal" 135 "Abnormal" 134 "Abnormal" 133 "Abnormal" 132 "Abnormal" 131 "Abnormal" 130 "Abnormal" 129 "Abnormal" 128 "Abnormal" 127 "Abnormal" 126 "Abnormal" 125 "Abnormal" 124 "Abnormal" 123 "Abnormal" 122 "Abnormal" 121 "Abnormal" 120 "Abnormal" 119 "Abnormal" 118 "Abnormal" 117 "Abnormal" 116 "Abnormal" 115 "Abnormal" 114 "Abnormal" 113 "Abnormal" 112 "Abnormal" 111 "Abnormal" 110 "Abnormal" 109 "Abnormal" 108 "Abnormal" 107 "Abnormal" 106 "Abnormal" 105 "Abnormal" 104 "Abnormal" 103 "Abnormal" 102 "Abnormal" 101 "Abnormal" 100 "Abnormal" 99 "Abnormal" 98 "Abnormal" 97 "Abnormal" 96 "Abnormal" 95 "Abnormal" 94 "Abnormal" 93 "Abnormal" 92 "Abnormal" 91 "Abnormal" 90 "Abnormal" 89 "Abnormal" 88 "Abnormal" 87 "Abnormal" 86 "Abnormal" 85 "Abnormal" 84 "Abnormal" 83 "Abnormal" 82 "Abnormal" 81 "Abnormal" 80 "Abnormal" 79 "Abnormal" 78 "Abnormal" 77 "Abnormal" 76 "Abnormal" 75 "Abnormal" 74 "Abnormal" 73 "Abnormal" 72 "Abnormal" 71 "Abnormal" 70 "Abnormal" 69 "Abnormal" 68 "Abnormal" 67 "Abnormal" 66 "Abnormal" 65 "Abnormal" 64 "Abnormal" 63 "Abnormal" 62 "Abnormal" 61 "Abnormal" 60 "Abnormal" 59 "Abnormal" 58 "Abnormal" 57 "Abnormal" 56 "Abnormal" 55 "Abnormal" 54 "Abnormal" 53 "Abnormal" 52 "Abnormal" 51 "Abnormal" 50 "Abnormal" 49 "Abnormal" 48 "Abnormal" 47 "Abnormal" 46 "Abnormal" 45 "Abnormal" 44 "Abnormal" 43 "Abnormal" 42 "Abnormal" 41 "Abnormal" 40 "Abnormal" 39 "Abnormal" 38 "Abnormal" 37 "Abnormal" 36 "Abnormal" 35 "Abnormal" 34 "Abnormal" 33 "Abnormal" 32 "Abnormal" 31 "Abnormal" 30 "Abnormal" 29 "Abnormal" 28 "Abnormal" 27 "Abnormal" 26 "Abnormal" 25 "Abnormal" 24 "Abnormal" 23 "Abnormal" 22 "Abnormal" 21 "Abnormal" 20 "Abnormal" 19 "Abnormal" 18 "Abnormal" 17 "Abnormal" 16 "Abnormal" 15 "Abnormal" 14 "Abnormal" 13 "Abnormal" 12 "Abnormal" 11 "Abnormal" 10 "Abnormal" 9 "Abnormal" 8 "Abnormal" 7 "Abnormal" 6 "Abnormal" 5 "Abnormal" 4 "Abnormal" 3 "Abnormal" 2 "Abnormal" 1 "Abnormal" 0 "Normal" ;
